VERSION ""

NS_ :

BS_:

BU_: CGM_HS TCM_HS RDCM_HS EPS_HS ECM_HS EBCM_HS BSM_HS BCM_HS

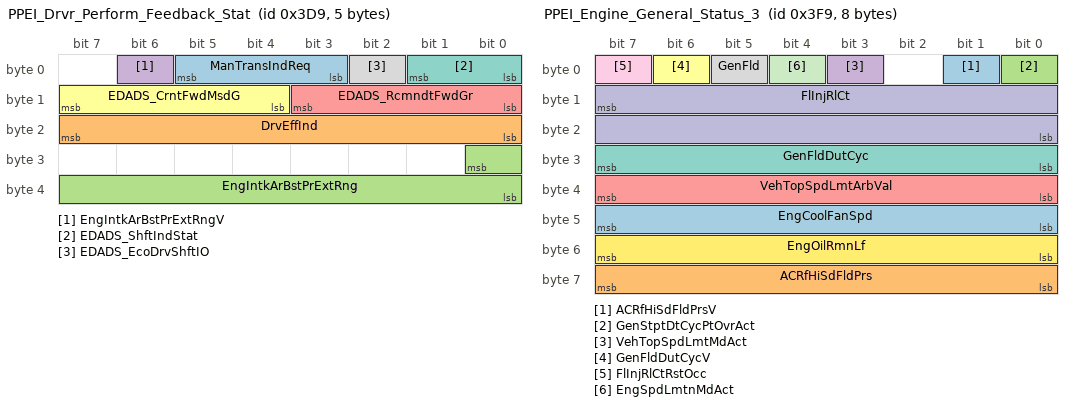
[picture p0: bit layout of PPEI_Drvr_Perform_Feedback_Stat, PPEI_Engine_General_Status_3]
BO_ 985 PPEI_Drvr_Perform_Feedback_Stat: 5 ECM_HS
 SG_ ManTransIndReq : 5|3@0+ (1,0) [0|7] ""  CGM_HS,BCM_HS
 SG_ DrvEffInd : 23|8@0- (0.78125,0) [-100|99.21875] "%"  CGM_HS,BCM_HS
 SG_ EngIntkArBstPrExtRng : 24|9@0+ (1,-110) [-110|401] "kPa"  CGM_HS,BCM_HS
 SG_ EngIntkArBstPrExtRngV : 6|1@0+ (1,0) [0|1] ""  CGM_HS,BCM_HS
 SG_ EDADS_RcmndtFwdGr : 11|4@0+ (1,0) [0|15] ""  CGM_HS,BCM_HS
 SG_ EDADS_CrntFwdMsdG : 15|4@0+ (1,0) [0|15] ""  CGM_HS,BCM_HS
 SG_ EDADS_ShftIndStat : 1|2@0+ (1,0) [0|3] ""  CGM_HS,BCM_HS
 SG_ EDADS_EcoDrvShftIO : 2|1@0+ (1,0) [0|1] ""  CGM_HS,BCM_HS

BO_ 1017 PPEI_Engine_General_Status_3: 8 ECM_HS
 SG_ ACRfHiSdFldPrsV : 1|1@0+ (1,0) [0|1] ""  CGM_HS,BSM_HS,BCM_HS
 SG_ ACRfHiSdFldPrs : 63|8@0+ (14,0) [0|3570] "kPaG"  CGM_HS,BSM_HS,BCM_HS
 SG_ GenStptDtCycPtOvrAct : 0|1@0+ (1,0) [0|1] ""  CGM_HS,BCM_HS
 SG_ VehTopSpdLmtMdAct : 3|1@0+ (1,0) [0|1] ""  CGM_HS,BCM_HS
 SG_ VehTopSpdLmtArbVal : 39|8@0+ (2,0) [0|510] "km / h"  CGM_HS,BCM_HS
 SG_ GenFldDutCycV : 6|1@0+ (1,0) [0|1] ""  CGM_HS,BCM_HS
 SG_ GenFldDutCyc : 31|8@0+ (0.392157,0) [0|100.000035] "%"  CGM_HS,BCM_HS
 SG_ GenFld : 5|1@0+ (1,0) [0|1] ""  CGM_HS,BCM_HS
 SG_ FlInjRlCtRstOcc : 7|1@0+ (1,0) [0|1] ""  CGM_HS,BSM_HS,BCM_HS
 SG_ FlInjRlCt : 15|16@0+ (3.05176E-005,0) [0|1.999970916] "liters"  CGM_HS,BSM_HS,BCM_HS
 SG_ EngSpdLmtnMdAct : 4|1@0+ (1,0) [0|1] ""  CGM_HS,BCM_HS
 SG_ EngOilRmnLf : 55|8@0+ (0.392157,0) [0|100.000035] "%"  CGM_HS,BCM_HS
 SG_ EngCoolFanSpd : 47|8@0+ (0.392157,0) [0|100.000035] "%"  CGM_HS,BSM_HS,BCM_HS

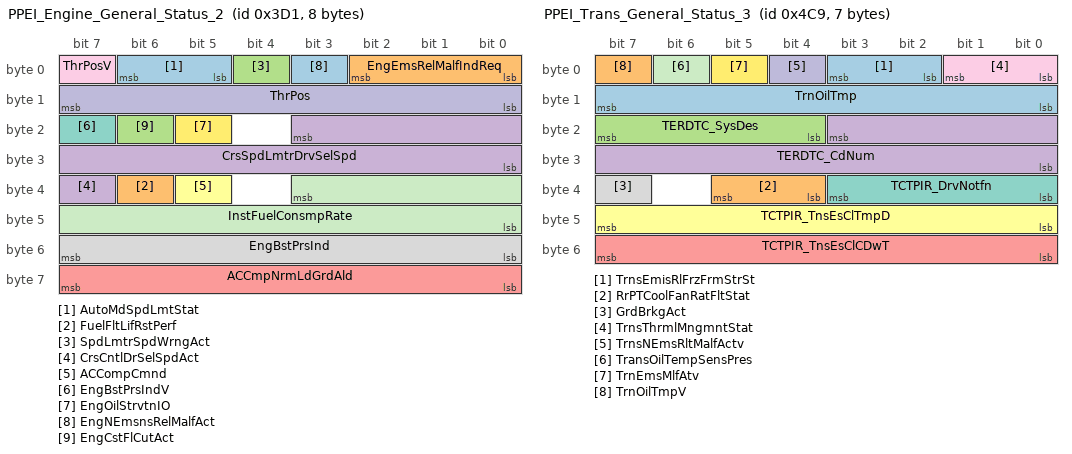
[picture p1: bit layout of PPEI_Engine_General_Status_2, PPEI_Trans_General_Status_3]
BO_ 977 PPEI_Engine_General_Status_2: 8 ECM_HS
 SG_ AutoMdSpdLmtStat : 6|2@0+ (1,0) [0|3] ""  CGM_HS,BCM_HS
 SG_ FuelFltLifRstPerf : 38|1@0+ (1,0) [0|1] ""  CGM_HS,BCM_HS
 SG_ SpdLmtrSpdWrngAct : 4|1@0+ (1,0) [0|1] ""  CGM_HS,BCM_HS
 SG_ CrsCntlDrSelSpdAct : 39|1@0+ (1,0) [0|1] ""  CGM_HS,BCM_HS
 SG_ ACCmpNrmLdGrdAld : 63|8@0+ (0.1,0) [0|25.5] "dm3/m/s"  CGM_HS,BCM_HS
 SG_ ACCompCmnd : 37|1@0+ (1,0) [0|1] ""  CGM_HS,TCM_HS,BCM_HS
 SG_ EngBstPrsIndV : 23|1@0+ (1,0) [0|1] ""  CGM_HS,BCM_HS
 SG_ EngBstPrsInd : 55|8@0+ (0.392157,0) [0|100.000035] "%"  CGM_HS,BCM_HS
 SG_ ThrPosV : 7|1@0+ (1,0) [0|1] ""  CGM_HS,BCM_HS
 SG_ ThrPos : 15|8@0+ (0.392157,0) [0|100.000035] "%"  CGM_HS,BCM_HS
 SG_ InstFuelConsmpRate : 35|12@0+ (0.025,0) [0|102.375] "ltrs/hr"  CGM_HS,BCM_HS
 SG_ EngOilStrvtnIO : 21|1@0+ (1,0) [0|1] ""  CGM_HS,BCM_HS
 SG_ EngNEmsnsRelMalfAct : 3|1@0+ (1,0) [0|1] ""  CGM_HS,BCM_HS
 SG_ EngEmsRelMalfIndReq : 2|3@0+ (1,0) [0|7] ""  CGM_HS,BCM_HS
 SG_ EngCstFlCutAct : 22|1@0+ (1,0) [0|1] ""  CGM_HS,TCM_HS,BSM_HS,BCM_HS
 SG_ CrsSpdLmtrDrvSelSpd : 19|12@0+ (0.0625,0) [0|255.9375] "km / h"  CGM_HS,TCM_HS,BCM_HS

BO_ 201 PPEI_Engine_General_Status_1: 8 ECM_HS
 SG_ EngCylDactEvntPndg : 54|1@0+ (1,0) [0|1] ""  CGM_HS
 SG_ DrThrtlOvrrdDetProtVal : 25|2@0+ (1,0) [0|3] ""  CGM_HS,EBCM_HS
 SG_ DrThrtlOvrdDetAlvRlCnt : 27|2@0+ (1,0) [0|3] ""  CGM_HS,EBCM_HS
 SG_ PT_BrkPedDscrtInpStatV : 41|1@0+ (1,0) [0|1] ""  CGM_HS,TCM_HS,EBCM_HS
 SG_ PT_BrkPedDscrtInpStat : 40|1@0+ (1,0) [0|1] ""  CGM_HS,TCM_HS,EBCM_HS
 SG_ PT_CrnkAct : 6|1@0+ (1,0) [0|1] ""  CGM_HS,EPS_HS,EBCM_HS,BSM_HS
 SG_ Eng12vStrtrMtrCmmdOn : 53|1@0+ (1,0) [0|1] ""  CGM_HS,TCM_HS,RDCM_HS,EPS_HS,EBCM_HS,BCM_HS
 SG_ EngCntrlRunCrnkTrmSt : 52|1@0+ (1,0) [0|1] ""  CGM_HS,TCM_HS,EBCM_HS,BSM_HS,BCM_HS
 SG_ EngAirIntBstPrV : 51|1@0+ (1,0) [0|1] ""  CGM_HS,EBCM_HS,BCM_HS
 SG_ EngAirIntBstPr : 63|8@0- (1,0) [-128|127] "kPaG"  CGM_HS,EBCM_HS,BCM_HS
 SG_ SpdLmtrSpdWrngEnbld : 47|1@0+ (1,0) [0|1] ""  CGM_HS,BCM_HS
 SG_ EngCylDeactMd : 43|2@0+ (1,0) [0|3] ""  CGM_HS,RDCM_HS,BCM_HS
 SG_ RmVhStrtEngRng : 55|1@0+ (1,0) [0|1] ""  CGM_HS,EBCM_HS,BCM_HS
 SG_ PFEngSpdCmndSpcd : 45|1@0+ (1,0) [0|1] ""  CGM_HS,BCM_HS
 SG_ PltfrmEngSpdCmdInhtRq : 44|1@0+ (1,0) [0|1] ""  CGM_HS,BCM_HS
 SG_ AccActPos : 39|8@0+ (0.392157,0) [0|100.000035] "%"  CGM_HS,TCM_HS,RDCM_HS,EBCM_HS,BSM_HS,BCM_HS
 SG_ CrsCntEnbld : 29|1@0+ (1,0) [0|1] ""  CGM_HS,EBCM_HS,BCM_HS
 SG_ CrsCntAtv : 30|1@0+ (1,0) [0|1] ""  CGM_HS,TCM_HS,RDCM_HS,EBCM_HS,BCM_HS
 SG_ DrvThrottlOvrrdDet : 28|1@0+ (1,0) [0|1] ""  CGM_HS,EBCM_HS,BCM_HS
 SG_ PTRunAbrt : 4|1@0+ (1,0) [0|1] ""  CGM_HS,BCM_HS
 SG_ PTO_PT_RunAbrtd : 3|1@0+ (1,0) [0|1] ""  CGM_HS,BCM_HS
 SG_ PTCrnkAbrted : 5|1@0+ (1,0) [0|1] ""  CGM_HS,BCM_HS
 SG_ EngSpdStat : 1|2@0+ (1,0) [0|3] ""  CGM_HS,TCM_HS,RDCM_HS,EPS_HS,EBCM_HS,BSM_HS,BCM_HS
 SG_ EngSpd : 15|16@0+ (0.25,0) [0|16383.75] "rpm"  CGM_HS,TCM_HS,RDCM_HS,EPS_HS,EBCM_HS,BSM_HS,BCM_HS
 SG_ EngRunAtv : 7|1@0+ (1,0) [0|1] ""  CGM_HS,RDCM_HS,EPS_HS,EBCM_HS,BSM_HS,BCM_HS
 SG_ EngIdlAtv : 2|1@0+ (1,0) [0|1] ""  CGM_HS,BCM_HS
 SG_ AccActPosV : 31|1@0+ (1,0) [0|1] ""  CGM_HS,TCM_HS,RDCM_HS,EBCM_HS,BSM_HS,BCM_HS

BO_ 501 PPEI_Trans_General_Status_2: 8 TCM_HS
 SG_ TrnsPattSelEcnMdOCm : 52|1@0+ (1,0) [0|1] ""  CGM_HS,ECM_HS
 SG_ TrnsFldPrsPrsnt : 51|1@0+ (1,0) [0|1] ""  CGM_HS,ECM_HS
 SG_ TrnsTrqCnvCltCmndMd : 7|3@0+ (1,0) [0|7] ""  CGM_HS,ECM_HS
 SG_ CltchPdlActPosV : 55|1@0+ (1,0) [0|1] ""  CGM_HS,RDCM_HS,ECM_HS,EBCM_HS
 SG_ CltchPdlActPos : 63|8@0+ (0.392157,0) [0|100.000035] "%"  CGM_HS,RDCM_HS,ECM_HS,EBCM_HS
 SG_ AutoTransGrSftDirect : 13|2@0+ (1,0) [0|3] ""  CGM_HS,RDCM_HS,ECM_HS,EBCM_HS
 SG_ ElcRngSelDrvAct : 39|1@0+ (1,0) [0|1] ""  CGM_HS,BCM_HS
 SG_ TmpDrvrShftCtlAct : 45|1@0+ (1,0) [0|1] ""  CGM_HS,BCM_HS
 SG_ EngRecDwnshftIO : 54|1@0+ (1,0) [0|1] ""  CGM_HS,BCM_HS
 SG_ CltStartSwAtvV : 38|1@0+ (1,0) [0|1] ""  CGM_HS,RDCM_HS,BCM_HS
 SG_ CltStartSwAtv : 37|1@0+ (1,0) [0|1] ""  CGM_HS,RDCM_HS,BCM_HS
 SG_ PropSysBrkLitsReqd : 53|1@0+ (1,0) [0|1] ""  CGM_HS,BCM_HS
 SG_ TrnsEngdStateV : 50|1@0+ (1,0) [0|1] ""  CGM_HS,RDCM_HS,EBCM_HS,BCM_HS
 SG_ TrnsEngdState : 49|2@0+ (1,0) [0|3] ""  CGM_HS,RDCM_HS,EBCM_HS,BCM_HS
 SG_ TrnsShftLvrLckRqd : 47|1@0+ (1,0) [0|1] ""  CGM_HS,BCM_HS
 SG_ TransTUDMdStat : 41|2@0+ (1,0) [0|3] ""  CGM_HS,ECM_HS,EBCM_HS,BCM_HS
 SG_ TrnCrpMdAtv : 46|1@0+ (1,0) [0|1] ""  CGM_HS,ECM_HS,BCM_HS
 SG_ TrnsSkpShftIO : 23|1@0+ (1,0) [0|1] ""  CGM_HS,BCM_HS
 SG_ TrnsSftMdStat : 34|3@0+ (1,0) [0|7] ""  CGM_HS,EBCM_HS,BCM_HS
 SG_ TrnsRngInhbtStat : 31|3@0+ (1,0) [0|7] ""  CGM_HS,BCM_HS
 SG_ TopTrvlCltchSwActV : 15|1@0+ (1,0) [0|1] ""  CGM_HS,RDCM_HS,EBCM_HS,BCM_HS
 SG_ TopTrvlCltchSwAct : 14|1@0+ (1,0) [0|1] ""  CGM_HS,RDCM_HS,EBCM_HS,BCM_HS
 SG_ EngRecmndUpshftIO : 22|1@0+ (1,0) [0|1] ""  CGM_HS,BCM_HS
 SG_ DrvtShftCntrlTrgtGear : 19|4@0+ (1,0) [0|15] ""  CGM_HS,BCM_HS
 SG_ DrShftCntrlReqDndIO : 21|1@0+ (1,0) [0|1] ""  CGM_HS,BCM_HS
 SG_ TrnShftPtrnActStat : 44|3@0+ (1,0) [0|7] ""  CGM_HS,EPS_HS,EBCM_HS,BCM_HS
 SG_ TrnsShftLvrPos : 27|4@0+ (1,0) [0|15] ""  CGM_HS,RDCM_HS,EPS_HS,ECM_HS,EBCM_HS,BSM_HS,BCM_HS
 SG_ TrnsShftLvrPosV : 28|1@0+ (1,0) [0|1] ""  CGM_HS,RDCM_HS,EPS_HS,ECM_HS,EBCM_HS,BSM_HS,BCM_HS
 SG_ AutoTransComndGear : 11|4@0+ (1,0) [0|15] ""  CGM_HS,RDCM_HS,ECM_HS,EBCM_HS,BCM_HS
 SG_ TransEstGear : 3|4@0+ (1,0) [0|15] ""  CGM_HS,RDCM_HS,EPS_HS,ECM_HS,EBCM_HS,BCM_HS
 SG_ TransEstGearV : 4|1@0+ (1,0) [0|1] ""  CGM_HS,RDCM_HS,EPS_HS,ECM_HS,EBCM_HS,BCM_HS

BO_ 1225 PPEI_Trans_General_Status_3: 7 TCM_HS
 SG_ TrnsEmisRlFrzFrmStrSt : 3|2@0+ (1,0) [0|3] ""  CGM_HS,ECM_HS
 SG_ RrPTCoolFanRatFltStat : 37|2@0+ (1,0) [0|3] ""  CGM_HS
 SG_ TERDTC_SysDes : 23|4@0+ (1,0) [0|15] ""  CGM_HS,ECM_HS
 SG_ TERDTC_CdNum : 19|12@0+ (1,0) [0|4095] ""  CGM_HS,ECM_HS
 SG_ TCTPIR_TnsEsClCDwT : 55|8@0+ (0.392157,0) [0|100.000035] "%"  CGM_HS,BCM_HS
 SG_ TCTPIR_TnsEsClTmpD : 47|8@0+ (0.392157,0) [0|100.000035] "%"  CGM_HS,BCM_HS
 SG_ TCTPIR_DrvNotfn : 35|4@0+ (1,0) [0|15] ""  CGM_HS,BCM_HS
 SG_ GrdBrkgAct : 39|1@0+ (1,0) [0|1] ""  CGM_HS,BCM_HS
 SG_ TrnsThrmlMngmntStat : 1|2@0+ (1,0) [0|3] ""  CGM_HS,BCM_HS
 SG_ TrnsNEmsRltMalfActv : 4|1@0+ (1,0) [0|1] ""  CGM_HS,BCM_HS
 SG_ TransOilTempSensPres : 6|1@0+ (1,0) [0|1] ""  CGM_HS,BSM_HS,BCM_HS
 SG_ TrnEmsMlfAtv : 5|1@0+ (1,0) [0|1] ""  CGM_HS,ECM_HS,BCM_HS
 SG_ TrnOilTmp : 15|8@0+ (1,-40) [-40|215] "deg C"  CGM_HS,ECM_HS,BSM_HS,BCM_HS
 SG_ TrnOilTmpV : 7|1@0+ (1,0) [0|1] ""  CGM_HS,ECM_HS,BSM_HS,BCM_HS

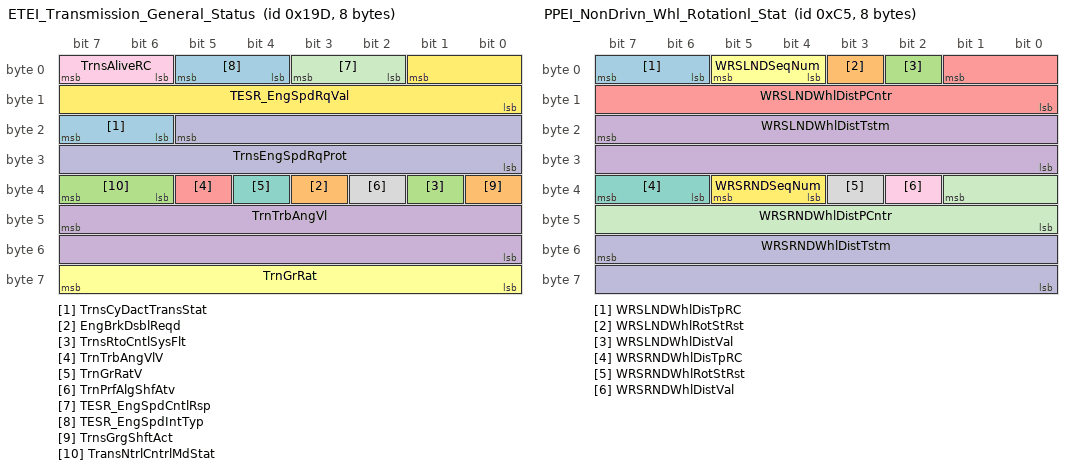
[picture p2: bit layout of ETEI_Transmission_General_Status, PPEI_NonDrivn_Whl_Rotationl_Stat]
BO_ 413 ETEI_Transmission_General_Status: 8 TCM_HS
 SG_ TrnsCyDactTransStat : 23|2@0+ (1,0) [0|3] ""  CGM_HS,ECM_HS
 SG_ EngBrkDsblReqd : 35|1@0+ (1,0) [0|1] ""  CGM_HS,ECM_HS
 SG_ TrnsRtoCntlSysFlt : 33|1@0+ (1,0) [0|1] ""  CGM_HS,ECM_HS
 SG_ TrnTrbAngVl : 47|16@0+ (0.25,0) [0|16383.75] "rpm"  CGM_HS,ECM_HS
 SG_ TrnTrbAngVlV : 37|1@0+ (1,0) [0|1] ""  CGM_HS,ECM_HS
 SG_ TrnGrRat : 63|8@0+ (0.03125,0) [0|7.96875] ""  CGM_HS,ECM_HS
 SG_ TrnGrRatV : 36|1@0+ (1,0) [0|1] ""  CGM_HS,ECM_HS
 SG_ TrnPrfAlgShfAtv : 34|1@0+ (1,0) [0|1] ""  CGM_HS,ECM_HS
 SG_ TrnsAliveRC : 7|2@0+ (1,0) [0|3] ""  CGM_HS,ECM_HS
 SG_ TrnsEngSpdRqProt : 21|14@0+ (1,0) [0|16383] ""  CGM_HS,ECM_HS
 SG_ TESR_EngSpdCntlRsp : 3|2@0+ (1,0) [0|3] ""  CGM_HS,ECM_HS
 SG_ TESR_EngSpdRqVal : 1|10@0+ (8,0) [0|8184] "rpm"  CGM_HS,ECM_HS
 SG_ TESR_EngSpdIntTyp : 5|2@0+ (1,0) [0|3] ""  CGM_HS,ECM_HS
 SG_ TrnsGrgShftAct : 32|1@0+ (1,0) [0|1] ""  CGM_HS,ECM_HS
 SG_ TransNtrlCntrlMdStat : 39|2@0+ (1,0) [0|3] ""  CGM_HS,ECM_HS,EBCM_HS,BCM_HS

BO_ 257 USDT_Req_to_All_HS_ECUs: 8 CGM_HS
 SG_ DgnInf : 7|64@0+ (1,0) [0|1.84467440737096E+019] ""  TCM_HS,RDCM_HS,ECM_HS,EPS_HS,EBCM_HS,BSM_HS,BCM_HS

BO_ 197 PPEI_NonDrivn_Whl_Rotationl_Stat: 8 EBCM_HS
 SG_ WRSLNDWhlDisTpRC : 7|2@0+ (1,0) [0|3] "counts"  CGM_HS,TCM_HS,RDCM_HS,ECM_HS,EPS_HS,BCM_HS
 SG_ WRSLNDWhlRotStRst : 3|1@0+ (1,0) [0|1] ""  CGM_HS,TCM_HS,RDCM_HS,ECM_HS,EPS_HS,BCM_HS
 SG_ WRSLNDWhlDistVal : 2|1@0+ (1,0) [0|1] ""  CGM_HS,TCM_HS,RDCM_HS,ECM_HS,EPS_HS,BCM_HS
 SG_ WRSLNDWhlDistTstm : 23|16@0+ (1,0) [0|65535] "counts"  CGM_HS,TCM_HS,RDCM_HS,ECM_HS,EPS_HS,BCM_HS
 SG_ WRSLNDWhlDistPCntr : 1|10@0+ (1,0) [0|1023] "counts"  CGM_HS,TCM_HS,RDCM_HS,ECM_HS,EPS_HS,BCM_HS
 SG_ WRSLNDSeqNum : 5|2@0+ (1,0) [0|3] "counts"  CGM_HS,TCM_HS,RDCM_HS,ECM_HS,EPS_HS,BCM_HS
 SG_ WRSRNDWhlDisTpRC : 39|2@0+ (1,0) [0|3] "counts"  CGM_HS,TCM_HS,RDCM_HS,ECM_HS,EPS_HS,BCM_HS
 SG_ WRSRNDWhlRotStRst : 35|1@0+ (1,0) [0|1] ""  CGM_HS,TCM_HS,RDCM_HS,ECM_HS,EPS_HS,BCM_HS
 SG_ WRSRNDWhlDistVal : 34|1@0+ (1,0) [0|1] ""  CGM_HS,TCM_HS,RDCM_HS,ECM_HS,EPS_HS,BCM_HS
 SG_ WRSRNDWhlDistTstm : 55|16@0+ (1,0) [0|65535] "counts"  CGM_HS,TCM_HS,RDCM_HS,ECM_HS,EPS_HS,BCM_HS
 SG_ WRSRNDWhlDistPCntr : 33|10@0+ (1,0) [0|1023] "counts"  CGM_HS,TCM_HS,RDCM_HS,ECM_HS,EPS_HS,BCM_HS
 SG_ WRSRNDSeqNum : 37|2@0+ (1,0) [0|3] "counts"  CGM_HS,TCM_HS,RDCM_HS,ECM_HS,EPS_HS,BCM_HS

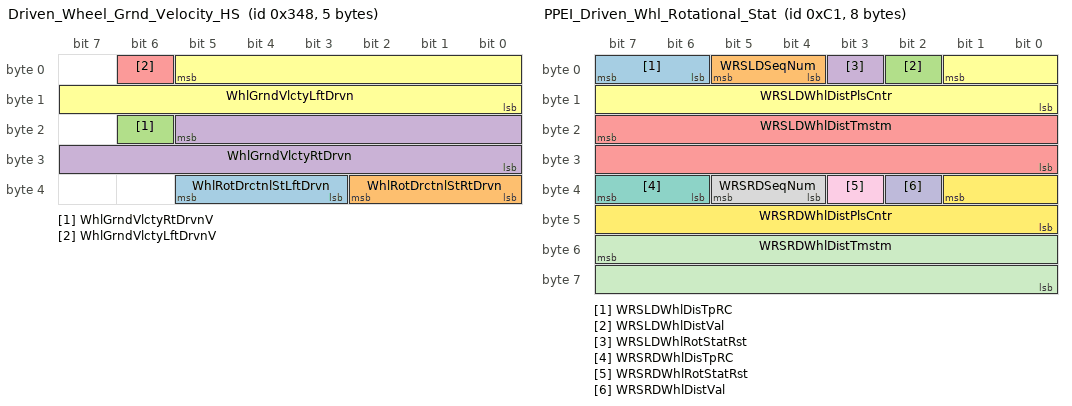
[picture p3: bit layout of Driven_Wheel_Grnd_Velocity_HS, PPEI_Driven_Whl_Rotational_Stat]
BO_ 840 Driven_Wheel_Grnd_Velocity_HS: 5 EBCM_HS
 SG_ WhlRotDrctnlStLftDrvn : 37|3@0+ (1,0) [0|7] ""  CGM_HS,EPS_HS
 SG_ WhlRotDrctnlStRtDrvn : 34|3@0+ (1,0) [0|7] ""  CGM_HS,EPS_HS
 SG_ WhlGrndVlctyRtDrvnV : 22|1@0+ (1,0) [0|1] ""  CGM_HS,RDCM_HS,EPS_HS,BCM_HS
 SG_ WhlGrndVlctyRtDrvn : 21|14@0+ (0.03125,0) [0|511.96875] "km / h"  CGM_HS,RDCM_HS,EPS_HS,BCM_HS
 SG_ WhlGrndVlctyLftDrvnV : 6|1@0+ (1,0) [0|1] ""  CGM_HS,RDCM_HS,EPS_HS,BCM_HS
 SG_ WhlGrndVlctyLftDrvn : 5|14@0+ (0.03125,0) [0|511.96875] "km / h"  CGM_HS,RDCM_HS,EPS_HS,BCM_HS

BO_ 193 PPEI_Driven_Whl_Rotational_Stat: 8 EBCM_HS
 SG_ WRSLDWhlDisTpRC : 7|2@0+ (1,0) [0|3] "counts"  CGM_HS,TCM_HS,RDCM_HS,ECM_HS,EPS_HS,BCM_HS
 SG_ WRSLDSeqNum : 5|2@0+ (1,0) [0|3] "counts"  CGM_HS,TCM_HS,RDCM_HS,ECM_HS,EPS_HS,BCM_HS
 SG_ WRSLDWhlDistVal : 2|1@0+ (1,0) [0|1] ""  CGM_HS,TCM_HS,RDCM_HS,ECM_HS,EPS_HS,BCM_HS
 SG_ WRSLDWhlRotStatRst : 3|1@0+ (1,0) [0|1] ""  CGM_HS,TCM_HS,RDCM_HS,ECM_HS,EPS_HS,BCM_HS
 SG_ WRSLDWhlDistTmstm : 23|16@0+ (1,0) [0|65535] "counts"  CGM_HS,TCM_HS,RDCM_HS,ECM_HS,EPS_HS,BCM_HS
 SG_ WRSLDWhlDistPlsCntr : 1|10@0+ (1,0) [0|1023] "counts"  CGM_HS,TCM_HS,RDCM_HS,ECM_HS,EPS_HS,BCM_HS
 SG_ WRSRDWhlDisTpRC : 39|2@0+ (1,0) [0|3] "counts"  CGM_HS,TCM_HS,RDCM_HS,ECM_HS,EPS_HS,BCM_HS
 SG_ WRSRDSeqNum : 37|2@0+ (1,0) [0|3] "counts"  CGM_HS,TCM_HS,RDCM_HS,ECM_HS,EPS_HS,BCM_HS
 SG_ WRSRDWhlRotStatRst : 35|1@0+ (1,0) [0|1] ""  CGM_HS,TCM_HS,RDCM_HS,ECM_HS,EPS_HS,BCM_HS
 SG_ WRSRDWhlDistVal : 34|1@0+ (1,0) [0|1] ""  CGM_HS,TCM_HS,RDCM_HS,ECM_HS,EPS_HS,BCM_HS
 SG_ WRSRDWhlDistTmstm : 55|16@0+ (1,0) [0|65535] "counts"  CGM_HS,TCM_HS,RDCM_HS,ECM_HS,EPS_HS,BCM_HS
 SG_ WRSRDWhlDistPlsCntr : 33|10@0+ (1,0) [0|1023] "counts"  CGM_HS,TCM_HS,RDCM_HS,ECM_HS,EPS_HS,BCM_HS

BO_ 761 PPEI_Chassis_General_Status_2: 7 EBCM_HS
 SG_ BrkSysHRBkCtrlAvail : 24|1@0+ (1,0) [0|1] ""  CGM_HS,TCM_HS
 SG_ BrkSysHRBkCtrlStat : 26|2@0+ (1,0) [0|3] ""  CGM_HS,TCM_HS
 SG_ BrkSysHSAAval : 27|1@0+ (1,0) [0|1] ""  CGM_HS,TCM_HS
 SG_ BrkSysHSAStat : 30|3@0+ (1,0) [0|7] ""  CGM_HS,TCM_HS
 SG_ HillDscntCtrlStatPVal : 17|2@0+ (1,0) [0|3] ""  CGM_HS,ECM_HS
 SG_ HillDscntCtrlStatARC : 19|2@0+ (1,0) [0|3] ""  CGM_HS,ECM_HS
 SG_ HillDscntCtrlStat : 21|2@0+ (1,0) [0|3] ""  CGM_HS,ECM_HS
 SG_ AutoBrkFeatInhbtPVal : 49|2@0+ (1,0) [0|3] ""  CGM_HS,TCM_HS,ECM_HS
 SG_ AutoBrkFeatInhbtARC : 51|2@0+ (1,0) [0|3] ""  CGM_HS,TCM_HS,ECM_HS
 SG_ ABFI_CollPrepSysInhbt : 52|1@0+ (1,0) [0|1] ""  CGM_HS,TCM_HS,ECM_HS
 SG_ ABFI_RrVirtlBmprInh : 53|1@0+ (1,0) [0|1] ""  CGM_HS,TCM_HS,ECM_HS
 SG_ ChsAVHStatPVal : 34|3@0+ (1,0) [0|7] ""  CGM_HS,ECM_HS
 SG_ ChsAVHStatARC : 36|2@0+ (1,0) [0|3] ""  CGM_HS,ECM_HS
 SG_ CAVHS_ACHActv : 37|1@0+ (1,0) [0|1] ""  CGM_HS,ECM_HS
 SG_ CAVHS_DSHEnbld : 38|1@0+ (1,0) [0|1] ""  CGM_HS,ECM_HS
 SG_ CAVHS_DSHActv : 39|1@0+ (1,0) [0|1] ""  CGM_HS,ECM_HS
 SG_ BrkPdlDrvApplPresV : 12|1@0+ (1,0) [0|1] ""  CGM_HS,TCM_HS,ECM_HS,EPS_HS
 SG_ BrkPdlDrvApplPres : 47|8@0+ (75,0) [0|19125] "kPa"  CGM_HS,TCM_HS,ECM_HS,EPS_HS
 SG_ AutoBrkPTReqStat : 15|3@0+ (1,0) [0|7] ""  CGM_HS,ECM_HS
 SG_ WhlSpdSnsgDTCIndex : 7|5@0+ (1,0) [0|31] ""  CGM_HS,ECM_HS
 SG_ WhlSpdSnsgDTCStat : 2|3@0+ (1,0) [0|7] ""  CGM_HS,ECM_HS
 SG_ SprTireSt : 10|3@0+ (1,0) [0|7] ""  CGM_HS,RDCM_HS,EPS_HS,BCM_HS

BO_ 489 PPEI_Chassis_General_Status_1: 8 EBCM_HS
 SG_ EnhDrvMdSwChUseRq : 53|1@0+ (1,0) [0|1] ""  CGM_HS,ECM_HS
 SG_ IMUDataMsk : 25|1@0+ (1,0) [0|1] ""  CGM_HS
 SG_ DrvIndpntBrkAppAct : 55|1@0+ (1,0) [0|1] ""  CGM_HS,TCM_HS,RDCM_HS,ECM_HS
 SG_ WhlSlpSt : 52|2@0+ (1,0) [0|3] ""  CGM_HS,TCM_HS,ECM_HS
 SG_ BSTGRReqdGear : 19|4@0+ (1,0) [0|15] ""  CGM_HS,TCM_HS
 SG_ BSTGRReqType : 21|2@0+ (1,0) [0|3] ""  CGM_HS,TCM_HS
 SG_ VehDynOvrUndrStr : 49|10@0- (0.5,0) [-256|255.5] "%"  CGM_HS,RDCM_HS,EPS_HS
 SG_ VhDynCntlSysSt : 39|3@0+ (1,0) [0|7] ""  CGM_HS,RDCM_HS,ECM_HS,EPS_HS
 SG_ TrnsBrkSysCltchRelRqd : 5|1@0+ (1,0) [0|1] ""  CGM_HS,TCM_HS
 SG_ TracCntrlSysDrIntnt : 26|1@0+ (1,0) [0|1] ""  CGM_HS,RDCM_HS,ECM_HS,EPS_HS
 SG_ VehDynOvrUndrStrV : 50|1@0+ (1,0) [0|1] ""  CGM_HS,RDCM_HS,EPS_HS
 SG_ TCSysEnbld : 27|1@0+ (1,0) [0|1] ""  CGM_HS,RDCM_HS,ECM_HS,TCM_HS,EPS_HS
 SG_ BrkPdlDrvAppPrsDetcdV : 7|1@0+ (1,0) [0|1] ""  CGM_HS,RDCM_HS,ECM_HS,TCM_HS,EPS_HS
 SG_ BrkPdlDrvAppPrsDetcd : 6|1@0+ (1,0) [0|1] ""  CGM_HS,RDCM_HS,ECM_HS,TCM_HS,EPS_HS
 SG_ ACCBrkngAct : 31|1@0+ (1,0) [0|1] ""  CGM_HS,ECM_HS,TCM_HS
 SG_ ABSFld : 29|1@0+ (1,0) [0|1] ""  CGM_HS,ECM_HS,TCM_HS,EPS_HS
 SG_ VSELatAccV : 4|1@0+ (1,0) [0|1] ""  CGM_HS,TCM_HS,RDCM_HS,ECM_HS,EPS_HS,BCM_HS
 SG_ VSELatAcc : 3|12@0- (0.015625,0) [-32|31.984375] "m/s^2"  CGM_HS,TCM_HS,RDCM_HS,ECM_HS,EPS_HS,BCM_HS
 SG_ VSEAct : 24|1@0+ (1,0) [0|1] ""  CGM_HS,TCM_HS,RDCM_HS,ECM_HS,EPS_HS,BCM_HS
 SG_ VehDynYawRateV : 36|1@0+ (1,0) [0|1] ""  CGM_HS,RDCM_HS,EPS_HS,BCM_HS
 SG_ VehDynYawRate : 35|12@0- (0.0625,0) [-128|127.9375] "deg/sec"  CGM_HS,RDCM_HS,EPS_HS,BCM_HS
 SG_ TCSysAtv : 28|1@0+ (1,0) [0|1] ""  CGM_HS,RDCM_HS,ECM_HS,TCM_HS,EPS_HS,BCM_HS
 SG_ ABSAtv : 30|1@0+ (1,0) [0|1] ""  CGM_HS,RDCM_HS,ECM_HS,TCM_HS,EPS_HS,BCM_HS

BO_ 381 Antilock_Brake_and_TC_Status_HS: 8 EBCM_HS
 SG_ BrkSysStCrwlModeOvrrd : 59|2@0+ (1,0) [0|3] ""  CGM_HS,ECM_HS
 SG_ BrkSysVTopSpdLimIO : 56|1@0+ (1,0) [0|1] ""  CGM_HS,BCM_HS
 SG_ ABSActIO : 57|1@0+ (1,0) [0|1] ""  CGM_HS,BCM_HS
 SG_ BrkPdLfStatIndRq : 62|3@0+ (1,0) [0|7] ""  CGM_HS,BCM_HS
 SG_ VehStbCmptvMdCstAvl : 48|1@0+ (1,0) [0|1] ""  CGM_HS,BCM_HS
 SG_ VehStbEnmntCstAvl : 49|1@0+ (1,0) [0|1] ""  CGM_HS,BCM_HS
 SG_ VehStbCmptvMdCurSt : 51|1@0+ (1,0) [0|1] ""  CGM_HS,BCM_HS
 SG_ VehStbEnhmntCurSt : 52|1@0+ (1,0) [0|1] ""  CGM_HS,BCM_HS
 SG_ TCSTempDsblReqIO : 63|1@0+ (1,0) [0|1] ""  CGM_HS,BCM_HS
 SG_ TCSysCstAvl : 50|1@0+ (1,0) [0|1] ""  CGM_HS,BCM_HS
 SG_ TCSysCurSt : 53|1@0+ (1,0) [0|1] ""  CGM_HS,BCM_HS
 SG_ TracAndStbScrnCnfg : 55|2@0+ (1,0) [0|3] ""  CGM_HS,BCM_HS
 SG_ HillDesCtrlRedVehSpIO : 39|1@0+ (1,0) [0|1] ""  CGM_HS,BCM_HS
 SG_ EBDFailed : 23|1@0+ (1,0) [0|1] ""  CGM_HS,BCM_HS
 SG_ StWhAnVDA : 17|1@0+ (1,0) [0|1] ""  CGM_HS,RDCM_HS,BCM_HS
 SG_ TirePrsLowIO : 9|1@0+ (1,0) [0|1] ""  CGM_HS,BCM_HS
 SG_ VaccBoostFailure : 16|1@0+ (1,0) [0|1] ""  CGM_HS,BCM_HS
 SG_ VSESysPrs : 1|1@0+ (1,0) [0|1] ""  CGM_HS,BCM_HS
 SG_ HalfSysFail : 18|1@0+ (1,0) [0|1] ""  CGM_HS,BCM_HS
 SG_ ActVehAccel : 35|12@0- (0.01,0) [-20.48|20.47] "m/s^2"  CGM_HS,BSM_HS,BCM_HS
 SG_ ActVehAccelV : 20|1@0+ (1,0) [0|1] ""  CGM_HS,BSM_HS,BCM_HS
 SG_ BksOvht : 8|1@0+ (1,0) [0|1] ""  CGM_HS,BCM_HS
 SG_ TCSysPr : 10|1@0+ (1,0) [0|1] ""  CGM_HS,BCM_HS
 SG_ ABSPr : 22|1@0+ (1,0) [0|1] ""  CGM_HS,BCM_HS
 SG_ TreInfMonSysRstPrfmd : 11|1@0+ (1,0) [0|1] ""  CGM_HS,BCM_HS
 SG_ ABSIO : 12|1@0+ (1,0) [0|1] ""  CGM_HS,BCM_HS
 SG_ BrkPadWrnIO : 0|1@0+ (1,0) [0|1] ""  CGM_HS,BCM_HS
 SG_ VehStabEnhmntMd : 15|3@0+ (1,0) [0|7] ""  CGM_HS,RDCM_HS,ECM_HS,BCM_HS
 SG_ VehStabEnhmntStat : 4|3@0+ (1,0) [0|7] ""  CGM_HS,ECM_HS,EPS_HS,BCM_HS
 SG_ TCSysOpMd : 7|3@0+ (1,0) [0|7] ""  RDCM_HS,ECM_HS,EPS_HS,CGM_HS,BCM_HS
 SG_ TCSysOpStat : 38|3@0+ (1,0) [0|7] ""  ECM_HS,CGM_HS,BCM_HS
 SG_ BrkSysVTopSpdLimVal : 31|8@0+ (2,0) [0|510] "km / h"  ECM_HS,CGM_HS,BCM_HS
 SG_ BrkSysRedBrkTlltlReq : 19|1@0+ (1,0) [0|1] ""  CGM_HS,BCM_HS
 SG_ BrkSysBrkLtsReqd : 21|1@0+ (1,0) [0|1] ""  CGM_HS,BCM_HS

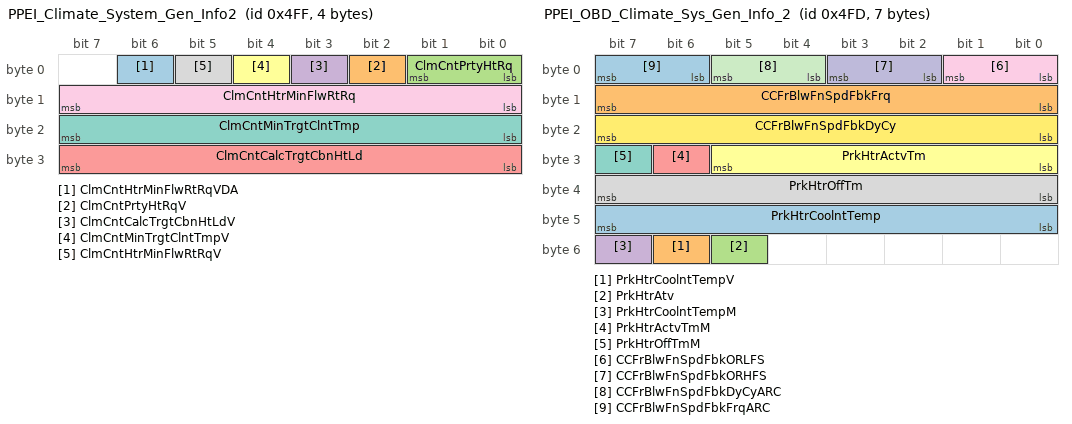
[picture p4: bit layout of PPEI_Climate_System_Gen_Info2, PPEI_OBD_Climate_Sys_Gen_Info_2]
BO_ 1279 PPEI_Climate_System_Gen_Info2: 4 BCM_HS
 SG_ ClmCntHtrMinFlwRtRqVDA : 6|1@0+ (1,0) [0|1] ""  CGM_HS,ECM_HS
 SG_ ClmCntPrtyHtRqV : 2|1@0+ (1,0) [0|1] ""  CGM_HS,ECM_HS
 SG_ ClmCntPrtyHtRq : 1|2@0+ (1,0) [0|3] ""  CGM_HS,ECM_HS
 SG_ ClmCntCalcTrgtCbnHtLdV : 3|1@0+ (1,0) [0|1] ""  CGM_HS,ECM_HS
 SG_ ClmCntCalcTrgtCbnHtLd : 31|8@0+ (0.12549,0) [0|32] "kW"  CGM_HS,ECM_HS
 SG_ ClmCntMinTrgtClntTmpV : 4|1@0+ (1,0) [0|1] ""  CGM_HS,ECM_HS
 SG_ ClmCntMinTrgtClntTmp : 23|8@0+ (0.39216,0) [0|100.0008] "degC"  CGM_HS,ECM_HS
 SG_ ClmCntHtrMinFlwRtRqV : 5|1@0+ (1,0) [0|1] ""  CGM_HS,ECM_HS
 SG_ ClmCntHtrMinFlwRtRq : 15|8@0+ (0.25098,0) [0|63.9999] "l/min"  CGM_HS,ECM_HS

BO_ 573 OTA_Electric_Pwr_Readiness_HS: 1 BCM_HS
 SG_ RmtRflshElecPwrRdness : 7|8@0+ (0.025,0) [0|6.375] "AmpHour"  CGM_HS

BO_ 1277 PPEI_OBD_Climate_Sys_Gen_Info_2: 7 BCM_HS
 SG_ PrkHtrCoolntTemp : 47|8@0+ (1,-40) [-40|215] "deg C"  CGM_HS,ECM_HS
 SG_ PrkHtrCoolntTempV : 54|1@0+ (1,0) [0|1] ""  CGM_HS,ECM_HS
 SG_ PrkHtrAtv : 53|1@0+ (1,0) [0|1] ""  CGM_HS,ECM_HS
 SG_ PrkHtrCoolntTempM : 55|1@0+ (1,0) [0|1] ""  CGM_HS,ECM_HS
 SG_ PrkHtrActvTmM : 30|1@0+ (1,0) [0|1] ""  CGM_HS,ECM_HS
 SG_ PrkHtrActvTm : 29|6@0+ (1,0) [0|63] "min"  CGM_HS,ECM_HS
 SG_ PrkHtrOffTmM : 31|1@0+ (1,0) [0|1] ""  CGM_HS,ECM_HS
 SG_ PrkHtrOffTm : 39|8@0+ (2,0) [0|510] "min"  CGM_HS,ECM_HS
 SG_ CCFrBlwFnSpdFbkORLFS : 1|2@0+ (1,0) [0|3] ""  CGM_HS,ECM_HS
 SG_ CCFrBlwFnSpdFbkORHFS : 3|2@0+ (1,0) [0|3] ""  CGM_HS,ECM_HS
 SG_ CCFrBlwFnSpdFbkDyCyARC : 5|2@0+ (1,0) [0|3] ""  CGM_HS,ECM_HS
 SG_ CCFrBlwFnSpdFbkDyCy : 23|8@0+ (0.392157,0) [0|100.000035] "%"  CGM_HS,ECM_HS
 SG_ CCFrBlwFnSpdFbkFrqARC : 7|2@0+ (1,0) [0|3] ""  CGM_HS,ECM_HS
 SG_ CCFrBlwFnSpdFbkFrq : 15|8@0+ (1.568627,0) [0|399.999885] "Hz"  CGM_HS,ECM_HS

BO_ 2034 CCP_Data_Transmission_Object_HS: 8 BCM_HS
 SG_ DgnInf : 7|64@0+ (1,0) [0|1.84467440737096E+019] ""  CGM_HS

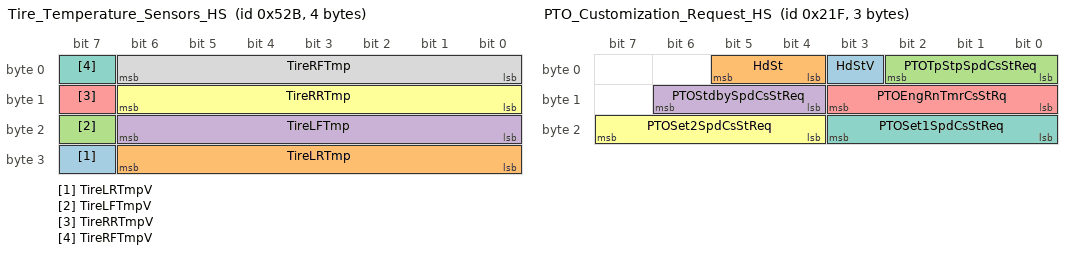
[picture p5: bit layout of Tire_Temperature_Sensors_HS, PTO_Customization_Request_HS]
BO_ 1323 Tire_Temperature_Sensors_HS: 4 BCM_HS
 SG_ TireLRTmpV : 31|1@0+ (1,0) [0|1] ""  CGM_HS,EBCM_HS,RDCM_HS
 SG_ TireLRTmp : 30|7@0+ (1,-20) [-20|107] "deg C"  CGM_HS,EBCM_HS,RDCM_HS
 SG_ TireLFTmpV : 23|1@0+ (1,0) [0|1] ""  CGM_HS,EBCM_HS,RDCM_HS
 SG_ TireLFTmp : 22|7@0+ (1,-20) [-20|107] "deg C"  CGM_HS,EBCM_HS,RDCM_HS
 SG_ TireRRTmpV : 15|1@0+ (1,0) [0|1] ""  CGM_HS,EBCM_HS,RDCM_HS
 SG_ TireRRTmp : 14|7@0+ (1,-20) [-20|107] "deg C"  CGM_HS,EBCM_HS,RDCM_HS
 SG_ TireRFTmpV : 7|1@0+ (1,0) [0|1] ""  CGM_HS,EBCM_HS,RDCM_HS
 SG_ TireRFTmp : 6|7@0+ (1,-20) [-20|107] "deg C"  CGM_HS,EBCM_HS,RDCM_HS

BO_ 543 PTO_Customization_Request_HS: 3 BCM_HS
 SG_ HdStV : 3|1@0+ (1,0) [0|1] ""  CGM_HS
 SG_ HdSt : 5|2@0+ (1,0) [0|3] ""  CGM_HS
 SG_ PTOTpStpSpdCsStReq : 2|3@0+ (1,0) [0|7] ""  CGM_HS
 SG_ PTOStdbySpdCsStReq : 14|3@0+ (1,0) [0|7] ""  CGM_HS
 SG_ PTOEngRnTmrCsStRq : 11|4@0+ (1,0) [0|15] ""  CGM_HS
 SG_ PTOSet2SpdCsStReq : 23|4@0+ (1,0) [0|15] ""  CGM_HS
 SG_ PTOSet1SpdCsStReq : 19|4@0+ (1,0) [0|15] ""  CGM_HS

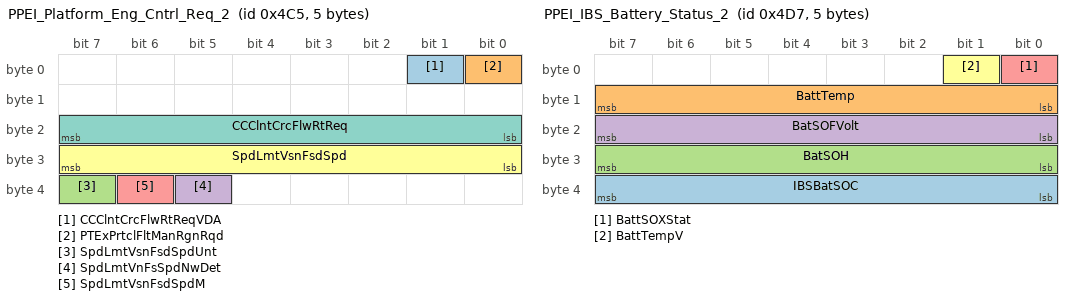
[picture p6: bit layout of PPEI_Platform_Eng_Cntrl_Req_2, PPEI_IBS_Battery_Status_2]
BO_ 1221 PPEI_Platform_Eng_Cntrl_Req_2: 5 BCM_HS
 SG_ CCClntCrcFlwRtReqVDA : 1|1@0+ (1,0) [0|1] ""  CGM_HS,ECM_HS
 SG_ PTExPrtclFltManRgnRqd : 0|1@0+ (1,0) [0|1] ""  CGM_HS,ECM_HS
 SG_ SpdLmtVsnFsdSpdUnt : 39|1@0+ (1,0) [0|1] ""  CGM_HS,ECM_HS
 SG_ SpdLmtVnFsSpdNwDet : 37|1@0+ (1,0) [0|1] ""  CGM_HS,ECM_HS
 SG_ SpdLmtVsnFsdSpdM : 38|1@0+ (1,0) [0|1] ""  CGM_HS,ECM_HS
 SG_ SpdLmtVsnFsdSpd : 31|8@0+ (1,0) [0|255] ""  CGM_HS,ECM_HS
 SG_ CCClntCrcFlwRtReq : 23|8@0+ (0.392157,0) [0|100.000035] "%"  CGM_HS,ECM_HS

BO_ 1239 PPEI_IBS_Battery_Status_2: 5 BCM_HS
 SG_ IBSBatSOC : 39|8@0+ (0.392157,0) [0|100.000035] "%"  CGM_HS,ECM_HS
 SG_ BattTemp : 15|8@0+ (1,-40) [-40|215] "deg C"  CGM_HS,ECM_HS
 SG_ BatSOH : 31|8@0+ (0.392157,0) [0|100.000035] "%"  CGM_HS,ECM_HS
 SG_ BatSOFVolt : 23|8@0+ (0.05,0) [0|12.75] "volts"  CGM_HS,ECM_HS
 SG_ BattSOXStat : 0|1@0+ (1,0) [0|1] ""  CGM_HS,ECM_HS
 SG_ BattTempV : 1|1@0+ (1,0) [0|1] ""  CGM_HS,ECM_HS

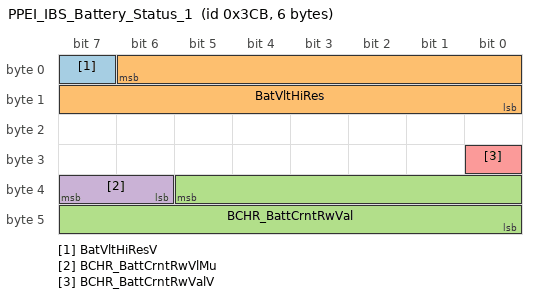
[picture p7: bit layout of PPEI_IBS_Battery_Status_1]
BO_ 971 PPEI_IBS_Battery_Status_1: 6 BCM_HS
 SG_ BatVltHiResV : 7|1@0+ (1,0) [0|1] ""  ECM_HS,CGM_HS
 SG_ BatVltHiRes : 6|15@0+ (0.001,0) [0|32.767] "volts"  ECM_HS,CGM_HS
 SG_ BCHR_BattCrntRwVal : 37|14@0+ (0.001,-8.192) [-8.192|8.191] ""  ECM_HS,CGM_HS
 SG_ BCHR_BattCrntRwVlMu : 39|2@0+ (1,0) [0|3] ""  ECM_HS,CGM_HS
 SG_ BCHR_BattCrntRwValV : 24|1@0+ (1,0) [0|1] ""  ECM_HS,CGM_HS

BO_TX_BU_ 2034 : CGM_HS,BCM_HS;
CM_ SG_ 977 ACCmpNrmLdGrdAld "dm3/m/s = dm3/minute/second";
CM_ SG_ 201 EngRunAtv "Indication from powertrain that the engine is running (Has RPM > 0)";
CM_ SG_ 501 TrnShftPtrnActStat "(PT = Powertrain)";
CM_ SG_ 1277 PrkHtrCoolntTempM "Shortname of the signal in CSD is PrkHtrCoolntTempMsk. This is a known discrepancy.";
CM_ SG_ 1239 BatSOH "State of Health = the aging state of the Battery";
BA_DEF_ SG_  "GenSigSendOnInit" ENUM  "Not Initialized","Application","Handler","DLCLS","DLCHS","DLCCE","DLCFO";
BA_DEF_ SG_  "GenSigSendType" ENUM  "not used","not used","not used","not used","not used","not used","not used","NoSigSendType","not used","not used","OnAnyChange","OnChangeIfActive","OnDelta","DLCLS","DLCHS","DLCCE","DLCFO";
BA_DEF_ SG_  "GenSigDeltaValue" INT 0 0;
BA_DEF_ SG_  "VNSigAllNodes" ENUM  "No","Yes","DLCLS","DLCHS","DLCCE","DLCFO";
BA_DEF_ SG_  "VNSigSLHSSharedDiagnostic" ENUM  "No","Yes","DLCLS","DLCHS","DLCCE","DLCFO";
BA_DEF_ SG_  "VNSigSLHS_VNReq" ENUM  "No","Yes","DLCLS","DLCHS","DLCCE","DLCFO";
BA_DEF_ SG_  "SignalType" STRING ;
BA_DEF_ SG_  "PacketOrder" INT 0 65535;
BA_DEF_ SG_  "SignalLongName" STRING ;
BA_DEF_ SG_  "GenSigStartValue" INT 0 65535;
BA_DEF_ SG_  "TxSignalSendOnInit" ENUM  "Not Initialized","Application","Handler";
BA_DEF_ BO_  "GenMsgILSupport" ENUM  "No","Yes","DLCLS","DLCHS","DLCCE","DLCFO";
BA_DEF_ BO_  "AppGenMsgCycleTime" INT 0 0;
BA_DEF_ BO_  "TpApplType" STRING ;
BA_DEF_ BO_  "Prio" INT 0 7;
BA_DEF_ BO_  "MessageSubnet" ENUM  "LS","MS","HS","CE","PE","HV","FO","S1","HE","LE","HE2","DLCLS","DLCHS","DLCCE","DLCFO","vector_leerstring";
BA_DEF_ BO_  "DiagState" ENUM  "No","Yes";
BA_DEF_ BO_  "GenMsgIlSupport" ENUM  "No","Yes";
BA_DEF_ BO_  "GenMsgStartDelayTime" INT 0 100000;
BA_DEF_ BO_  "GenMsgDelayTime" INT 0 100000;
BA_DEF_ BO_  "GenMsgCycleTime" INT 0 100000;
BA_DEF_ BO_  "GenMsgSendType" ENUM  "cyclicX","spontanX","cyclicIfActiveX","spontanWithDelay","cyclicAndSpontanX","cyclicAndSpontanWithDelay","spontanWithRepitition","cyclicIfActiveAndSpontanWD";
BA_DEF_ BO_  "DiagResponse" ENUM  "No","Yes";
BA_DEF_ BO_  "DiagRequest" ENUM  "No","Yes";
BA_DEF_ BO_  "NmMessage" ENUM  "No","Yes";
BA_DEF_REL_ BU_SG_REL_  "GenSigSuprvResp" ENUM  "None","Notify App","Substitute Default","DLCLS","DLCHS","DLCCE","DLCFO";
BA_DEF_REL_ BU_SG_REL_  "GenSigSuprvRespSubValue" INT 0 65535;
BA_DEF_REL_ BU_SG_REL_  "GenSigRxStartValue" STRING ;
BA_DEF_REL_ BU_SG_REL_  "GenSigVDAFailResp" ENUM  "No","Yes","DLCLS","DLCHS","DLCCE","DLCFO";
BA_DEF_REL_ BU_SG_REL_  "GenSigVDAFailComment" STRING ;
BA_DEF_REL_ BU_SG_REL_  "GenSigVBitRespComment" STRING ;
BA_DEF_REL_ BU_SG_REL_  "GenSigVBitResp" ENUM  "No","Yes","DLCLS","DLCHS","DLCCE","DLCFO";
BA_DEF_REL_ BU_SG_REL_  "GenSigSuprvRespComment" STRING ;
BA_DEF_REL_ BU_SG_REL_  "GenSigTimeoutMsg" HEX 0 268435455;
BA_DEF_REL_ BU_SG_REL_  "GenSigTimeoutTime" INT 0 5000;
BA_DEF_DEF_  "GenSigSendOnInit" "Not Initialized";
BA_DEF_DEF_  "GenSigSendType" "NoSigSendType";
BA_DEF_DEF_  "GenSigDeltaValue" 0;
BA_DEF_DEF_  "VNSigAllNodes" "No";
BA_DEF_DEF_  "VNSigSLHSSharedDiagnostic" "No";
BA_DEF_DEF_  "VNSigSLHS_VNReq" "No";
BA_DEF_DEF_  "SignalType" "";
BA_DEF_DEF_  "PacketOrder" 0;
BA_DEF_DEF_  "SignalLongName" "";
BA_DEF_DEF_  "GenSigStartValue" 0;
BA_DEF_DEF_  "TxSignalSendOnInit" "Not Initialized";
BA_DEF_DEF_  "GenMsgILSupport" "Yes";
BA_DEF_DEF_  "AppGenMsgCycleTime" 0;
BA_DEF_DEF_  "TpApplType" "";
BA_DEF_DEF_  "Prio" 0;
BA_DEF_DEF_  "MessageSubnet" "LS";
BA_DEF_DEF_  "DiagState" "No";
BA_DEF_DEF_  "GenMsgIlSupport" "Yes";
BA_DEF_DEF_  "GenMsgStartDelayTime" 0;
BA_DEF_DEF_  "GenMsgDelayTime" 0;
BA_DEF_DEF_  "GenMsgCycleTime" 0;
BA_DEF_DEF_  "GenMsgSendType" "spontanX";
BA_DEF_DEF_  "DiagResponse" "No";
BA_DEF_DEF_  "DiagRequest" "No";
BA_DEF_DEF_  "NmMessage" "No";
BA_DEF_DEF_REL_ "GenSigSuprvResp" "None";
BA_DEF_DEF_REL_ "GenSigSuprvRespSubValue" 0;
BA_DEF_DEF_REL_ "GenSigRxStartValue" "";
BA_DEF_DEF_REL_ "GenSigVDAFailResp" "No";
BA_DEF_DEF_REL_ "GenSigVDAFailComment" "";
BA_DEF_DEF_REL_ "GenSigVBitRespComment" "";
BA_DEF_DEF_REL_ "GenSigVBitResp" "No";
BA_DEF_DEF_REL_ "GenSigSuprvRespComment" "";
BA_DEF_DEF_REL_ "GenSigTimeoutMsg" 0;
BA_DEF_DEF_REL_ "GenSigTimeoutTime" 0;
BA_ "GenMsgSendType" BO_ 985 0;
BA_ "GenMsgCycleTime" BO_ 985 100;
BA_ "MessageSubnet" BO_ 985 2;
BA_ "GenMsgSendType" BO_ 1017 0;
BA_ "GenMsgCycleTime" BO_ 1017 250;
BA_ "MessageSubnet" BO_ 1017 2;
BA_ "GenMsgSendType" BO_ 977 0;
BA_ "GenMsgCycleTime" BO_ 977 100;
BA_ "MessageSubnet" BO_ 977 2;
BA_ "GenMsgSendType" BO_ 201 0;
BA_ "GenMsgCycleTime" BO_ 201 12;
BA_ "MessageSubnet" BO_ 201 2;
BA_ "GenMsgSendType" BO_ 501 0;
BA_ "GenMsgCycleTime" BO_ 501 25;
BA_ "MessageSubnet" BO_ 501 2;
BA_ "GenMsgSendType" BO_ 1225 0;
BA_ "GenMsgCycleTime" BO_ 1225 500;
BA_ "MessageSubnet" BO_ 1225 2;
BA_ "GenMsgSendType" BO_ 413 0;
BA_ "GenMsgCycleTime" BO_ 413 25;
BA_ "MessageSubnet" BO_ 413 2;
BA_ "DiagRequest" BO_ 257 1;
BA_ "DiagState" BO_ 257 1;
BA_ "MessageSubnet" BO_ 257 2;
BA_ "GenMsgILSupport" BO_ 257 0;
BA_ "GenMsgSendType" BO_ 197 0;
BA_ "GenMsgCycleTime" BO_ 197 10;
BA_ "MessageSubnet" BO_ 197 2;
BA_ "GenMsgSendType" BO_ 840 0;
BA_ "GenMsgCycleTime" BO_ 840 50;
BA_ "MessageSubnet" BO_ 840 2;
BA_ "GenMsgSendType" BO_ 193 0;
BA_ "GenMsgCycleTime" BO_ 193 10;
BA_ "MessageSubnet" BO_ 193 2;
BA_ "GenMsgSendType" BO_ 761 0;
BA_ "GenMsgCycleTime" BO_ 761 50;
BA_ "MessageSubnet" BO_ 761 2;
BA_ "GenMsgSendType" BO_ 489 0;
BA_ "GenMsgCycleTime" BO_ 489 20;
BA_ "MessageSubnet" BO_ 489 2;
BA_ "GenMsgSendType" BO_ 381 0;
BA_ "GenMsgCycleTime" BO_ 381 100;
BA_ "MessageSubnet" BO_ 381 2;
BA_ "GenMsgSendType" BO_ 1279 0;
BA_ "GenMsgCycleTime" BO_ 1279 1000;
BA_ "MessageSubnet" BO_ 1279 2;
BA_ "GenMsgSendType" BO_ 573 0;
BA_ "GenMsgCycleTime" BO_ 573 2000;
BA_ "MessageSubnet" BO_ 573 2;
BA_ "GenMsgSendType" BO_ 1277 0;
BA_ "GenMsgCycleTime" BO_ 1277 1000;
BA_ "MessageSubnet" BO_ 1277 2;
BA_ "DiagResponse" BO_ 2034 1;
BA_ "MessageSubnet" BO_ 2034 2;
BA_ "GenMsgSendType" BO_ 1323 0;
BA_ "GenMsgCycleTime" BO_ 1323 1000;
BA_ "GenMsgStartDelayTime" BO_ 1323 50;
BA_ "MessageSubnet" BO_ 1323 2;
BA_ "GenMsgSendType" BO_ 543 0;
BA_ "GenMsgCycleTime" BO_ 543 100;
BA_ "GenMsgStartDelayTime" BO_ 543 110;
BA_ "MessageSubnet" BO_ 543 2;
BA_ "GenMsgSendType" BO_ 1221 0;
BA_ "GenMsgCycleTime" BO_ 1221 500;
BA_ "GenMsgStartDelayTime" BO_ 1221 10;
BA_ "MessageSubnet" BO_ 1221 2;
BA_ "GenMsgSendType" BO_ 1239 0;
BA_ "GenMsgCycleTime" BO_ 1239 500;
BA_ "GenMsgStartDelayTime" BO_ 1239 20;
BA_ "MessageSubnet" BO_ 1239 2;
BA_ "GenMsgSendType" BO_ 971 0;
BA_ "GenMsgCycleTime" BO_ 971 100;
BA_ "GenMsgStartDelayTime" BO_ 971 90;
BA_ "MessageSubnet" BO_ 971 2;
BA_ "SignalLongName" SG_ 985 ManTransIndReq "Manual Transmission Indication Request";
BA_ "SignalType" SG_ 985 ManTransIndReq "ENM";
BA_ "VNSigAllNodes" SG_ 985 ManTransIndReq 1;
BA_ "GenSigSendType" SG_ 985 ManTransIndReq 10;
BA_ "SignalLongName" SG_ 985 DrvEffInd "Drive Efficiency Indication";
BA_ "SignalType" SG_ 985 DrvEffInd "SNM";
BA_ "VNSigAllNodes" SG_ 985 DrvEffInd 1;
BA_ "SignalLongName" SG_ 985 EngIntkArBstPrExtRng "Engine Intake Air Boost Pressure Extended Range";
BA_ "SignalType" SG_ 985 EngIntkArBstPrExtRng "UNM";
BA_ "VNSigAllNodes" SG_ 985 EngIntkArBstPrExtRng 1;
BA_ "SignalLongName" SG_ 985 EngIntkArBstPrExtRngV "Engine Intake Air Boost Pressure Extended Range Validity";
BA_ "SignalType" SG_ 985 EngIntkArBstPrExtRngV "ENM";
BA_ "VNSigAllNodes" SG_ 985 EngIntkArBstPrExtRngV 1;
BA_ "SignalLongName" SG_ 985 EDADS_RcmndtFwdGr "ECO Drive Assist Display Status : Recommended Forward Gear";
BA_ "PacketOrder" SG_ 985 EDADS_RcmndtFwdGr 4;
BA_ "SignalType" SG_ 985 EDADS_RcmndtFwdGr "ENM";
BA_ "VNSigAllNodes" SG_ 985 EDADS_RcmndtFwdGr 1;
BA_ "GenSigSendType" SG_ 985 EDADS_RcmndtFwdGr 10;
BA_ "SignalLongName" SG_ 985 EDADS_CrntFwdMsdG "ECO Drive Assist Display Status : Current Forward Measured Gear";
BA_ "PacketOrder" SG_ 985 EDADS_CrntFwdMsdG 3;
BA_ "SignalType" SG_ 985 EDADS_CrntFwdMsdG "ENM";
BA_ "VNSigAllNodes" SG_ 985 EDADS_CrntFwdMsdG 1;
BA_ "GenSigSendType" SG_ 985 EDADS_CrntFwdMsdG 10;
BA_ "SignalLongName" SG_ 985 EDADS_ShftIndStat "ECO Drive Assist Display Status : Shift Indication Status";
BA_ "PacketOrder" SG_ 985 EDADS_ShftIndStat 2;
BA_ "SignalType" SG_ 985 EDADS_ShftIndStat "ENM";
BA_ "VNSigAllNodes" SG_ 985 EDADS_ShftIndStat 1;
BA_ "GenSigSendType" SG_ 985 EDADS_ShftIndStat 10;
BA_ "SignalLongName" SG_ 985 EDADS_EcoDrvShftIO "ECO Drive Assist Display Status : ECO Drive Assist Shift Indication On";
BA_ "PacketOrder" SG_ 985 EDADS_EcoDrvShftIO 1;
BA_ "SignalType" SG_ 985 EDADS_EcoDrvShftIO "BLN";
BA_ "VNSigAllNodes" SG_ 985 EDADS_EcoDrvShftIO 1;
BA_ "GenSigSendType" SG_ 985 EDADS_EcoDrvShftIO 10;
BA_ "SignalLongName" SG_ 1017 ACRfHiSdFldPrsV "Air Conditioning Refrigerant High Side Fluid Pressure Validity";
BA_ "SignalType" SG_ 1017 ACRfHiSdFldPrsV "ENM";
BA_ "VNSigAllNodes" SG_ 1017 ACRfHiSdFldPrsV 1;
BA_ "SignalLongName" SG_ 1017 ACRfHiSdFldPrs "Air Conditioning Refrigerant High Side Fluid Pressure";
BA_ "SignalType" SG_ 1017 ACRfHiSdFldPrs "UNM";
BA_ "VNSigAllNodes" SG_ 1017 ACRfHiSdFldPrs 1;
BA_ "SignalLongName" SG_ 1017 GenStptDtCycPtOvrAct "Generator Setpoint Duty Cycle Powertrain Override Active";
BA_ "SignalType" SG_ 1017 GenStptDtCycPtOvrAct "BLN";
BA_ "VNSigAllNodes" SG_ 1017 GenStptDtCycPtOvrAct 1;
BA_ "SignalLongName" SG_ 1017 VehTopSpdLmtMdAct "Vehicle Top Speed Limit Mode Active";
BA_ "SignalType" SG_ 1017 VehTopSpdLmtMdAct "BLN";
BA_ "VNSigAllNodes" SG_ 1017 VehTopSpdLmtMdAct 1;
BA_ "SignalLongName" SG_ 1017 VehTopSpdLmtArbVal "Vehicle Top Speed Limit Arbitrated Value";
BA_ "SignalType" SG_ 1017 VehTopSpdLmtArbVal "UNM";
BA_ "VNSigAllNodes" SG_ 1017 VehTopSpdLmtArbVal 1;
BA_ "SignalLongName" SG_ 1017 GenFldDutCycV "Generator Field Duty Cycle Validity";
BA_ "SignalType" SG_ 1017 GenFldDutCycV "ENM";
BA_ "VNSigAllNodes" SG_ 1017 GenFldDutCycV 1;
BA_ "SignalLongName" SG_ 1017 GenFldDutCyc "Generator Field Duty Cycle";
BA_ "SignalType" SG_ 1017 GenFldDutCyc "UNM";
BA_ "VNSigAllNodes" SG_ 1017 GenFldDutCyc 1;
BA_ "SignalLongName" SG_ 1017 GenFld "Generator Failed";
BA_ "SignalType" SG_ 1017 GenFld "BLN";
BA_ "VNSigAllNodes" SG_ 1017 GenFld 1;
BA_ "SignalLongName" SG_ 1017 FlInjRlCtRstOcc "Fuel Injected Rolling Count Reset Occurred";
BA_ "SignalType" SG_ 1017 FlInjRlCtRstOcc "BLN";
BA_ "VNSigAllNodes" SG_ 1017 FlInjRlCtRstOcc 1;
BA_ "SignalLongName" SG_ 1017 FlInjRlCt "Fuel Injected Rolling Count";
BA_ "SignalType" SG_ 1017 FlInjRlCt "UNM";
BA_ "VNSigAllNodes" SG_ 1017 FlInjRlCt 1;
BA_ "SignalLongName" SG_ 1017 EngSpdLmtnMdAct "Engine Speed Limitation Mode Active";
BA_ "SignalType" SG_ 1017 EngSpdLmtnMdAct "BLN";
BA_ "VNSigAllNodes" SG_ 1017 EngSpdLmtnMdAct 1;
BA_ "SignalLongName" SG_ 1017 EngOilRmnLf "Engine Oil Remaining Life";
BA_ "SignalType" SG_ 1017 EngOilRmnLf "UNM";
BA_ "VNSigAllNodes" SG_ 1017 EngOilRmnLf 1;
BA_ "SignalLongName" SG_ 1017 EngCoolFanSpd "Engine Cooling Fan Speed";
BA_ "SignalType" SG_ 1017 EngCoolFanSpd "UNM";
BA_ "VNSigAllNodes" SG_ 1017 EngCoolFanSpd 1;
BA_ "SignalLongName" SG_ 977 AutoMdSpdLmtStat "Auto Mode Speed Limit Status";
BA_ "SignalType" SG_ 977 AutoMdSpdLmtStat "ENM";
BA_ "VNSigAllNodes" SG_ 977 AutoMdSpdLmtStat 1;
BA_ "SignalLongName" SG_ 977 FuelFltLifRstPerf "Fuel Filter Life Reset Performed";
BA_ "SignalType" SG_ 977 FuelFltLifRstPerf "BLN";
BA_ "VNSigAllNodes" SG_ 977 FuelFltLifRstPerf 1;
BA_ "SignalLongName" SG_ 977 SpdLmtrSpdWrngAct "Speed Limiter/Speed Warning Active";
BA_ "SignalType" SG_ 977 SpdLmtrSpdWrngAct "BLN";
BA_ "VNSigAllNodes" SG_ 977 SpdLmtrSpdWrngAct 1;
BA_ "SignalLongName" SG_ 977 CrsCntlDrSelSpdAct "Cruise Control Driver Selected Speed Active";
BA_ "SignalType" SG_ 977 CrsCntlDrSelSpdAct "BLN";
BA_ "VNSigAllNodes" SG_ 977 CrsCntlDrSelSpdAct 1;
BA_ "SignalLongName" SG_ 977 ACCmpNrmLdGrdAld "Air Conditioning Compressor Normalized Load Gradient Allowed";
BA_ "SignalType" SG_ 977 ACCmpNrmLdGrdAld "UNM";
BA_ "VNSigAllNodes" SG_ 977 ACCmpNrmLdGrdAld 1;
BA_ "SignalLongName" SG_ 977 ACCompCmnd "Air Conditioning Compressor Command";
BA_ "SignalType" SG_ 977 ACCompCmnd "ENM";
BA_ "VNSigAllNodes" SG_ 977 ACCompCmnd 1;
BA_ "SignalLongName" SG_ 977 EngBstPrsIndV "Engine Boost Pressure Indication Validity";
BA_ "SignalType" SG_ 977 EngBstPrsIndV "ENM";
BA_ "VNSigAllNodes" SG_ 977 EngBstPrsIndV 1;
BA_ "SignalLongName" SG_ 977 EngBstPrsInd "Engine Boost Pressure Indication";
BA_ "SignalType" SG_ 977 EngBstPrsInd "UNM";
BA_ "VNSigAllNodes" SG_ 977 EngBstPrsInd 1;
BA_ "SignalLongName" SG_ 977 ThrPosV "Throttle Position Validity";
BA_ "SignalType" SG_ 977 ThrPosV "ENM";
BA_ "VNSigAllNodes" SG_ 977 ThrPosV 1;
BA_ "SignalLongName" SG_ 977 ThrPos "Throttle Position";
BA_ "SignalType" SG_ 977 ThrPos "UNM";
BA_ "VNSigAllNodes" SG_ 977 ThrPos 1;
BA_ "SignalLongName" SG_ 977 InstFuelConsmpRate "Instantaneous Fuel Consumption Rate";
BA_ "SignalType" SG_ 977 InstFuelConsmpRate "UNM";
BA_ "VNSigAllNodes" SG_ 977 InstFuelConsmpRate 1;
BA_ "SignalLongName" SG_ 977 EngOilStrvtnIO "Engine Oil Starvation Indication On";
BA_ "SignalType" SG_ 977 EngOilStrvtnIO "BLN";
BA_ "VNSigAllNodes" SG_ 977 EngOilStrvtnIO 1;
BA_ "SignalLongName" SG_ 977 EngNEmsnsRelMalfAct "Engine Non Emissions Related Malfunction Active";
BA_ "SignalType" SG_ 977 EngNEmsnsRelMalfAct "BLN";
BA_ "VNSigAllNodes" SG_ 977 EngNEmsnsRelMalfAct 1;
BA_ "SignalLongName" SG_ 977 EngEmsRelMalfIndReq "Engine Emissions Related Malfunction Indication Request";
BA_ "SignalType" SG_ 977 EngEmsRelMalfIndReq "ENM";
BA_ "VNSigAllNodes" SG_ 977 EngEmsRelMalfIndReq 1;
BA_ "SignalLongName" SG_ 977 EngCstFlCutAct "Engine Coast Fuel Cut Off Active";
BA_ "SignalType" SG_ 977 EngCstFlCutAct "BLN";
BA_ "VNSigAllNodes" SG_ 977 EngCstFlCutAct 1;
BA_ "SignalLongName" SG_ 977 CrsSpdLmtrDrvSelSpd "Cruise and Speed Limiter Driver Selected Speed";
BA_ "SignalType" SG_ 977 CrsSpdLmtrDrvSelSpd "UNM";
BA_ "VNSigAllNodes" SG_ 977 CrsSpdLmtrDrvSelSpd 1;
BA_ "SignalLongName" SG_ 201 EngCylDactEvntPndg "Engine Cylinder Deactivation Event Pending";
BA_ "SignalType" SG_ 201 EngCylDactEvntPndg "BLN";
BA_ "VNSigAllNodes" SG_ 201 EngCylDactEvntPndg 1;
BA_ "SignalLongName" SG_ 201 DrThrtlOvrrdDetProtVal "Driver Throttle Override Detected Protection Value";
BA_ "SignalType" SG_ 201 DrThrtlOvrrdDetProtVal "UNM";
BA_ "VNSigAllNodes" SG_ 201 DrThrtlOvrrdDetProtVal 1;
BA_ "SignalLongName" SG_ 201 DrThrtlOvrdDetAlvRlCnt "Driver Throttle Override Detection Alive Rolling Count";
BA_ "SignalType" SG_ 201 DrThrtlOvrdDetAlvRlCnt "UNM";
BA_ "VNSigAllNodes" SG_ 201 DrThrtlOvrdDetAlvRlCnt 1;
BA_ "SignalLongName" SG_ 201 PT_BrkPedDscrtInpStatV "Powertrain Brake Pedal Discrete Input Status Validity";
BA_ "SignalType" SG_ 201 PT_BrkPedDscrtInpStatV "ENM";
BA_ "VNSigAllNodes" SG_ 201 PT_BrkPedDscrtInpStatV 1;
BA_ "SignalLongName" SG_ 201 PT_BrkPedDscrtInpStat "Powertrain Brake Pedal Discrete Input Status";
BA_ "SignalType" SG_ 201 PT_BrkPedDscrtInpStat "ENM";
BA_ "VNSigAllNodes" SG_ 201 PT_BrkPedDscrtInpStat 1;
BA_ "SignalLongName" SG_ 201 PT_CrnkAct "Powertrain Crank Active";
BA_ "SignalType" SG_ 201 PT_CrnkAct "BLN";
BA_ "VNSigAllNodes" SG_ 201 PT_CrnkAct 1;
BA_ "SignalLongName" SG_ 201 Eng12vStrtrMtrCmmdOn "Engine 12 Volt Starter Motor Commanded On";
BA_ "SignalType" SG_ 201 Eng12vStrtrMtrCmmdOn "BLN";
BA_ "VNSigAllNodes" SG_ 201 Eng12vStrtrMtrCmmdOn 1;
BA_ "SignalLongName" SG_ 201 EngCntrlRunCrnkTrmSt "Engine Controller Run Crank Terminal Status";
BA_ "SignalType" SG_ 201 EngCntrlRunCrnkTrmSt "ENM";
BA_ "VNSigAllNodes" SG_ 201 EngCntrlRunCrnkTrmSt 1;
BA_ "SignalLongName" SG_ 201 EngAirIntBstPrV "Engine Intake Air Boost Pressure Validity";
BA_ "SignalType" SG_ 201 EngAirIntBstPrV "ENM";
BA_ "VNSigAllNodes" SG_ 201 EngAirIntBstPrV 1;
BA_ "SignalLongName" SG_ 201 EngAirIntBstPr "Engine Intake Air Boost Pressure";
BA_ "SignalType" SG_ 201 EngAirIntBstPr "SNM";
BA_ "VNSigAllNodes" SG_ 201 EngAirIntBstPr 1;
BA_ "SignalLongName" SG_ 201 SpdLmtrSpdWrngEnbld "Speed Limiter/Speed Warning Enabled";
BA_ "SignalType" SG_ 201 SpdLmtrSpdWrngEnbld "BLN";
BA_ "VNSigAllNodes" SG_ 201 SpdLmtrSpdWrngEnbld 1;
BA_ "SignalLongName" SG_ 201 EngCylDeactMd "Engine Cylinder Deactivation Mode";
BA_ "SignalType" SG_ 201 EngCylDeactMd "ENM";
BA_ "VNSigAllNodes" SG_ 201 EngCylDeactMd 1;
BA_ "SignalLongName" SG_ 201 RmVhStrtEngRng "Remote Vehicle Start Engine Running";
BA_ "SignalType" SG_ 201 RmVhStrtEngRng "BLN";
BA_ "VNSigAllNodes" SG_ 201 RmVhStrtEngRng 1;
BA_ "SignalLongName" SG_ 201 PFEngSpdCmndSpcd "Platform Engine Speed Command Superceded";
BA_ "SignalType" SG_ 201 PFEngSpdCmndSpcd "BLN";
BA_ "VNSigAllNodes" SG_ 201 PFEngSpdCmndSpcd 1;
BA_ "SignalLongName" SG_ 201 PltfrmEngSpdCmdInhtRq "Platform Engine Speed Command Inhibit Request";
BA_ "SignalType" SG_ 201 PltfrmEngSpdCmdInhtRq "ENM";
BA_ "VNSigAllNodes" SG_ 201 PltfrmEngSpdCmdInhtRq 1;
BA_ "SignalLongName" SG_ 201 AccActPos "Accelerator Actual Position";
BA_ "SignalType" SG_ 201 AccActPos "UNM";
BA_ "VNSigAllNodes" SG_ 201 AccActPos 1;
BA_ "SignalLongName" SG_ 201 CrsCntEnbld "Cruise Control Enabled";
BA_ "SignalType" SG_ 201 CrsCntEnbld "BLN";
BA_ "VNSigAllNodes" SG_ 201 CrsCntEnbld 1;
BA_ "GenSigSendOnInit" SG_ 201 CrsCntEnbld 1;
BA_ "SignalLongName" SG_ 201 CrsCntAtv "Cruise Control Active";
BA_ "SignalType" SG_ 201 CrsCntAtv "BLN";
BA_ "VNSigAllNodes" SG_ 201 CrsCntAtv 1;
BA_ "GenSigSendType" SG_ 201 CrsCntAtv 10;
BA_ "GenSigSendOnInit" SG_ 201 CrsCntAtv 2;
BA_ "SignalLongName" SG_ 201 DrvThrottlOvrrdDet "Driver Throttle Override Detected";
BA_ "SignalType" SG_ 201 DrvThrottlOvrrdDet "BLN";
BA_ "VNSigAllNodes" SG_ 201 DrvThrottlOvrrdDet 1;
BA_ "SignalLongName" SG_ 201 PTRunAbrt "Powertrain Run Aborted";
BA_ "SignalType" SG_ 201 PTRunAbrt "BLN";
BA_ "VNSigAllNodes" SG_ 201 PTRunAbrt 1;
BA_ "SignalLongName" SG_ 201 PTO_PT_RunAbrtd "Power Take Off Powertrain Run Aborted";
BA_ "SignalType" SG_ 201 PTO_PT_RunAbrtd "BLN";
BA_ "VNSigAllNodes" SG_ 201 PTO_PT_RunAbrtd 1;
BA_ "SignalLongName" SG_ 201 PTCrnkAbrted "Powertrain Crank Aborted";
BA_ "SignalType" SG_ 201 PTCrnkAbrted "BLN";
BA_ "VNSigAllNodes" SG_ 201 PTCrnkAbrted 1;
BA_ "SignalLongName" SG_ 201 EngSpdStat "Engine Speed Status";
BA_ "SignalType" SG_ 201 EngSpdStat "ENM";
BA_ "VNSigAllNodes" SG_ 201 EngSpdStat 1;
BA_ "SignalLongName" SG_ 201 EngSpd "Engine Speed";
BA_ "SignalType" SG_ 201 EngSpd "UNM";
BA_ "VNSigAllNodes" SG_ 201 EngSpd 1;
BA_ "SignalLongName" SG_ 201 EngRunAtv "Engine Run Active";
BA_ "SignalType" SG_ 201 EngRunAtv "BLN";
BA_ "VNSigAllNodes" SG_ 201 EngRunAtv 1;
BA_ "GenSigSendType" SG_ 201 EngRunAtv 10;
BA_ "SignalLongName" SG_ 201 EngIdlAtv "Engine Idle Active";
BA_ "SignalType" SG_ 201 EngIdlAtv "BLN";
BA_ "VNSigAllNodes" SG_ 201 EngIdlAtv 1;
BA_ "SignalLongName" SG_ 201 AccActPosV "Accelerator Actual Position Validity";
BA_ "SignalType" SG_ 201 AccActPosV "ENM";
BA_ "VNSigAllNodes" SG_ 201 AccActPosV 1;
BA_ "SignalLongName" SG_ 501 TrnsPattSelEcnMdOCm "Transmission Pattern Selection Economy Mode Override Commanded";
BA_ "SignalType" SG_ 501 TrnsPattSelEcnMdOCm "BLN";
BA_ "VNSigAllNodes" SG_ 501 TrnsPattSelEcnMdOCm 1;
BA_ "SignalLongName" SG_ 501 TrnsFldPrsPrsnt "Transmission Fluid Pressure Present";
BA_ "SignalType" SG_ 501 TrnsFldPrsPrsnt "BLN";
BA_ "VNSigAllNodes" SG_ 501 TrnsFldPrsPrsnt 1;
BA_ "GenSigStartValue" SG_ 501 TrnsTrqCnvCltCmndMd 7;
BA_ "SignalLongName" SG_ 501 TrnsTrqCnvCltCmndMd "Transmission Torque Converter Clutch Commanded Mode";
BA_ "SignalType" SG_ 501 TrnsTrqCnvCltCmndMd "ENM";
BA_ "VNSigAllNodes" SG_ 501 TrnsTrqCnvCltCmndMd 1;
BA_ "SignalLongName" SG_ 501 CltchPdlActPosV "Clutch Pedal Actual Position Validity";
BA_ "SignalType" SG_ 501 CltchPdlActPosV "ENM";
BA_ "VNSigAllNodes" SG_ 501 CltchPdlActPosV 1;
BA_ "SignalLongName" SG_ 501 CltchPdlActPos "Clutch Pedal Actual Position";
BA_ "SignalType" SG_ 501 CltchPdlActPos "UNM";
BA_ "VNSigAllNodes" SG_ 501 CltchPdlActPos 1;
BA_ "SignalLongName" SG_ 501 AutoTransGrSftDirect "Automatic Transmission Gear Shift Direction";
BA_ "SignalType" SG_ 501 AutoTransGrSftDirect "ENM";
BA_ "VNSigAllNodes" SG_ 501 AutoTransGrSftDirect 1;
BA_ "SignalLongName" SG_ 501 ElcRngSelDrvAct "Electronic Range Selection In Drive Active";
BA_ "SignalType" SG_ 501 ElcRngSelDrvAct "BLN";
BA_ "VNSigAllNodes" SG_ 501 ElcRngSelDrvAct 1;
BA_ "SignalLongName" SG_ 501 TmpDrvrShftCtlAct "Temporary Driver Shift Control Active";
BA_ "SignalType" SG_ 501 TmpDrvrShftCtlAct "BLN";
BA_ "VNSigAllNodes" SG_ 501 TmpDrvrShftCtlAct 1;
BA_ "SignalLongName" SG_ 501 EngRecDwnshftIO "Engine Recommended Downshift Indication On";
BA_ "SignalType" SG_ 501 EngRecDwnshftIO "BLN";
BA_ "VNSigAllNodes" SG_ 501 EngRecDwnshftIO 1;
BA_ "SignalLongName" SG_ 501 CltStartSwAtvV "Clutch Start Switch Active Validity";
BA_ "SignalType" SG_ 501 CltStartSwAtvV "ENM";
BA_ "VNSigAllNodes" SG_ 501 CltStartSwAtvV 1;
BA_ "GenSigStartValue" SG_ 501 CltStartSwAtv 1;
BA_ "SignalLongName" SG_ 501 CltStartSwAtv "Clutch Start Switch Active";
BA_ "SignalType" SG_ 501 CltStartSwAtv "BLN";
BA_ "VNSigAllNodes" SG_ 501 CltStartSwAtv 1;
BA_ "SignalLongName" SG_ 501 PropSysBrkLitsReqd "Propulsion System Brake Lights Requested";
BA_ "SignalType" SG_ 501 PropSysBrkLitsReqd "BLN";
BA_ "VNSigAllNodes" SG_ 501 PropSysBrkLitsReqd 1;
BA_ "SignalLongName" SG_ 501 TrnsEngdStateV "Transmission Engaged State Validity";
BA_ "SignalType" SG_ 501 TrnsEngdStateV "ENM";
BA_ "VNSigAllNodes" SG_ 501 TrnsEngdStateV 1;
BA_ "SignalLongName" SG_ 501 TrnsEngdState "Transmission Engaged State";
BA_ "SignalType" SG_ 501 TrnsEngdState "ENM";
BA_ "VNSigAllNodes" SG_ 501 TrnsEngdState 1;
BA_ "SignalLongName" SG_ 501 TrnsShftLvrLckRqd "Transmission Shift Lever Lock Requested";
BA_ "SignalType" SG_ 501 TrnsShftLvrLckRqd "BLN";
BA_ "VNSigAllNodes" SG_ 501 TrnsShftLvrLckRqd 1;
BA_ "SignalLongName" SG_ 501 TransTUDMdStat "Transmission Tap Up/Tap Down Mode Status";
BA_ "SignalType" SG_ 501 TransTUDMdStat "ENM";
BA_ "VNSigAllNodes" SG_ 501 TransTUDMdStat 1;
BA_ "SignalLongName" SG_ 501 TrnCrpMdAtv "Transmission Creep Mode Active";
BA_ "SignalType" SG_ 501 TrnCrpMdAtv "BLN";
BA_ "VNSigAllNodes" SG_ 501 TrnCrpMdAtv 1;
BA_ "SignalLongName" SG_ 501 TrnsSkpShftIO "Transmission Skip Shift Indication On";
BA_ "SignalType" SG_ 501 TrnsSkpShftIO "BLN";
BA_ "VNSigAllNodes" SG_ 501 TrnsSkpShftIO 1;
BA_ "SignalLongName" SG_ 501 TrnsSftMdStat "Transmission Shift Mode Status";
BA_ "SignalType" SG_ 501 TrnsSftMdStat "ENM";
BA_ "VNSigAllNodes" SG_ 501 TrnsSftMdStat 1;
BA_ "SignalLongName" SG_ 501 TrnsRngInhbtStat "Transmission Range Inhibit Status";
BA_ "SignalType" SG_ 501 TrnsRngInhbtStat "ENM";
BA_ "VNSigAllNodes" SG_ 501 TrnsRngInhbtStat 1;
BA_ "SignalLongName" SG_ 501 TopTrvlCltchSwActV "Top of Travel Clutch Switch Active Validity";
BA_ "SignalType" SG_ 501 TopTrvlCltchSwActV "ENM";
BA_ "VNSigAllNodes" SG_ 501 TopTrvlCltchSwActV 1;
BA_ "SignalLongName" SG_ 501 TopTrvlCltchSwAct "Top of Travel Clutch Switch Active";
BA_ "SignalType" SG_ 501 TopTrvlCltchSwAct "BLN";
BA_ "VNSigAllNodes" SG_ 501 TopTrvlCltchSwAct 1;
BA_ "SignalLongName" SG_ 501 EngRecmndUpshftIO "Engine Recommended Upshift Indication On";
BA_ "SignalType" SG_ 501 EngRecmndUpshftIO "BLN";
BA_ "VNSigAllNodes" SG_ 501 EngRecmndUpshftIO 1;
BA_ "SignalLongName" SG_ 501 DrvtShftCntrlTrgtGear "Driver Shift Control Target Gear";
BA_ "SignalType" SG_ 501 DrvtShftCntrlTrgtGear "ENM";
BA_ "VNSigAllNodes" SG_ 501 DrvtShftCntrlTrgtGear 1;
BA_ "SignalLongName" SG_ 501 DrShftCntrlReqDndIO "Driver Shift Control Request Denied Indication On";
BA_ "SignalType" SG_ 501 DrShftCntrlReqDndIO "BLN";
BA_ "VNSigAllNodes" SG_ 501 DrShftCntrlReqDndIO 1;
BA_ "SignalLongName" SG_ 501 TrnShftPtrnActStat "Transmission Shift Pattern Active Status";
BA_ "SignalType" SG_ 501 TrnShftPtrnActStat "ENM";
BA_ "VNSigAllNodes" SG_ 501 TrnShftPtrnActStat 1;
BA_ "SignalLongName" SG_ 501 TrnsShftLvrPos "Transmission Shift Lever Position";
BA_ "SignalType" SG_ 501 TrnsShftLvrPos "ENM";
BA_ "VNSigAllNodes" SG_ 501 TrnsShftLvrPos 1;
BA_ "SignalLongName" SG_ 501 TrnsShftLvrPosV "Transmission Shift Lever Position Validity";
BA_ "SignalType" SG_ 501 TrnsShftLvrPosV "ENM";
BA_ "VNSigAllNodes" SG_ 501 TrnsShftLvrPosV 1;
BA_ "GenSigStartValue" SG_ 501 AutoTransComndGear 15;
BA_ "SignalLongName" SG_ 501 AutoTransComndGear "Automatic Transmission Commanded Gear";
BA_ "SignalType" SG_ 501 AutoTransComndGear "ENM";
BA_ "VNSigAllNodes" SG_ 501 AutoTransComndGear 1;
BA_ "GenSigStartValue" SG_ 501 TransEstGear 15;
BA_ "SignalLongName" SG_ 501 TransEstGear "Transmission Estimated Gear";
BA_ "SignalType" SG_ 501 TransEstGear "ENM";
BA_ "VNSigAllNodes" SG_ 501 TransEstGear 1;
BA_ "SignalLongName" SG_ 501 TransEstGearV "Transmission Estimated Gear Validity";
BA_ "SignalType" SG_ 501 TransEstGearV "ENM";
BA_ "VNSigAllNodes" SG_ 501 TransEstGearV 1;
BA_ "SignalLongName" SG_ 1225 TrnsEmisRlFrzFrmStrSt "Transmission Emission Related Freeze Frame Storage Status";
BA_ "SignalType" SG_ 1225 TrnsEmisRlFrzFrmStrSt "ENM";
BA_ "VNSigAllNodes" SG_ 1225 TrnsEmisRlFrzFrmStrSt 1;
BA_ "SignalLongName" SG_ 1225 RrPTCoolFanRatFltStat "Rear Powertrain Cooling Fan Rationality Fault Status";
BA_ "SignalType" SG_ 1225 RrPTCoolFanRatFltStat "ENM";
BA_ "VNSigAllNodes" SG_ 1225 RrPTCoolFanRatFltStat 1;
BA_ "SignalLongName" SG_ 1225 TERDTC_SysDes "Transmission Emissions Related DTC : System Designator";
BA_ "PacketOrder" SG_ 1225 TERDTC_SysDes 1;
BA_ "SignalType" SG_ 1225 TERDTC_SysDes "ENM";
BA_ "VNSigAllNodes" SG_ 1225 TERDTC_SysDes 1;
BA_ "SignalLongName" SG_ 1225 TERDTC_CdNum "Transmission Emissions Related DTC : Code Number";
BA_ "PacketOrder" SG_ 1225 TERDTC_CdNum 2;
BA_ "SignalType" SG_ 1225 TERDTC_CdNum "UNM";
BA_ "VNSigAllNodes" SG_ 1225 TERDTC_CdNum 1;
BA_ "SignalLongName" SG_ 1225 TCTPIR_TnsEsClCDwT "Transmission Clutch Thermal Protection Indication Request : Transmission Estimated Clutch Cool-down Temperature Target Display";
BA_ "PacketOrder" SG_ 1225 TCTPIR_TnsEsClCDwT 3;
BA_ "SignalType" SG_ 1225 TCTPIR_TnsEsClCDwT "UNM";
BA_ "VNSigAllNodes" SG_ 1225 TCTPIR_TnsEsClCDwT 1;
BA_ "SignalLongName" SG_ 1225 TCTPIR_TnsEsClTmpD "Transmission Clutch Thermal Protection Indication Request : Transmission Estimated Clutch Temperature Display";
BA_ "PacketOrder" SG_ 1225 TCTPIR_TnsEsClTmpD 2;
BA_ "SignalType" SG_ 1225 TCTPIR_TnsEsClTmpD "UNM";
BA_ "VNSigAllNodes" SG_ 1225 TCTPIR_TnsEsClTmpD 1;
BA_ "SignalLongName" SG_ 1225 TCTPIR_DrvNotfn "Transmission Clutch Thermal Protection Indication Request : Driver Notification";
BA_ "PacketOrder" SG_ 1225 TCTPIR_DrvNotfn 1;
BA_ "SignalType" SG_ 1225 TCTPIR_DrvNotfn "ENM";
BA_ "VNSigAllNodes" SG_ 1225 TCTPIR_DrvNotfn 1;
BA_ "SignalLongName" SG_ 1225 GrdBrkgAct "Grade Braking Active";
BA_ "SignalType" SG_ 1225 GrdBrkgAct "BLN";
BA_ "VNSigAllNodes" SG_ 1225 GrdBrkgAct 1;
BA_ "SignalLongName" SG_ 1225 TrnsThrmlMngmntStat "Transmission Thermal Management Status";
BA_ "SignalType" SG_ 1225 TrnsThrmlMngmntStat "ENM";
BA_ "VNSigAllNodes" SG_ 1225 TrnsThrmlMngmntStat 1;
BA_ "SignalLongName" SG_ 1225 TrnsNEmsRltMalfActv "Transmission Non Emissions Related Malfunction Active";
BA_ "SignalType" SG_ 1225 TrnsNEmsRltMalfActv "BLN";
BA_ "VNSigAllNodes" SG_ 1225 TrnsNEmsRltMalfActv 1;
BA_ "SignalLongName" SG_ 1225 TransOilTempSensPres "Transmission Oil Temperature Sensor Present";
BA_ "SignalType" SG_ 1225 TransOilTempSensPres "BLN";
BA_ "VNSigAllNodes" SG_ 1225 TransOilTempSensPres 1;
BA_ "SignalLongName" SG_ 1225 TrnEmsMlfAtv "Transmission Emissions Related Malfunction Active";
BA_ "SignalType" SG_ 1225 TrnEmsMlfAtv "BLN";
BA_ "VNSigAllNodes" SG_ 1225 TrnEmsMlfAtv 1;
BA_ "SignalLongName" SG_ 1225 TrnOilTmp "Transmission Oil Temperature";
BA_ "SignalType" SG_ 1225 TrnOilTmp "UNM";
BA_ "VNSigAllNodes" SG_ 1225 TrnOilTmp 1;
BA_ "SignalLongName" SG_ 1225 TrnOilTmpV "Transmission Oil Temperature Validity";
BA_ "SignalType" SG_ 1225 TrnOilTmpV "ENM";
BA_ "VNSigAllNodes" SG_ 1225 TrnOilTmpV 1;
BA_ "SignalLongName" SG_ 413 TrnsCyDactTransStat "Transmission Cylinder Deactivation Transition Status";
BA_ "SignalType" SG_ 413 TrnsCyDactTransStat "ENM";
BA_ "VNSigAllNodes" SG_ 413 TrnsCyDactTransStat 1;
BA_ "SignalLongName" SG_ 413 EngBrkDsblReqd "Engine Brake Disable Requested";
BA_ "SignalType" SG_ 413 EngBrkDsblReqd "BLN";
BA_ "VNSigAllNodes" SG_ 413 EngBrkDsblReqd 1;
BA_ "SignalLongName" SG_ 413 TrnsRtoCntlSysFlt "Transmission Ratio Control System Fault";
BA_ "SignalType" SG_ 413 TrnsRtoCntlSysFlt "BLN";
BA_ "VNSigAllNodes" SG_ 413 TrnsRtoCntlSysFlt 1;
BA_ "SignalLongName" SG_ 413 TrnTrbAngVl "Transmission Turbine Angular Velocity";
BA_ "SignalType" SG_ 413 TrnTrbAngVl "UNM";
BA_ "VNSigAllNodes" SG_ 413 TrnTrbAngVl 1;
BA_ "SignalLongName" SG_ 413 TrnTrbAngVlV "Transmission Turbine Angular Velocity Validity";
BA_ "SignalType" SG_ 413 TrnTrbAngVlV "ENM";
BA_ "VNSigAllNodes" SG_ 413 TrnTrbAngVlV 1;
BA_ "SignalLongName" SG_ 413 TrnGrRat "Transmission Gear Ratio";
BA_ "SignalType" SG_ 413 TrnGrRat "UNM";
BA_ "VNSigAllNodes" SG_ 413 TrnGrRat 1;
BA_ "SignalLongName" SG_ 413 TrnGrRatV "Transmission Gear Ratio Validity";
BA_ "SignalType" SG_ 413 TrnGrRatV "ENM";
BA_ "VNSigAllNodes" SG_ 413 TrnGrRatV 1;
BA_ "SignalLongName" SG_ 413 TrnPrfAlgShfAtv "Transmission Performance Algorithm Shift Mode Active";
BA_ "SignalType" SG_ 413 TrnPrfAlgShfAtv "BLN";
BA_ "VNSigAllNodes" SG_ 413 TrnPrfAlgShfAtv 1;
BA_ "SignalLongName" SG_ 413 TrnsAliveRC "Transmission Alive Rolling Count";
BA_ "SignalType" SG_ 413 TrnsAliveRC "UNM";
BA_ "VNSigAllNodes" SG_ 413 TrnsAliveRC 1;
BA_ "SignalLongName" SG_ 413 TrnsEngSpdRqProt "Transmission Engine Speed Request Protection";
BA_ "SignalType" SG_ 413 TrnsEngSpdRqProt "UNM";
BA_ "VNSigAllNodes" SG_ 413 TrnsEngSpdRqProt 1;
BA_ "SignalLongName" SG_ 413 TESR_EngSpdCntlRsp "Transmission Engine Speed Request : Engine Speed Control Response";
BA_ "PacketOrder" SG_ 413 TESR_EngSpdCntlRsp 2;
BA_ "SignalType" SG_ 413 TESR_EngSpdCntlRsp "ENM";
BA_ "VNSigAllNodes" SG_ 413 TESR_EngSpdCntlRsp 1;
BA_ "SignalLongName" SG_ 413 TESR_EngSpdRqVal "Transmission Engine Speed Request : Engine Speed Request Value";
BA_ "PacketOrder" SG_ 413 TESR_EngSpdRqVal 3;
BA_ "SignalType" SG_ 413 TESR_EngSpdRqVal "UNM";
BA_ "VNSigAllNodes" SG_ 413 TESR_EngSpdRqVal 1;
BA_ "SignalLongName" SG_ 413 TESR_EngSpdIntTyp "Transmission Engine Speed Request : Engine Speed Intervention Type";
BA_ "PacketOrder" SG_ 413 TESR_EngSpdIntTyp 1;
BA_ "SignalType" SG_ 413 TESR_EngSpdIntTyp "ENM";
BA_ "VNSigAllNodes" SG_ 413 TESR_EngSpdIntTyp 1;
BA_ "SignalLongName" SG_ 413 TrnsGrgShftAct "Transmission Garage Shift Active";
BA_ "SignalType" SG_ 413 TrnsGrgShftAct "BLN";
BA_ "VNSigAllNodes" SG_ 413 TrnsGrgShftAct 1;
BA_ "SignalLongName" SG_ 413 TransNtrlCntrlMdStat "Transmission Neutral Control Mode Status";
BA_ "SignalType" SG_ 413 TransNtrlCntrlMdStat "ENM";
BA_ "VNSigAllNodes" SG_ 413 TransNtrlCntrlMdStat 1;
BA_ "SignalLongName" SG_ 257 DgnInf "Diagnostic Information";
BA_ "SignalType" SG_ 257 DgnInf "UNM";
BA_ "VNSigSLHSSharedDiagnostic" SG_ 257 DgnInf 1;
BA_ "VNSigAllNodes" SG_ 257 DgnInf 1;
BA_ "GenSigDeltaValue" SG_ 257 DgnInf 1;
BA_ "GenSigSendType" SG_ 257 DgnInf 12;
BA_ "SignalLongName" SG_ 197 WRSLNDWhlDisTpRC "Wheel Rotational Status Left Non Driven : Wheel Distance Timestamp Rollover Counter";
BA_ "PacketOrder" SG_ 197 WRSLNDWhlDisTpRC 1;
BA_ "SignalType" SG_ 197 WRSLNDWhlDisTpRC "UNM";
BA_ "VNSigAllNodes" SG_ 197 WRSLNDWhlDisTpRC 1;
BA_ "SignalLongName" SG_ 197 WRSLNDWhlRotStRst "Wheel Rotational Status Left Non Driven : Wheel Rotational Status Reset Occurred";
BA_ "PacketOrder" SG_ 197 WRSLNDWhlRotStRst 3;
BA_ "SignalType" SG_ 197 WRSLNDWhlRotStRst "BLN";
BA_ "VNSigAllNodes" SG_ 197 WRSLNDWhlRotStRst 1;
BA_ "SignalLongName" SG_ 197 WRSLNDWhlDistVal "Wheel Rotational Status Left Non Driven : Wheel Distance Validity";
BA_ "PacketOrder" SG_ 197 WRSLNDWhlDistVal 4;
BA_ "SignalType" SG_ 197 WRSLNDWhlDistVal "ENM";
BA_ "VNSigAllNodes" SG_ 197 WRSLNDWhlDistVal 1;
BA_ "SignalLongName" SG_ 197 WRSLNDWhlDistTstm "Wheel Rotational Status Left Non Driven : Wheel Distance Timestamp";
BA_ "PacketOrder" SG_ 197 WRSLNDWhlDistTstm 6;
BA_ "SignalType" SG_ 197 WRSLNDWhlDistTstm "UNM";
BA_ "VNSigAllNodes" SG_ 197 WRSLNDWhlDistTstm 1;
BA_ "SignalLongName" SG_ 197 WRSLNDWhlDistPCntr "Wheel Rotational Status Left Non Driven : Wheel Distance Pulse Counter";
BA_ "PacketOrder" SG_ 197 WRSLNDWhlDistPCntr 5;
BA_ "SignalType" SG_ 197 WRSLNDWhlDistPCntr "UNM";
BA_ "VNSigAllNodes" SG_ 197 WRSLNDWhlDistPCntr 1;
BA_ "SignalLongName" SG_ 197 WRSLNDSeqNum "Wheel Rotational Status Left Non Driven : Sequence Number";
BA_ "PacketOrder" SG_ 197 WRSLNDSeqNum 2;
BA_ "SignalType" SG_ 197 WRSLNDSeqNum "UNM";
BA_ "VNSigAllNodes" SG_ 197 WRSLNDSeqNum 1;
BA_ "SignalLongName" SG_ 197 WRSRNDWhlDisTpRC "Wheel Rotational Status Right Non Driven : Wheel Distance Timestamp Rollover Counter";
BA_ "PacketOrder" SG_ 197 WRSRNDWhlDisTpRC 1;
BA_ "SignalType" SG_ 197 WRSRNDWhlDisTpRC "UNM";
BA_ "VNSigAllNodes" SG_ 197 WRSRNDWhlDisTpRC 1;
BA_ "SignalLongName" SG_ 197 WRSRNDWhlRotStRst "Wheel Rotational Status Right Non Driven : Wheel Rotational Status Reset Occurred";
BA_ "PacketOrder" SG_ 197 WRSRNDWhlRotStRst 3;
BA_ "SignalType" SG_ 197 WRSRNDWhlRotStRst "BLN";
BA_ "VNSigAllNodes" SG_ 197 WRSRNDWhlRotStRst 1;
BA_ "SignalLongName" SG_ 197 WRSRNDWhlDistVal "Wheel Rotational Status Right Non Driven : Wheel Distance Validity";
BA_ "PacketOrder" SG_ 197 WRSRNDWhlDistVal 4;
BA_ "SignalType" SG_ 197 WRSRNDWhlDistVal "ENM";
BA_ "VNSigAllNodes" SG_ 197 WRSRNDWhlDistVal 1;
BA_ "SignalLongName" SG_ 197 WRSRNDWhlDistTstm "Wheel Rotational Status Right Non Driven : Wheel Distance Timestamp";
BA_ "PacketOrder" SG_ 197 WRSRNDWhlDistTstm 6;
BA_ "SignalType" SG_ 197 WRSRNDWhlDistTstm "UNM";
BA_ "VNSigAllNodes" SG_ 197 WRSRNDWhlDistTstm 1;
BA_ "SignalLongName" SG_ 197 WRSRNDWhlDistPCntr "Wheel Rotational Status Right Non Driven : Wheel Distance Pulse Counter";
BA_ "PacketOrder" SG_ 197 WRSRNDWhlDistPCntr 5;
BA_ "SignalType" SG_ 197 WRSRNDWhlDistPCntr "UNM";
BA_ "VNSigAllNodes" SG_ 197 WRSRNDWhlDistPCntr 1;
BA_ "SignalLongName" SG_ 197 WRSRNDSeqNum "Wheel Rotational Status Right Non Driven : Sequence Number";
BA_ "PacketOrder" SG_ 197 WRSRNDSeqNum 2;
BA_ "SignalType" SG_ 197 WRSRNDSeqNum "UNM";
BA_ "VNSigAllNodes" SG_ 197 WRSRNDSeqNum 1;
BA_ "SignalLongName" SG_ 840 WhlRotDrctnlStLftDrvn "Wheel Rotational Directional Status Left Driven";
BA_ "SignalType" SG_ 840 WhlRotDrctnlStLftDrvn "ENM";
BA_ "VNSigAllNodes" SG_ 840 WhlRotDrctnlStLftDrvn 1;
BA_ "SignalLongName" SG_ 840 WhlRotDrctnlStRtDrvn "Wheel Rotational Directional Status Right Driven";
BA_ "SignalType" SG_ 840 WhlRotDrctnlStRtDrvn "ENM";
BA_ "VNSigAllNodes" SG_ 840 WhlRotDrctnlStRtDrvn 1;
BA_ "SignalLongName" SG_ 840 WhlGrndVlctyRtDrvnV "Wheel Ground Velocity Right Driven Validity";
BA_ "SignalType" SG_ 840 WhlGrndVlctyRtDrvnV "ENM";
BA_ "VNSigAllNodes" SG_ 840 WhlGrndVlctyRtDrvnV 1;
BA_ "SignalLongName" SG_ 840 WhlGrndVlctyRtDrvn "Wheel Ground Velocity Right Driven";
BA_ "SignalType" SG_ 840 WhlGrndVlctyRtDrvn "UNM";
BA_ "VNSigAllNodes" SG_ 840 WhlGrndVlctyRtDrvn 1;
BA_ "SignalLongName" SG_ 840 WhlGrndVlctyLftDrvnV "Wheel Ground Velocity Left Driven Validity";
BA_ "SignalType" SG_ 840 WhlGrndVlctyLftDrvnV "ENM";
BA_ "VNSigAllNodes" SG_ 840 WhlGrndVlctyLftDrvnV 1;
BA_ "SignalLongName" SG_ 840 WhlGrndVlctyLftDrvn "Wheel Ground Velocity Left Driven";
BA_ "SignalType" SG_ 840 WhlGrndVlctyLftDrvn "UNM";
BA_ "VNSigAllNodes" SG_ 840 WhlGrndVlctyLftDrvn 1;
BA_ "SignalLongName" SG_ 193 WRSLDWhlDisTpRC "Wheel Rotational Status Left Driven : Wheel Distance Timestamp Rollover Counter";
BA_ "PacketOrder" SG_ 193 WRSLDWhlDisTpRC 1;
BA_ "SignalType" SG_ 193 WRSLDWhlDisTpRC "UNM";
BA_ "VNSigAllNodes" SG_ 193 WRSLDWhlDisTpRC 1;
BA_ "GenSigDeltaValue" SG_ 193 WRSLDWhlDisTpRC 1;
BA_ "GenSigSendType" SG_ 193 WRSLDWhlDisTpRC 12;
BA_ "SignalLongName" SG_ 193 WRSLDSeqNum "Wheel Rotational Status Left Driven : Sequence Number";
BA_ "PacketOrder" SG_ 193 WRSLDSeqNum 2;
BA_ "SignalType" SG_ 193 WRSLDSeqNum "UNM";
BA_ "VNSigAllNodes" SG_ 193 WRSLDSeqNum 1;
BA_ "GenSigDeltaValue" SG_ 193 WRSLDSeqNum 1;
BA_ "GenSigSendType" SG_ 193 WRSLDSeqNum 12;
BA_ "SignalLongName" SG_ 193 WRSLDWhlDistVal "Wheel Rotational Status Left Driven : Wheel Distance Validity";
BA_ "PacketOrder" SG_ 193 WRSLDWhlDistVal 4;
BA_ "SignalType" SG_ 193 WRSLDWhlDistVal "ENM";
BA_ "VNSigAllNodes" SG_ 193 WRSLDWhlDistVal 1;
BA_ "GenSigSendType" SG_ 193 WRSLDWhlDistVal 10;
BA_ "SignalLongName" SG_ 193 WRSLDWhlRotStatRst "Wheel Rotational Status Left Driven : Wheel Rotational Status Reset Occurred";
BA_ "PacketOrder" SG_ 193 WRSLDWhlRotStatRst 3;
BA_ "SignalType" SG_ 193 WRSLDWhlRotStatRst "BLN";
BA_ "VNSigAllNodes" SG_ 193 WRSLDWhlRotStatRst 1;
BA_ "GenSigSendType" SG_ 193 WRSLDWhlRotStatRst 10;
BA_ "SignalLongName" SG_ 193 WRSLDWhlDistTmstm "Wheel Rotational Status Left Driven : Wheel Distance Timestamp";
BA_ "PacketOrder" SG_ 193 WRSLDWhlDistTmstm 6;
BA_ "SignalType" SG_ 193 WRSLDWhlDistTmstm "UNM";
BA_ "VNSigAllNodes" SG_ 193 WRSLDWhlDistTmstm 1;
BA_ "GenSigDeltaValue" SG_ 193 WRSLDWhlDistTmstm 1;
BA_ "GenSigSendType" SG_ 193 WRSLDWhlDistTmstm 12;
BA_ "SignalLongName" SG_ 193 WRSLDWhlDistPlsCntr "Wheel Rotational Status Left Driven : Wheel Distance Pulse Counter";
BA_ "PacketOrder" SG_ 193 WRSLDWhlDistPlsCntr 5;
BA_ "SignalType" SG_ 193 WRSLDWhlDistPlsCntr "UNM";
BA_ "VNSigAllNodes" SG_ 193 WRSLDWhlDistPlsCntr 1;
BA_ "GenSigDeltaValue" SG_ 193 WRSLDWhlDistPlsCntr 1;
BA_ "GenSigSendType" SG_ 193 WRSLDWhlDistPlsCntr 12;
BA_ "SignalLongName" SG_ 193 WRSRDWhlDisTpRC "Wheel Rotational Status Right Driven : Wheel Distance Timestamp Rollover Counter";
BA_ "PacketOrder" SG_ 193 WRSRDWhlDisTpRC 1;
BA_ "SignalType" SG_ 193 WRSRDWhlDisTpRC "UNM";
BA_ "VNSigAllNodes" SG_ 193 WRSRDWhlDisTpRC 1;
BA_ "GenSigDeltaValue" SG_ 193 WRSRDWhlDisTpRC 1;
BA_ "GenSigSendType" SG_ 193 WRSRDWhlDisTpRC 12;
BA_ "SignalLongName" SG_ 193 WRSRDSeqNum "Wheel Rotational Status Right Driven : Sequence Number";
BA_ "PacketOrder" SG_ 193 WRSRDSeqNum 2;
BA_ "SignalType" SG_ 193 WRSRDSeqNum "UNM";
BA_ "VNSigAllNodes" SG_ 193 WRSRDSeqNum 1;
BA_ "GenSigDeltaValue" SG_ 193 WRSRDSeqNum 1;
BA_ "GenSigSendType" SG_ 193 WRSRDSeqNum 12;
BA_ "SignalLongName" SG_ 193 WRSRDWhlRotStatRst "Wheel Rotational Status Right Driven : Wheel Rotational Status Reset Occurred";
BA_ "PacketOrder" SG_ 193 WRSRDWhlRotStatRst 3;
BA_ "SignalType" SG_ 193 WRSRDWhlRotStatRst "BLN";
BA_ "VNSigAllNodes" SG_ 193 WRSRDWhlRotStatRst 1;
BA_ "GenSigSendType" SG_ 193 WRSRDWhlRotStatRst 10;
BA_ "SignalLongName" SG_ 193 WRSRDWhlDistVal "Wheel Rotational Status Right Driven : Wheel Distance Validity";
BA_ "PacketOrder" SG_ 193 WRSRDWhlDistVal 4;
BA_ "SignalType" SG_ 193 WRSRDWhlDistVal "ENM";
BA_ "VNSigAllNodes" SG_ 193 WRSRDWhlDistVal 1;
BA_ "GenSigSendType" SG_ 193 WRSRDWhlDistVal 10;
BA_ "SignalLongName" SG_ 193 WRSRDWhlDistTmstm "Wheel Rotational Status Right Driven : Wheel Distance Timestamp";
BA_ "PacketOrder" SG_ 193 WRSRDWhlDistTmstm 6;
BA_ "SignalType" SG_ 193 WRSRDWhlDistTmstm "UNM";
BA_ "VNSigAllNodes" SG_ 193 WRSRDWhlDistTmstm 1;
BA_ "GenSigDeltaValue" SG_ 193 WRSRDWhlDistTmstm 1;
BA_ "GenSigSendType" SG_ 193 WRSRDWhlDistTmstm 12;
BA_ "SignalLongName" SG_ 193 WRSRDWhlDistPlsCntr "Wheel Rotational Status Right Driven : Wheel Distance Pulse Counter";
BA_ "PacketOrder" SG_ 193 WRSRDWhlDistPlsCntr 5;
BA_ "SignalType" SG_ 193 WRSRDWhlDistPlsCntr "UNM";
BA_ "VNSigAllNodes" SG_ 193 WRSRDWhlDistPlsCntr 1;
BA_ "GenSigDeltaValue" SG_ 193 WRSRDWhlDistPlsCntr 1;
BA_ "GenSigSendType" SG_ 193 WRSRDWhlDistPlsCntr 12;
BA_ "SignalLongName" SG_ 761 BrkSysHRBkCtrlAvail "Brake System Hill Rollback Control Available";
BA_ "SignalType" SG_ 761 BrkSysHRBkCtrlAvail "BLN";
BA_ "VNSigAllNodes" SG_ 761 BrkSysHRBkCtrlAvail 1;
BA_ "SignalLongName" SG_ 761 BrkSysHRBkCtrlStat "Brake System Hill Rollback Control Status";
BA_ "SignalType" SG_ 761 BrkSysHRBkCtrlStat "ENM";
BA_ "VNSigAllNodes" SG_ 761 BrkSysHRBkCtrlStat 1;
BA_ "SignalLongName" SG_ 761 BrkSysHSAAval "Brake System Hill Start Assist Available";
BA_ "SignalType" SG_ 761 BrkSysHSAAval "BLN";
BA_ "VNSigAllNodes" SG_ 761 BrkSysHSAAval 1;
BA_ "SignalLongName" SG_ 761 BrkSysHSAStat "Brake System Hill Start Assist Status";
BA_ "SignalType" SG_ 761 BrkSysHSAStat "ENM";
BA_ "VNSigAllNodes" SG_ 761 BrkSysHSAStat 1;
BA_ "SignalLongName" SG_ 761 HillDscntCtrlStatPVal "Hill Descent Control Status Protection Value";
BA_ "SignalType" SG_ 761 HillDscntCtrlStatPVal "UNM";
BA_ "VNSigAllNodes" SG_ 761 HillDscntCtrlStatPVal 1;
BA_ "SignalLongName" SG_ 761 HillDscntCtrlStatARC "Hill Descent Control Status Alive Rolling Count";
BA_ "SignalType" SG_ 761 HillDscntCtrlStatARC "UNM";
BA_ "VNSigAllNodes" SG_ 761 HillDscntCtrlStatARC 1;
BA_ "SignalLongName" SG_ 761 HillDscntCtrlStat "Hill Descent Control Status";
BA_ "SignalType" SG_ 761 HillDscntCtrlStat "ENM";
BA_ "VNSigAllNodes" SG_ 761 HillDscntCtrlStat 1;
BA_ "SignalLongName" SG_ 761 AutoBrkFeatInhbtPVal "Automatic Braking Feature Inhibit Protection Value";
BA_ "SignalType" SG_ 761 AutoBrkFeatInhbtPVal "UNM";
BA_ "VNSigAllNodes" SG_ 761 AutoBrkFeatInhbtPVal 1;
BA_ "SignalLongName" SG_ 761 AutoBrkFeatInhbtARC "Automatic Braking Feature Inhibit Alive Rolling Count";
BA_ "SignalType" SG_ 761 AutoBrkFeatInhbtARC "UNM";
BA_ "VNSigAllNodes" SG_ 761 AutoBrkFeatInhbtARC 1;
BA_ "SignalLongName" SG_ 761 ABFI_CollPrepSysInhbt "Automatic Braking Feature Inhibit : Collision Preparation System Inhibit";
BA_ "PacketOrder" SG_ 761 ABFI_CollPrepSysInhbt 2;
BA_ "SignalType" SG_ 761 ABFI_CollPrepSysInhbt "BLN";
BA_ "VNSigAllNodes" SG_ 761 ABFI_CollPrepSysInhbt 1;
BA_ "SignalLongName" SG_ 761 ABFI_RrVirtlBmprInh "Automatic Braking Feature Inhibit : Rear Virtual Bumper Inhibit";
BA_ "PacketOrder" SG_ 761 ABFI_RrVirtlBmprInh 1;
BA_ "SignalType" SG_ 761 ABFI_RrVirtlBmprInh "BLN";
BA_ "VNSigAllNodes" SG_ 761 ABFI_RrVirtlBmprInh 1;
BA_ "SignalLongName" SG_ 761 ChsAVHStatPVal "Chassis Auto Vehicle Hold Status Protection Value";
BA_ "SignalType" SG_ 761 ChsAVHStatPVal "UNM";
BA_ "VNSigAllNodes" SG_ 761 ChsAVHStatPVal 1;
BA_ "SignalLongName" SG_ 761 ChsAVHStatARC "Chassis Auto Vehicle Hold Status Alive Rolling Count";
BA_ "SignalType" SG_ 761 ChsAVHStatARC "UNM";
BA_ "VNSigAllNodes" SG_ 761 ChsAVHStatARC 1;
BA_ "SignalLongName" SG_ 761 CAVHS_ACHActv "Chassis Auto Vehicle Hold Status : Adaptive Cruise Hold Active";
BA_ "PacketOrder" SG_ 761 CAVHS_ACHActv 3;
BA_ "SignalType" SG_ 761 CAVHS_ACHActv "BLN";
BA_ "VNSigAllNodes" SG_ 761 CAVHS_ACHActv 1;
BA_ "SignalLongName" SG_ 761 CAVHS_DSHEnbld "Chassis Auto Vehicle Hold Status : Driver Selected Hold Enabled";
BA_ "PacketOrder" SG_ 761 CAVHS_DSHEnbld 2;
BA_ "SignalType" SG_ 761 CAVHS_DSHEnbld "BLN";
BA_ "VNSigAllNodes" SG_ 761 CAVHS_DSHEnbld 1;
BA_ "SignalLongName" SG_ 761 CAVHS_DSHActv "Chassis Auto Vehicle Hold Status : Driver Selected Hold Active";
BA_ "PacketOrder" SG_ 761 CAVHS_DSHActv 1;
BA_ "SignalType" SG_ 761 CAVHS_DSHActv "BLN";
BA_ "VNSigAllNodes" SG_ 761 CAVHS_DSHActv 1;
BA_ "SignalLongName" SG_ 761 BrkPdlDrvApplPresV "Brake Pedal Driver Applied Pressure Validity";
BA_ "SignalType" SG_ 761 BrkPdlDrvApplPresV "ENM";
BA_ "VNSigAllNodes" SG_ 761 BrkPdlDrvApplPresV 1;
BA_ "SignalLongName" SG_ 761 BrkPdlDrvApplPres "Brake Pedal Driver Applied Pressure";
BA_ "SignalType" SG_ 761 BrkPdlDrvApplPres "UNM";
BA_ "VNSigAllNodes" SG_ 761 BrkPdlDrvApplPres 1;
BA_ "SignalLongName" SG_ 761 AutoBrkPTReqStat "Automatic Braking Powertrain Request Status";
BA_ "SignalType" SG_ 761 AutoBrkPTReqStat "ENM";
BA_ "VNSigAllNodes" SG_ 761 AutoBrkPTReqStat 1;
BA_ "SignalLongName" SG_ 761 WhlSpdSnsgDTCIndex "Wheel Speed Sensing Legislated Diagnostic Status : Diagnostic Trouble Code Index";
BA_ "PacketOrder" SG_ 761 WhlSpdSnsgDTCIndex 1;
BA_ "SignalType" SG_ 761 WhlSpdSnsgDTCIndex "UNM";
BA_ "VNSigAllNodes" SG_ 761 WhlSpdSnsgDTCIndex 1;
BA_ "SignalLongName" SG_ 761 WhlSpdSnsgDTCStat "Wheel Speed Sensing Legislated Diagnostic Status : Diagnostic Trouble Code Status";
BA_ "PacketOrder" SG_ 761 WhlSpdSnsgDTCStat 2;
BA_ "SignalType" SG_ 761 WhlSpdSnsgDTCStat "ENM";
BA_ "VNSigAllNodes" SG_ 761 WhlSpdSnsgDTCStat 1;
BA_ "SignalLongName" SG_ 761 SprTireSt "Spare Tire Status";
BA_ "SignalType" SG_ 761 SprTireSt "ENM";
BA_ "VNSigAllNodes" SG_ 761 SprTireSt 1;
BA_ "SignalLongName" SG_ 489 EnhDrvMdSwChUseRq "Enhanced Driver Selected Mode Switch Chassis Use Requested";
BA_ "SignalType" SG_ 489 EnhDrvMdSwChUseRq "BLN";
BA_ "VNSigAllNodes" SG_ 489 EnhDrvMdSwChUseRq 1;
BA_ "SignalLongName" SG_ 489 IMUDataMsk "Inertial Measurement Unit Data Mask";
BA_ "SignalType" SG_ 489 IMUDataMsk "BLN";
BA_ "VNSigAllNodes" SG_ 489 IMUDataMsk 1;
BA_ "SignalLongName" SG_ 489 DrvIndpntBrkAppAct "Driver Independent Brake Apply Active";
BA_ "SignalType" SG_ 489 DrvIndpntBrkAppAct "BLN";
BA_ "VNSigAllNodes" SG_ 489 DrvIndpntBrkAppAct 1;
BA_ "SignalLongName" SG_ 489 WhlSlpSt "Wheel Slip Status";
BA_ "SignalType" SG_ 489 WhlSlpSt "ENM";
BA_ "VNSigAllNodes" SG_ 489 WhlSlpSt 1;
BA_ "SignalLongName" SG_ 489 BSTGRReqdGear "Brake System Transmission Gear Request : Requested Gear";
BA_ "PacketOrder" SG_ 489 BSTGRReqdGear 2;
BA_ "SignalType" SG_ 489 BSTGRReqdGear "ENM";
BA_ "VNSigAllNodes" SG_ 489 BSTGRReqdGear 1;
BA_ "SignalLongName" SG_ 489 BSTGRReqType "Brake System Transmission Gear Request : Request Type";
BA_ "PacketOrder" SG_ 489 BSTGRReqType 1;
BA_ "SignalType" SG_ 489 BSTGRReqType "ENM";
BA_ "VNSigAllNodes" SG_ 489 BSTGRReqType 1;
BA_ "SignalLongName" SG_ 489 VehDynOvrUndrStr "Vehicle Dynamics Over Under Steer";
BA_ "SignalType" SG_ 489 VehDynOvrUndrStr "SNM";
BA_ "VNSigAllNodes" SG_ 489 VehDynOvrUndrStr 1;
BA_ "SignalLongName" SG_ 489 VhDynCntlSysSt "Vehicle Dynamics Control System Status";
BA_ "SignalType" SG_ 489 VhDynCntlSysSt "ENM";
BA_ "VNSigAllNodes" SG_ 489 VhDynCntlSysSt 1;
BA_ "SignalLongName" SG_ 489 TrnsBrkSysCltchRelRqd "Transmission Brake System Clutch Release Requested";
BA_ "SignalType" SG_ 489 TrnsBrkSysCltchRelRqd "BLN";
BA_ "VNSigAllNodes" SG_ 489 TrnsBrkSysCltchRelRqd 1;
BA_ "SignalLongName" SG_ 489 TracCntrlSysDrIntnt "Traction Control System Driver Intent";
BA_ "SignalType" SG_ 489 TracCntrlSysDrIntnt "ENM";
BA_ "VNSigAllNodes" SG_ 489 TracCntrlSysDrIntnt 1;
BA_ "SignalLongName" SG_ 489 VehDynOvrUndrStrV "Vehicle Dynamics Over Under Steer Validity";
BA_ "SignalType" SG_ 489 VehDynOvrUndrStrV "ENM";
BA_ "VNSigAllNodes" SG_ 489 VehDynOvrUndrStrV 1;
BA_ "SignalLongName" SG_ 489 TCSysEnbld "Traction Control System Enabled";
BA_ "SignalType" SG_ 489 TCSysEnbld "BLN";
BA_ "VNSigAllNodes" SG_ 489 TCSysEnbld 1;
BA_ "SignalLongName" SG_ 489 BrkPdlDrvAppPrsDetcdV "Brake Pedal Driver Applied Pressure Detected Validity";
BA_ "SignalType" SG_ 489 BrkPdlDrvAppPrsDetcdV "ENM";
BA_ "VNSigAllNodes" SG_ 489 BrkPdlDrvAppPrsDetcdV 1;
BA_ "GenSigStartValue" SG_ 489 BrkPdlDrvAppPrsDetcd 1;
BA_ "SignalLongName" SG_ 489 BrkPdlDrvAppPrsDetcd "Brake Pedal Driver Applied Pressure Detected";
BA_ "SignalType" SG_ 489 BrkPdlDrvAppPrsDetcd "BLN";
BA_ "VNSigAllNodes" SG_ 489 BrkPdlDrvAppPrsDetcd 1;
BA_ "SignalLongName" SG_ 489 ACCBrkngAct "Adaptive Cruise Control Braking Active";
BA_ "SignalType" SG_ 489 ACCBrkngAct "BLN";
BA_ "VNSigAllNodes" SG_ 489 ACCBrkngAct 1;
BA_ "SignalLongName" SG_ 489 ABSFld "Antilock Brake System Failed";
BA_ "SignalType" SG_ 489 ABSFld "BLN";
BA_ "VNSigAllNodes" SG_ 489 ABSFld 1;
BA_ "SignalLongName" SG_ 489 VSELatAccV "Vehicle Stability Enhancement Lateral Acceleration Validity";
BA_ "SignalType" SG_ 489 VSELatAccV "ENM";
BA_ "VNSigAllNodes" SG_ 489 VSELatAccV 1;
BA_ "SignalLongName" SG_ 489 VSELatAcc "Vehicle Stability Enhancement Lateral Acceleration";
BA_ "SignalType" SG_ 489 VSELatAcc "SNM";
BA_ "VNSigAllNodes" SG_ 489 VSELatAcc 1;
BA_ "SignalLongName" SG_ 489 VSEAct "Vehicle Stability Enhancement System Active";
BA_ "SignalType" SG_ 489 VSEAct "BLN";
BA_ "VNSigAllNodes" SG_ 489 VSEAct 1;
BA_ "SignalLongName" SG_ 489 VehDynYawRateV "Vehicle Dynamics Yaw Rate Validity";
BA_ "SignalType" SG_ 489 VehDynYawRateV "ENM";
BA_ "VNSigAllNodes" SG_ 489 VehDynYawRateV 1;
BA_ "SignalLongName" SG_ 489 VehDynYawRate "Vehicle Dynamics Yaw Rate";
BA_ "SignalType" SG_ 489 VehDynYawRate "SNM";
BA_ "VNSigAllNodes" SG_ 489 VehDynYawRate 1;
BA_ "SignalLongName" SG_ 489 TCSysAtv "Traction Control System Active";
BA_ "SignalType" SG_ 489 TCSysAtv "BLN";
BA_ "VNSigAllNodes" SG_ 489 TCSysAtv 1;
BA_ "SignalLongName" SG_ 489 ABSAtv "Antilock Brake System Active";
BA_ "SignalType" SG_ 489 ABSAtv "BLN";
BA_ "VNSigAllNodes" SG_ 489 ABSAtv 1;
BA_ "SignalLongName" SG_ 381 BrkSysStCrwlModeOvrrd "Brake System State Crawl Mode Override";
BA_ "SignalType" SG_ 381 BrkSysStCrwlModeOvrrd "ENM";
BA_ "VNSigAllNodes" SG_ 381 BrkSysStCrwlModeOvrrd 1;
BA_ "SignalLongName" SG_ 381 BrkSysVTopSpdLimIO "Braking System Vehicle Top Speed Limit Indication On";
BA_ "SignalType" SG_ 381 BrkSysVTopSpdLimIO "BLN";
BA_ "VNSigAllNodes" SG_ 381 BrkSysVTopSpdLimIO 1;
BA_ "GenSigSendType" SG_ 381 BrkSysVTopSpdLimIO 10;
BA_ "SignalLongName" SG_ 381 ABSActIO "Antilock Brake System Active Indication On";
BA_ "SignalType" SG_ 381 ABSActIO "BLN";
BA_ "VNSigAllNodes" SG_ 381 ABSActIO 1;
BA_ "GenSigSendType" SG_ 381 ABSActIO 10;
BA_ "SignalLongName" SG_ 381 BrkPdLfStatIndRq "Brake Pad Life Status Indication Request";
BA_ "SignalType" SG_ 381 BrkPdLfStatIndRq "ENM";
BA_ "VNSigAllNodes" SG_ 381 BrkPdLfStatIndRq 1;
BA_ "GenSigSendType" SG_ 381 BrkPdLfStatIndRq 10;
BA_ "GenSigSendOnInit" SG_ 381 BrkPdLfStatIndRq 2;
BA_ "SignalLongName" SG_ 381 VehStbCmptvMdCstAvl "Vehicle Stability Competitive Mode Customization Available";
BA_ "SignalType" SG_ 381 VehStbCmptvMdCstAvl "BLN";
BA_ "VNSigAllNodes" SG_ 381 VehStbCmptvMdCstAvl 1;
BA_ "GenSigSendType" SG_ 381 VehStbCmptvMdCstAvl 10;
BA_ "GenSigSendOnInit" SG_ 381 VehStbCmptvMdCstAvl 2;
BA_ "SignalLongName" SG_ 381 VehStbEnmntCstAvl "Vehicle Stability Enhancement Customization Available";
BA_ "SignalType" SG_ 381 VehStbEnmntCstAvl "BLN";
BA_ "VNSigAllNodes" SG_ 381 VehStbEnmntCstAvl 1;
BA_ "GenSigSendType" SG_ 381 VehStbEnmntCstAvl 10;
BA_ "GenSigSendOnInit" SG_ 381 VehStbEnmntCstAvl 2;
BA_ "SignalLongName" SG_ 381 VehStbCmptvMdCurSt "Vehicle Stability Competitive Mode Current State";
BA_ "SignalType" SG_ 381 VehStbCmptvMdCurSt "ENM";
BA_ "VNSigAllNodes" SG_ 381 VehStbCmptvMdCurSt 1;
BA_ "GenSigSendType" SG_ 381 VehStbCmptvMdCurSt 10;
BA_ "GenSigSendOnInit" SG_ 381 VehStbCmptvMdCurSt 2;
BA_ "SignalLongName" SG_ 381 VehStbEnhmntCurSt "Vehicle Stability Enhancement Current State";
BA_ "SignalType" SG_ 381 VehStbEnhmntCurSt "ENM";
BA_ "VNSigAllNodes" SG_ 381 VehStbEnhmntCurSt 1;
BA_ "GenSigSendType" SG_ 381 VehStbEnhmntCurSt 10;
BA_ "GenSigSendOnInit" SG_ 381 VehStbEnhmntCurSt 2;
BA_ "SignalLongName" SG_ 381 TCSTempDsblReqIO "Traction Control System Temporary Disable Request Indication On";
BA_ "SignalType" SG_ 381 TCSTempDsblReqIO "BLN";
BA_ "VNSigAllNodes" SG_ 381 TCSTempDsblReqIO 1;
BA_ "GenSigSendType" SG_ 381 TCSTempDsblReqIO 10;
BA_ "GenSigSendOnInit" SG_ 381 TCSTempDsblReqIO 2;
BA_ "SignalLongName" SG_ 381 TCSysCstAvl "Traction Control System Customization Available";
BA_ "SignalType" SG_ 381 TCSysCstAvl "BLN";
BA_ "VNSigAllNodes" SG_ 381 TCSysCstAvl 1;
BA_ "GenSigSendType" SG_ 381 TCSysCstAvl 10;
BA_ "GenSigSendOnInit" SG_ 381 TCSysCstAvl 2;
BA_ "SignalLongName" SG_ 381 TCSysCurSt "Traction Control System Current State";
BA_ "SignalType" SG_ 381 TCSysCurSt "ENM";
BA_ "VNSigAllNodes" SG_ 381 TCSysCurSt 1;
BA_ "GenSigSendType" SG_ 381 TCSysCurSt 10;
BA_ "GenSigSendOnInit" SG_ 381 TCSysCurSt 2;
BA_ "SignalLongName" SG_ 381 TracAndStbScrnCnfg "Traction And Stability Screen Configuration";
BA_ "SignalType" SG_ 381 TracAndStbScrnCnfg "ENM";
BA_ "VNSigAllNodes" SG_ 381 TracAndStbScrnCnfg 1;
BA_ "GenSigSendType" SG_ 381 TracAndStbScrnCnfg 10;
BA_ "GenSigSendOnInit" SG_ 381 TracAndStbScrnCnfg 2;
BA_ "SignalLongName" SG_ 381 HillDesCtrlRedVehSpIO "Hill Descent Control Reduce Vehicle Speed Indication On";
BA_ "SignalType" SG_ 381 HillDesCtrlRedVehSpIO "BLN";
BA_ "VNSigAllNodes" SG_ 381 HillDesCtrlRedVehSpIO 1;
BA_ "SignalLongName" SG_ 381 EBDFailed "Electronic Brake Distribution Failed";
BA_ "SignalType" SG_ 381 EBDFailed "BLN";
BA_ "VNSigAllNodes" SG_ 381 EBDFailed 1;
BA_ "GenSigStartValue" SG_ 381 StWhAnVDA 1;
BA_ "SignalLongName" SG_ 381 StWhAnVDA "Steering Wheel Angle Virtual Device Availability";
BA_ "SignalType" SG_ 381 StWhAnVDA "ENM";
BA_ "VNSigAllNodes" SG_ 381 StWhAnVDA 1;
BA_ "SignalLongName" SG_ 381 TirePrsLowIO "Tire Pressure Low Indication On";
BA_ "SignalType" SG_ 381 TirePrsLowIO "BLN";
BA_ "VNSigAllNodes" SG_ 381 TirePrsLowIO 1;
BA_ "SignalLongName" SG_ 381 VaccBoostFailure "Vaccum Boost Failure";
BA_ "SignalType" SG_ 381 VaccBoostFailure "BLN";
BA_ "VNSigAllNodes" SG_ 381 VaccBoostFailure 1;
BA_ "SignalLongName" SG_ 381 VSESysPrs "Vehicle Stability Enhancement System Present";
BA_ "SignalType" SG_ 381 VSESysPrs "BLN";
BA_ "VNSigAllNodes" SG_ 381 VSESysPrs 1;
BA_ "SignalLongName" SG_ 381 HalfSysFail "Half System Failure";
BA_ "SignalType" SG_ 381 HalfSysFail "BLN";
BA_ "VNSigAllNodes" SG_ 381 HalfSysFail 1;
BA_ "SignalLongName" SG_ 381 ActVehAccel "Actual Vehicle Acceleration";
BA_ "SignalType" SG_ 381 ActVehAccel "SNM";
BA_ "VNSigAllNodes" SG_ 381 ActVehAccel 1;
BA_ "SignalLongName" SG_ 381 ActVehAccelV "Actual Vehicle Acceleration Validity";
BA_ "SignalType" SG_ 381 ActVehAccelV "ENM";
BA_ "VNSigAllNodes" SG_ 381 ActVehAccelV 1;
BA_ "SignalLongName" SG_ 381 BksOvht "Brakes Overheated";
BA_ "SignalType" SG_ 381 BksOvht "BLN";
BA_ "VNSigAllNodes" SG_ 381 BksOvht 1;
BA_ "SignalLongName" SG_ 381 TCSysPr "Traction Control System Present";
BA_ "SignalType" SG_ 381 TCSysPr "BLN";
BA_ "VNSigAllNodes" SG_ 381 TCSysPr 1;
BA_ "SignalLongName" SG_ 381 ABSPr "Antilock Brake System Present";
BA_ "SignalType" SG_ 381 ABSPr "BLN";
BA_ "VNSigAllNodes" SG_ 381 ABSPr 1;
BA_ "SignalLongName" SG_ 381 TreInfMonSysRstPrfmd "Tire Inflation Monitoring System Reset Performed";
BA_ "SignalType" SG_ 381 TreInfMonSysRstPrfmd "BLN";
BA_ "VNSigAllNodes" SG_ 381 TreInfMonSysRstPrfmd 1;
BA_ "SignalLongName" SG_ 381 ABSIO "Antilock Brake System Indication On";
BA_ "SignalType" SG_ 381 ABSIO "BLN";
BA_ "VNSigAllNodes" SG_ 381 ABSIO 1;
BA_ "SignalLongName" SG_ 381 BrkPadWrnIO "Brake Pad Worn Indication On";
BA_ "SignalType" SG_ 381 BrkPadWrnIO "BLN";
BA_ "VNSigAllNodes" SG_ 381 BrkPadWrnIO 1;
BA_ "SignalLongName" SG_ 381 VehStabEnhmntMd "Vehicle Stability Enhancement Mode";
BA_ "SignalType" SG_ 381 VehStabEnhmntMd "ENM";
BA_ "VNSigAllNodes" SG_ 381 VehStabEnhmntMd 1;
BA_ "SignalLongName" SG_ 381 VehStabEnhmntStat "Vehicle Stability Enhancement Status";
BA_ "SignalType" SG_ 381 VehStabEnhmntStat "ENM";
BA_ "VNSigAllNodes" SG_ 381 VehStabEnhmntStat 1;
BA_ "SignalLongName" SG_ 381 TCSysOpMd "Traction Control System Operating Mode";
BA_ "SignalType" SG_ 381 TCSysOpMd "ENM";
BA_ "VNSigAllNodes" SG_ 381 TCSysOpMd 1;
BA_ "SignalLongName" SG_ 381 TCSysOpStat "Traction Control System Operating Status";
BA_ "SignalType" SG_ 381 TCSysOpStat "ENM";
BA_ "VNSigAllNodes" SG_ 381 TCSysOpStat 1;
BA_ "GenSigStartValue" SG_ 381 BrkSysVTopSpdLimVal 255;
BA_ "SignalLongName" SG_ 381 BrkSysVTopSpdLimVal "Braking System Vehicle Top Speed Limit Value";
BA_ "SignalType" SG_ 381 BrkSysVTopSpdLimVal "UNM";
BA_ "VNSigAllNodes" SG_ 381 BrkSysVTopSpdLimVal 1;
BA_ "GenSigDeltaValue" SG_ 381 BrkSysVTopSpdLimVal 1;
BA_ "GenSigSendType" SG_ 381 BrkSysVTopSpdLimVal 12;
BA_ "SignalLongName" SG_ 381 BrkSysRedBrkTlltlReq "Brake System Red Brake Telltale Request";
BA_ "SignalType" SG_ 381 BrkSysRedBrkTlltlReq "BLN";
BA_ "VNSigAllNodes" SG_ 381 BrkSysRedBrkTlltlReq 1;
BA_ "SignalLongName" SG_ 381 BrkSysBrkLtsReqd "Brake System Brake Lights Requested";
BA_ "SignalType" SG_ 381 BrkSysBrkLtsReqd "BLN";
BA_ "VNSigAllNodes" SG_ 381 BrkSysBrkLtsReqd 1;
BA_ "GenSigStartValue" SG_ 1279 ClmCntHtrMinFlwRtRqVDA 1;
BA_ "SignalLongName" SG_ 1279 ClmCntHtrMinFlwRtRqVDA "Climate Control Heater Minimum Flow Rate Request Virtual Device Availability";
BA_ "SignalType" SG_ 1279 ClmCntHtrMinFlwRtRqVDA "ENM";
BA_ "VNSigAllNodes" SG_ 1279 ClmCntHtrMinFlwRtRqVDA 1;
BA_ "SignalLongName" SG_ 1279 ClmCntPrtyHtRqV "Climate Control Priority Heating Request Validity";
BA_ "SignalType" SG_ 1279 ClmCntPrtyHtRqV "ENM";
BA_ "VNSigAllNodes" SG_ 1279 ClmCntPrtyHtRqV 1;
BA_ "GenSigStartValue" SG_ 1279 ClmCntPrtyHtRq 2;
BA_ "SignalLongName" SG_ 1279 ClmCntPrtyHtRq "Climate Control Priority Heating Request";
BA_ "SignalType" SG_ 1279 ClmCntPrtyHtRq "ENM";
BA_ "VNSigAllNodes" SG_ 1279 ClmCntPrtyHtRq 1;
BA_ "SignalLongName" SG_ 1279 ClmCntCalcTrgtCbnHtLdV "Climate Control Calculated Target Cabin Heat Load Validity";
BA_ "SignalType" SG_ 1279 ClmCntCalcTrgtCbnHtLdV "ENM";
BA_ "VNSigAllNodes" SG_ 1279 ClmCntCalcTrgtCbnHtLdV 1;
BA_ "GenSigStartValue" SG_ 1279 ClmCntCalcTrgtCbnHtLd 95.625149414296;
BA_ "SignalLongName" SG_ 1279 ClmCntCalcTrgtCbnHtLd "Climate Control Calculated Target Cabin Heat Load";
BA_ "SignalType" SG_ 1279 ClmCntCalcTrgtCbnHtLd "UNM";
BA_ "VNSigAllNodes" SG_ 1279 ClmCntCalcTrgtCbnHtLd 1;
BA_ "SignalLongName" SG_ 1279 ClmCntMinTrgtClntTmpV "Climate Control Minimum Target Coolant Temperature Validity";
BA_ "SignalType" SG_ 1279 ClmCntMinTrgtClntTmpV "ENM";
BA_ "VNSigAllNodes" SG_ 1279 ClmCntMinTrgtClntTmpV 1;
BA_ "GenSigStartValue" SG_ 1279 ClmCntMinTrgtClntTmp 165.748674010608;
BA_ "SignalLongName" SG_ 1279 ClmCntMinTrgtClntTmp "Climate Control Minimum Target Coolant Temperature";
BA_ "SignalType" SG_ 1279 ClmCntMinTrgtClntTmp "UNM";
BA_ "VNSigAllNodes" SG_ 1279 ClmCntMinTrgtClntTmp 1;
BA_ "SignalLongName" SG_ 1279 ClmCntHtrMinFlwRtRqV "Climate Control Heater Minimum Flow Rate Request Validity";
BA_ "SignalType" SG_ 1279 ClmCntHtrMinFlwRtRqV "ENM";
BA_ "VNSigAllNodes" SG_ 1279 ClmCntHtrMinFlwRtRqV 1;
BA_ "GenSigStartValue" SG_ 1279 ClmCntHtrMinFlwRtRq 47.812574707148;
BA_ "SignalLongName" SG_ 1279 ClmCntHtrMinFlwRtRq "Climate Control Heater Minimum Flow Rate Request";
BA_ "SignalType" SG_ 1279 ClmCntHtrMinFlwRtRq "UNM";
BA_ "VNSigAllNodes" SG_ 1279 ClmCntHtrMinFlwRtRq 1;
BA_ "SignalLongName" SG_ 573 RmtRflshElecPwrRdness "Remote Reflash Electric Power Readiness";
BA_ "SignalType" SG_ 573 RmtRflshElecPwrRdness "UNM";
BA_ "VNSigAllNodes" SG_ 573 RmtRflshElecPwrRdness 1;
BA_ "SignalLongName" SG_ 1277 PrkHtrCoolntTemp "Park Heater Coolant Temperature";
BA_ "SignalType" SG_ 1277 PrkHtrCoolntTemp "UNM";
BA_ "VNSigAllNodes" SG_ 1277 PrkHtrCoolntTemp 1;
BA_ "GenSigDeltaValue" SG_ 1277 PrkHtrCoolntTemp 1;
BA_ "GenSigSendType" SG_ 1277 PrkHtrCoolntTemp 12;
BA_ "GenSigSendOnInit" SG_ 1277 PrkHtrCoolntTemp 1;
BA_ "SignalLongName" SG_ 1277 PrkHtrCoolntTempV "Park Heater Coolant Temperature Validity";
BA_ "SignalType" SG_ 1277 PrkHtrCoolntTempV "ENM";
BA_ "VNSigAllNodes" SG_ 1277 PrkHtrCoolntTempV 1;
BA_ "GenSigSendType" SG_ 1277 PrkHtrCoolntTempV 10;
BA_ "GenSigSendOnInit" SG_ 1277 PrkHtrCoolntTempV 1;
BA_ "SignalLongName" SG_ 1277 PrkHtrAtv "Park Heater Active";
BA_ "SignalType" SG_ 1277 PrkHtrAtv "BLN";
BA_ "VNSigAllNodes" SG_ 1277 PrkHtrAtv 1;
BA_ "GenSigSendType" SG_ 1277 PrkHtrAtv 10;
BA_ "GenSigSendOnInit" SG_ 1277 PrkHtrAtv 1;
BA_ "SignalLongName" SG_ 1277 PrkHtrCoolntTempM "Park Heater Coolant Temperature Mask";
BA_ "SignalType" SG_ 1277 PrkHtrCoolntTempM "ENM";
BA_ "VNSigAllNodes" SG_ 1277 PrkHtrCoolntTempM 1;
BA_ "GenSigSendType" SG_ 1277 PrkHtrCoolntTempM 10;
BA_ "SignalLongName" SG_ 1277 PrkHtrActvTmM "Park Heater Activation Time Mask";
BA_ "SignalType" SG_ 1277 PrkHtrActvTmM "ENM";
BA_ "VNSigAllNodes" SG_ 1277 PrkHtrActvTmM 1;
BA_ "GenSigSendType" SG_ 1277 PrkHtrActvTmM 10;
BA_ "SignalLongName" SG_ 1277 PrkHtrActvTm "Park Heater Activation Time";
BA_ "SignalType" SG_ 1277 PrkHtrActvTm "UNM";
BA_ "VNSigAllNodes" SG_ 1277 PrkHtrActvTm 1;
BA_ "GenSigDeltaValue" SG_ 1277 PrkHtrActvTm 1;
BA_ "GenSigSendType" SG_ 1277 PrkHtrActvTm 12;
BA_ "GenSigSendOnInit" SG_ 1277 PrkHtrActvTm 1;
BA_ "SignalLongName" SG_ 1277 PrkHtrOffTmM "Park Heater Off Time Mask";
BA_ "SignalType" SG_ 1277 PrkHtrOffTmM "ENM";
BA_ "VNSigAllNodes" SG_ 1277 PrkHtrOffTmM 1;
BA_ "GenSigSendType" SG_ 1277 PrkHtrOffTmM 10;
BA_ "SignalLongName" SG_ 1277 PrkHtrOffTm "Park Heater Off Time";
BA_ "SignalType" SG_ 1277 PrkHtrOffTm "UNM";
BA_ "VNSigAllNodes" SG_ 1277 PrkHtrOffTm 1;
BA_ "GenSigDeltaValue" SG_ 1277 PrkHtrOffTm 1;
BA_ "GenSigSendType" SG_ 1277 PrkHtrOffTm 12;
BA_ "GenSigSendOnInit" SG_ 1277 PrkHtrOffTm 1;
BA_ "SignalLongName" SG_ 1277 CCFrBlwFnSpdFbkORLFS "Climate Control Front Blower Fan Speed Feedback Out of Range Low Fault Status";
BA_ "SignalType" SG_ 1277 CCFrBlwFnSpdFbkORLFS "ENM";
BA_ "VNSigAllNodes" SG_ 1277 CCFrBlwFnSpdFbkORLFS 1;
BA_ "SignalLongName" SG_ 1277 CCFrBlwFnSpdFbkORHFS "Climate Control Front Blower Fan Speed Feedback Out of Range High Fault Status";
BA_ "SignalType" SG_ 1277 CCFrBlwFnSpdFbkORHFS "ENM";
BA_ "VNSigAllNodes" SG_ 1277 CCFrBlwFnSpdFbkORHFS 1;
BA_ "SignalLongName" SG_ 1277 CCFrBlwFnSpdFbkDyCyARC "Climate Control Front Blower Fan Speed Feedback Duty Cycle Alive Rolling Count";
BA_ "SignalType" SG_ 1277 CCFrBlwFnSpdFbkDyCyARC "UNM";
BA_ "VNSigAllNodes" SG_ 1277 CCFrBlwFnSpdFbkDyCyARC 1;
BA_ "SignalLongName" SG_ 1277 CCFrBlwFnSpdFbkDyCy "Climate Control Front Blower Fan Speed Feedback Duty Cycle";
BA_ "SignalType" SG_ 1277 CCFrBlwFnSpdFbkDyCy "UNM";
BA_ "VNSigAllNodes" SG_ 1277 CCFrBlwFnSpdFbkDyCy 1;
BA_ "SignalLongName" SG_ 1277 CCFrBlwFnSpdFbkFrqARC "Climate Control Front Blower Fan Speed Feedback Frequency Alive Rolling Count";
BA_ "SignalType" SG_ 1277 CCFrBlwFnSpdFbkFrqARC "UNM";
BA_ "VNSigAllNodes" SG_ 1277 CCFrBlwFnSpdFbkFrqARC 1;
BA_ "SignalLongName" SG_ 1277 CCFrBlwFnSpdFbkFrq "Climate Control Front Blower Fan Speed Feedback Frequency";
BA_ "SignalType" SG_ 1277 CCFrBlwFnSpdFbkFrq "UNM";
BA_ "VNSigAllNodes" SG_ 1277 CCFrBlwFnSpdFbkFrq 1;
BA_ "SignalLongName" SG_ 2034 DgnInf "Diagnostic Information";
BA_ "SignalType" SG_ 2034 DgnInf "UNM";
BA_ "VNSigSLHSSharedDiagnostic" SG_ 2034 DgnInf 1;
BA_ "VNSigAllNodes" SG_ 2034 DgnInf 1;
BA_ "GenSigDeltaValue" SG_ 2034 DgnInf 1;
BA_ "GenSigSendType" SG_ 2034 DgnInf 12;
BA_ "SignalLongName" SG_ 1323 TireLRTmpV "Tire Left Rear Temperature Validity";
BA_ "SignalType" SG_ 1323 TireLRTmpV "ENM";
BA_ "VNSigAllNodes" SG_ 1323 TireLRTmpV 1;
BA_ "SignalLongName" SG_ 1323 TireLRTmp "Tire Left Rear Temperature";
BA_ "SignalType" SG_ 1323 TireLRTmp "UNM";
BA_ "VNSigAllNodes" SG_ 1323 TireLRTmp 1;
BA_ "SignalLongName" SG_ 1323 TireLFTmpV "Tire Left Front Temperature Validity";
BA_ "SignalType" SG_ 1323 TireLFTmpV "ENM";
BA_ "VNSigAllNodes" SG_ 1323 TireLFTmpV 1;
BA_ "SignalLongName" SG_ 1323 TireLFTmp "Tire Left Front Temperature";
BA_ "SignalType" SG_ 1323 TireLFTmp "UNM";
BA_ "VNSigAllNodes" SG_ 1323 TireLFTmp 1;
BA_ "SignalLongName" SG_ 1323 TireRRTmpV "Tire Right Rear Temperature Validity";
BA_ "SignalType" SG_ 1323 TireRRTmpV "ENM";
BA_ "VNSigAllNodes" SG_ 1323 TireRRTmpV 1;
BA_ "SignalLongName" SG_ 1323 TireRRTmp "Tire Right Rear Temperature";
BA_ "SignalType" SG_ 1323 TireRRTmp "UNM";
BA_ "VNSigAllNodes" SG_ 1323 TireRRTmp 1;
BA_ "SignalLongName" SG_ 1323 TireRFTmpV "Tire Right Front Temperature Validity";
BA_ "SignalType" SG_ 1323 TireRFTmpV "ENM";
BA_ "VNSigAllNodes" SG_ 1323 TireRFTmpV 1;
BA_ "SignalLongName" SG_ 1323 TireRFTmp "Tire Right Front Temperature";
BA_ "SignalType" SG_ 1323 TireRFTmp "UNM";
BA_ "VNSigAllNodes" SG_ 1323 TireRFTmp 1;
BA_ "SignalLongName" SG_ 543 HdStV "Hood Status Validity";
BA_ "SignalType" SG_ 543 HdStV "ENM";
BA_ "VNSigAllNodes" SG_ 543 HdStV 1;
BA_ "GenSigSendType" SG_ 543 HdStV 10;
BA_ "SignalLongName" SG_ 543 HdSt "Hood Status";
BA_ "SignalType" SG_ 543 HdSt "ENM";
BA_ "VNSigAllNodes" SG_ 543 HdSt 1;
BA_ "GenSigSendType" SG_ 543 HdSt 10;
BA_ "GenSigSendOnInit" SG_ 543 HdSt 2;
BA_ "SignalLongName" SG_ 543 PTOTpStpSpdCsStReq "Power Take Off Tap Step Speed Customization Setting Request";
BA_ "SignalType" SG_ 543 PTOTpStpSpdCsStReq "ENM";
BA_ "VNSigAllNodes" SG_ 543 PTOTpStpSpdCsStReq 1;
BA_ "GenSigSendType" SG_ 543 PTOTpStpSpdCsStReq 10;
BA_ "SignalLongName" SG_ 543 PTOStdbySpdCsStReq "Power Take Off Standby Speed Customization Setting Request";
BA_ "SignalType" SG_ 543 PTOStdbySpdCsStReq "ENM";
BA_ "VNSigAllNodes" SG_ 543 PTOStdbySpdCsStReq 1;
BA_ "GenSigSendType" SG_ 543 PTOStdbySpdCsStReq 10;
BA_ "SignalLongName" SG_ 543 PTOEngRnTmrCsStRq "Power Take Off Engine Run Timer Customization Setting Request";
BA_ "SignalType" SG_ 543 PTOEngRnTmrCsStRq "ENM";
BA_ "VNSigAllNodes" SG_ 543 PTOEngRnTmrCsStRq 1;
BA_ "GenSigSendType" SG_ 543 PTOEngRnTmrCsStRq 10;
BA_ "SignalLongName" SG_ 543 PTOSet2SpdCsStReq "Power Take Off Set 2 Speed Customization Setting Request";
BA_ "SignalType" SG_ 543 PTOSet2SpdCsStReq "ENM";
BA_ "VNSigAllNodes" SG_ 543 PTOSet2SpdCsStReq 1;
BA_ "GenSigSendType" SG_ 543 PTOSet2SpdCsStReq 10;
BA_ "SignalLongName" SG_ 543 PTOSet1SpdCsStReq "Power Take Off Set 1 Speed Customization Setting Request";
BA_ "SignalType" SG_ 543 PTOSet1SpdCsStReq "ENM";
BA_ "VNSigAllNodes" SG_ 543 PTOSet1SpdCsStReq 1;
BA_ "GenSigSendType" SG_ 543 PTOSet1SpdCsStReq 10;
BA_ "GenSigStartValue" SG_ 1221 CCClntCrcFlwRtReqVDA 1;
BA_ "SignalLongName" SG_ 1221 CCClntCrcFlwRtReqVDA "Climate Control Coolant Circulation Flow Rate Request Virtual Device Availability";
BA_ "SignalType" SG_ 1221 CCClntCrcFlwRtReqVDA "ENM";
BA_ "VNSigAllNodes" SG_ 1221 CCClntCrcFlwRtReqVDA 1;
BA_ "SignalLongName" SG_ 1221 PTExPrtclFltManRgnRqd "Powertrain Exhaust Particle Filter Manual Regeneration Requested";
BA_ "SignalType" SG_ 1221 PTExPrtclFltManRgnRqd "BLN";
BA_ "VNSigAllNodes" SG_ 1221 PTExPrtclFltManRgnRqd 1;
BA_ "GenSigSendType" SG_ 1221 PTExPrtclFltManRgnRqd 10;
BA_ "SignalLongName" SG_ 1221 SpdLmtVsnFsdSpdUnt "Speed Limit Vision Fused Speed Unit";
BA_ "SignalType" SG_ 1221 SpdLmtVsnFsdSpdUnt "ENM";
BA_ "VNSigAllNodes" SG_ 1221 SpdLmtVsnFsdSpdUnt 1;
BA_ "GenSigSendType" SG_ 1221 SpdLmtVsnFsdSpdUnt 10;
BA_ "SignalLongName" SG_ 1221 SpdLmtVnFsSpdNwDet "Speed Limit Vision Fused Speed New Detected";
BA_ "SignalType" SG_ 1221 SpdLmtVnFsSpdNwDet "BLN";
BA_ "VNSigAllNodes" SG_ 1221 SpdLmtVnFsSpdNwDet 1;
BA_ "GenSigSendType" SG_ 1221 SpdLmtVnFsSpdNwDet 10;
BA_ "SignalLongName" SG_ 1221 SpdLmtVsnFsdSpdM "Speed Limit Vision Fused Speed Mask";
BA_ "SignalType" SG_ 1221 SpdLmtVsnFsdSpdM "ENM";
BA_ "VNSigAllNodes" SG_ 1221 SpdLmtVsnFsdSpdM 1;
BA_ "GenSigSendType" SG_ 1221 SpdLmtVsnFsdSpdM 10;
BA_ "SignalLongName" SG_ 1221 SpdLmtVsnFsdSpd "Speed Limit Vision Fused Speed";
BA_ "SignalType" SG_ 1221 SpdLmtVsnFsdSpd "UNM";
BA_ "VNSigAllNodes" SG_ 1221 SpdLmtVsnFsdSpd 1;
BA_ "GenSigDeltaValue" SG_ 1221 SpdLmtVsnFsdSpd 1;
BA_ "GenSigSendType" SG_ 1221 SpdLmtVsnFsdSpd 12;
BA_ "SignalLongName" SG_ 1221 CCClntCrcFlwRtReq "Climate Control Coolant Circulation Flow Rate Request";
BA_ "SignalType" SG_ 1221 CCClntCrcFlwRtReq "UNM";
BA_ "VNSigAllNodes" SG_ 1221 CCClntCrcFlwRtReq 1;
BA_ "GenSigDeltaValue" SG_ 1221 CCClntCrcFlwRtReq 1;
BA_ "GenSigSendType" SG_ 1221 CCClntCrcFlwRtReq 12;
BA_ "GenSigSendOnInit" SG_ 1221 CCClntCrcFlwRtReq 2;
BA_ "GenSigStartValue" SG_ 1239 IBSBatSOC 196;
BA_ "SignalLongName" SG_ 1239 IBSBatSOC "Intelligent Battery Sensor Battery State of Charge";
BA_ "SignalType" SG_ 1239 IBSBatSOC "UNM";
BA_ "VNSigAllNodes" SG_ 1239 IBSBatSOC 1;
BA_ "GenSigStartValue" SG_ 1239 BattTemp 65;
BA_ "SignalLongName" SG_ 1239 BattTemp "Battery Temperature";
BA_ "SignalType" SG_ 1239 BattTemp "UNM";
BA_ "VNSigAllNodes" SG_ 1239 BattTemp 1;
BA_ "GenSigStartValue" SG_ 1239 BatSOH 203.999928600025;
BA_ "SignalLongName" SG_ 1239 BatSOH "Battery State Of Health";
BA_ "SignalType" SG_ 1239 BatSOH "UNM";
BA_ "VNSigAllNodes" SG_ 1239 BatSOH 1;
BA_ "GenSigStartValue" SG_ 1239 BatSOFVolt 200;
BA_ "SignalLongName" SG_ 1239 BatSOFVolt "Battery State Of Function Voltage";
BA_ "SignalType" SG_ 1239 BatSOFVolt "UNM";
BA_ "VNSigAllNodes" SG_ 1239 BatSOFVolt 1;
BA_ "SignalLongName" SG_ 1239 BattSOXStat "Battery SOX Status";
BA_ "SignalType" SG_ 1239 BattSOXStat "ENM";
BA_ "VNSigAllNodes" SG_ 1239 BattSOXStat 1;
BA_ "SignalLongName" SG_ 1239 BattTempV "Battery Temperature Validity";
BA_ "SignalType" SG_ 1239 BattTempV "ENM";
BA_ "VNSigAllNodes" SG_ 1239 BattTempV 1;
BA_ "SignalLongName" SG_ 971 BatVltHiResV "Battery Voltage High Resolution Validity";
BA_ "SignalType" SG_ 971 BatVltHiResV "ENM";
BA_ "VNSigAllNodes" SG_ 971 BatVltHiResV 1;
BA_ "GenSigStartValue" SG_ 971 BatVltHiRes 12800;
BA_ "SignalLongName" SG_ 971 BatVltHiRes "Battery Voltage High Resolution";
BA_ "SignalType" SG_ 971 BatVltHiRes "UNM";
BA_ "VNSigAllNodes" SG_ 971 BatVltHiRes 1;
BA_ "SignalLongName" SG_ 971 BCHR_BattCrntRwVal "Battery Current High Resolution : Battery Current Raw Value";
BA_ "PacketOrder" SG_ 971 BCHR_BattCrntRwVal 3;
BA_ "SignalType" SG_ 971 BCHR_BattCrntRwVal "UNM";
BA_ "VNSigAllNodes" SG_ 971 BCHR_BattCrntRwVal 1;
BA_ "SignalLongName" SG_ 971 BCHR_BattCrntRwVlMu "Battery Current High Resolution : Battery Current Raw Value Multiplier";
BA_ "PacketOrder" SG_ 971 BCHR_BattCrntRwVlMu 2;
BA_ "SignalType" SG_ 971 BCHR_BattCrntRwVlMu "ENM";
BA_ "VNSigAllNodes" SG_ 971 BCHR_BattCrntRwVlMu 1;
BA_ "SignalLongName" SG_ 971 BCHR_BattCrntRwValV "Battery Current High Resolution : Battery Current Raw Value Validity";
BA_ "PacketOrder" SG_ 971 BCHR_BattCrntRwValV 1;
BA_ "SignalType" SG_ 971 BCHR_BattCrntRwValV "ENM";
BA_ "VNSigAllNodes" SG_ 971 BCHR_BattCrntRwValV 1;
BA_REL_ "GenSigTimeoutTime" BU_SG_REL_ BCM_HS SG_ 985 ManTransIndReq 250;
BA_REL_ "GenSigTimeoutMsg" BU_SG_REL_ BCM_HS SG_ 985 ManTransIndReq 985;
BA_REL_ "GenSigSuprvResp" BU_SG_REL_ BCM_HS SG_ 985 ManTransIndReq 1;
BA_REL_ "GenSigTimeoutTime" BU_SG_REL_ BCM_HS SG_ 985 DrvEffInd 250;
BA_REL_ "GenSigTimeoutMsg" BU_SG_REL_ BCM_HS SG_ 985 DrvEffInd 985;
BA_REL_ "GenSigSuprvResp" BU_SG_REL_ BCM_HS SG_ 985 DrvEffInd 1;
BA_REL_ "GenSigTimeoutTime" BU_SG_REL_ BCM_HS SG_ 985 EngIntkArBstPrExtRng 250;
BA_REL_ "GenSigTimeoutMsg" BU_SG_REL_ BCM_HS SG_ 985 EngIntkArBstPrExtRng 985;
BA_REL_ "GenSigSuprvResp" BU_SG_REL_ BCM_HS SG_ 985 EngIntkArBstPrExtRng 1;
BA_REL_ "GenSigTimeoutTime" BU_SG_REL_ BCM_HS SG_ 985 EDADS_RcmndtFwdGr 250;
BA_REL_ "GenSigTimeoutMsg" BU_SG_REL_ BCM_HS SG_ 985 EDADS_RcmndtFwdGr 985;
BA_REL_ "GenSigSuprvResp" BU_SG_REL_ BCM_HS SG_ 985 EDADS_RcmndtFwdGr 1;
BA_REL_ "GenSigTimeoutTime" BU_SG_REL_ BCM_HS SG_ 985 EDADS_CrntFwdMsdG 250;
BA_REL_ "GenSigTimeoutMsg" BU_SG_REL_ BCM_HS SG_ 985 EDADS_CrntFwdMsdG 985;
BA_REL_ "GenSigSuprvResp" BU_SG_REL_ BCM_HS SG_ 985 EDADS_CrntFwdMsdG 1;
BA_REL_ "GenSigTimeoutTime" BU_SG_REL_ BCM_HS SG_ 985 EDADS_ShftIndStat 250;
BA_REL_ "GenSigTimeoutMsg" BU_SG_REL_ BCM_HS SG_ 985 EDADS_ShftIndStat 985;
BA_REL_ "GenSigSuprvResp" BU_SG_REL_ BCM_HS SG_ 985 EDADS_ShftIndStat 1;
BA_REL_ "GenSigTimeoutTime" BU_SG_REL_ BCM_HS SG_ 985 EDADS_EcoDrvShftIO 250;
BA_REL_ "GenSigTimeoutMsg" BU_SG_REL_ BCM_HS SG_ 985 EDADS_EcoDrvShftIO 985;
BA_REL_ "GenSigSuprvResp" BU_SG_REL_ BCM_HS SG_ 985 EDADS_EcoDrvShftIO 1;
BA_REL_ "GenSigTimeoutTime" BU_SG_REL_ BSM_HS SG_ 1017 ACRfHiSdFldPrs 625;
BA_REL_ "GenSigTimeoutMsg" BU_SG_REL_ BSM_HS SG_ 1017 ACRfHiSdFldPrs 1017;
BA_REL_ "GenSigSuprvResp" BU_SG_REL_ BSM_HS SG_ 1017 ACRfHiSdFldPrs 1;
BA_REL_ "GenSigTimeoutTime" BU_SG_REL_ BCM_HS SG_ 1017 ACRfHiSdFldPrs 630;
BA_REL_ "GenSigTimeoutMsg" BU_SG_REL_ BCM_HS SG_ 1017 ACRfHiSdFldPrs 1017;
BA_REL_ "GenSigVBitResp" BU_SG_REL_ BCM_HS SG_ 1017 ACRfHiSdFldPrs 1;
BA_REL_ "GenSigSuprvResp" BU_SG_REL_ BCM_HS SG_ 1017 ACRfHiSdFldPrs 1;
BA_REL_ "GenSigTimeoutTime" BU_SG_REL_ BCM_HS SG_ 1017 GenFldDutCyc 630;
BA_REL_ "GenSigTimeoutMsg" BU_SG_REL_ BCM_HS SG_ 1017 GenFldDutCyc 1017;
BA_REL_ "GenSigVBitResp" BU_SG_REL_ BCM_HS SG_ 1017 GenFldDutCyc 1;
BA_REL_ "GenSigSuprvResp" BU_SG_REL_ BCM_HS SG_ 1017 GenFldDutCyc 1;
BA_REL_ "GenSigTimeoutTime" BU_SG_REL_ BSM_HS SG_ 1017 FlInjRlCt 625;
BA_REL_ "GenSigTimeoutMsg" BU_SG_REL_ BSM_HS SG_ 1017 FlInjRlCt 1017;
BA_REL_ "GenSigSuprvResp" BU_SG_REL_ BSM_HS SG_ 1017 FlInjRlCt 1;
BA_REL_ "GenSigTimeoutTime" BU_SG_REL_ BSM_HS SG_ 1017 EngCoolFanSpd 625;
BA_REL_ "GenSigTimeoutMsg" BU_SG_REL_ BSM_HS SG_ 1017 EngCoolFanSpd 1017;
BA_REL_ "GenSigSuprvResp" BU_SG_REL_ BSM_HS SG_ 1017 EngCoolFanSpd 1;
BA_REL_ "GenSigTimeoutTime" BU_SG_REL_ BCM_HS SG_ 977 AutoMdSpdLmtStat 250;
BA_REL_ "GenSigTimeoutMsg" BU_SG_REL_ BCM_HS SG_ 977 AutoMdSpdLmtStat 977;
BA_REL_ "GenSigSuprvResp" BU_SG_REL_ BCM_HS SG_ 977 AutoMdSpdLmtStat 1;
BA_REL_ "GenSigTimeoutTime" BU_SG_REL_ BCM_HS SG_ 977 SpdLmtrSpdWrngAct 250;
BA_REL_ "GenSigTimeoutMsg" BU_SG_REL_ BCM_HS SG_ 977 SpdLmtrSpdWrngAct 977;
BA_REL_ "GenSigSuprvResp" BU_SG_REL_ BCM_HS SG_ 977 SpdLmtrSpdWrngAct 1;
BA_REL_ "GenSigTimeoutTime" BU_SG_REL_ TCM_HS SG_ 977 ACCompCmnd 250;
BA_REL_ "GenSigTimeoutMsg" BU_SG_REL_ TCM_HS SG_ 977 ACCompCmnd 977;
BA_REL_ "GenSigSuprvResp" BU_SG_REL_ TCM_HS SG_ 977 ACCompCmnd 1;
BA_REL_ "GenSigTimeoutTime" BU_SG_REL_ BCM_HS SG_ 977 EngBstPrsInd 250;
BA_REL_ "GenSigTimeoutMsg" BU_SG_REL_ BCM_HS SG_ 977 EngBstPrsInd 977;
BA_REL_ "GenSigVBitResp" BU_SG_REL_ BCM_HS SG_ 977 EngBstPrsInd 1;
BA_REL_ "GenSigSuprvResp" BU_SG_REL_ BCM_HS SG_ 977 EngBstPrsInd 1;
BA_REL_ "GenSigTimeoutTime" BU_SG_REL_ BCM_HS SG_ 977 ThrPos 250;
BA_REL_ "GenSigTimeoutMsg" BU_SG_REL_ BCM_HS SG_ 977 ThrPos 977;
BA_REL_ "GenSigVBitResp" BU_SG_REL_ BCM_HS SG_ 977 ThrPos 1;
BA_REL_ "GenSigSuprvResp" BU_SG_REL_ BCM_HS SG_ 977 ThrPos 1;
BA_REL_ "GenSigRxStartValue" BU_SG_REL_ BCM_HS SG_ 977 EngEmsRelMalfIndReq "$0 - Continuous Indication";
BA_REL_ "GenSigTimeoutTime" BU_SG_REL_ TCM_HS SG_ 977 EngCstFlCutAct 250;
BA_REL_ "GenSigTimeoutMsg" BU_SG_REL_ TCM_HS SG_ 977 EngCstFlCutAct 977;
BA_REL_ "GenSigSuprvResp" BU_SG_REL_ TCM_HS SG_ 977 EngCstFlCutAct 1;
BA_REL_ "GenSigTimeoutTime" BU_SG_REL_ CGM_HS SG_ 201 EngCylDactEvntPndg 250;
BA_REL_ "GenSigTimeoutMsg" BU_SG_REL_ CGM_HS SG_ 201 EngCylDactEvntPndg 201;
BA_REL_ "GenSigSuprvResp" BU_SG_REL_ CGM_HS SG_ 201 EngCylDactEvntPndg 1;
BA_REL_ "GenSigTimeoutTime" BU_SG_REL_ CGM_HS SG_ 201 PT_BrkPedDscrtInpStat 250;
BA_REL_ "GenSigTimeoutMsg" BU_SG_REL_ CGM_HS SG_ 201 PT_BrkPedDscrtInpStat 201;
BA_REL_ "GenSigSuprvResp" BU_SG_REL_ CGM_HS SG_ 201 PT_BrkPedDscrtInpStat 1;
BA_REL_ "GenSigTimeoutTime" BU_SG_REL_ TCM_HS SG_ 201 PT_BrkPedDscrtInpStat 31;
BA_REL_ "GenSigTimeoutMsg" BU_SG_REL_ TCM_HS SG_ 201 PT_BrkPedDscrtInpStat 201;
BA_REL_ "GenSigSuprvResp" BU_SG_REL_ TCM_HS SG_ 201 PT_BrkPedDscrtInpStat 1;
BA_REL_ "GenSigTimeoutTime" BU_SG_REL_ EBCM_HS SG_ 201 PT_BrkPedDscrtInpStat 250;
BA_REL_ "GenSigTimeoutMsg" BU_SG_REL_ EBCM_HS SG_ 201 PT_BrkPedDscrtInpStat 201;
BA_REL_ "GenSigSuprvResp" BU_SG_REL_ EBCM_HS SG_ 201 PT_BrkPedDscrtInpStat 1;
BA_REL_ "GenSigTimeoutTime" BU_SG_REL_ CGM_HS SG_ 201 PT_CrnkAct 250;
BA_REL_ "GenSigTimeoutMsg" BU_SG_REL_ CGM_HS SG_ 201 PT_CrnkAct 201;
BA_REL_ "GenSigSuprvResp" BU_SG_REL_ CGM_HS SG_ 201 PT_CrnkAct 1;
BA_REL_ "GenSigTimeoutTime" BU_SG_REL_ EPS_HS SG_ 201 PT_CrnkAct 250;
BA_REL_ "GenSigTimeoutMsg" BU_SG_REL_ EPS_HS SG_ 201 PT_CrnkAct 201;
BA_REL_ "GenSigSuprvResp" BU_SG_REL_ EPS_HS SG_ 201 PT_CrnkAct 1;
BA_REL_ "GenSigTimeoutTime" BU_SG_REL_ EBCM_HS SG_ 201 PT_CrnkAct 250;
BA_REL_ "GenSigTimeoutMsg" BU_SG_REL_ EBCM_HS SG_ 201 PT_CrnkAct 201;
BA_REL_ "GenSigSuprvResp" BU_SG_REL_ EBCM_HS SG_ 201 PT_CrnkAct 1;
BA_REL_ "GenSigTimeoutTime" BU_SG_REL_ BSM_HS SG_ 201 PT_CrnkAct 500;
BA_REL_ "GenSigTimeoutMsg" BU_SG_REL_ BSM_HS SG_ 201 PT_CrnkAct 201;
BA_REL_ "GenSigSuprvResp" BU_SG_REL_ BSM_HS SG_ 201 PT_CrnkAct 1;
BA_REL_ "GenSigTimeoutTime" BU_SG_REL_ CGM_HS SG_ 201 Eng12vStrtrMtrCmmdOn 250;
BA_REL_ "GenSigTimeoutMsg" BU_SG_REL_ CGM_HS SG_ 201 Eng12vStrtrMtrCmmdOn 201;
BA_REL_ "GenSigSuprvResp" BU_SG_REL_ CGM_HS SG_ 201 Eng12vStrtrMtrCmmdOn 1;
BA_REL_ "GenSigTimeoutTime" BU_SG_REL_ EPS_HS SG_ 201 Eng12vStrtrMtrCmmdOn 250;
BA_REL_ "GenSigTimeoutMsg" BU_SG_REL_ EPS_HS SG_ 201 Eng12vStrtrMtrCmmdOn 201;
BA_REL_ "GenSigSuprvResp" BU_SG_REL_ EPS_HS SG_ 201 Eng12vStrtrMtrCmmdOn 1;
BA_REL_ "GenSigTimeoutTime" BU_SG_REL_ EBCM_HS SG_ 201 Eng12vStrtrMtrCmmdOn 250;
BA_REL_ "GenSigTimeoutMsg" BU_SG_REL_ EBCM_HS SG_ 201 Eng12vStrtrMtrCmmdOn 201;
BA_REL_ "GenSigSuprvResp" BU_SG_REL_ EBCM_HS SG_ 201 Eng12vStrtrMtrCmmdOn 1;
BA_REL_ "GenSigTimeoutTime" BU_SG_REL_ BCM_HS SG_ 201 Eng12vStrtrMtrCmmdOn 50;
BA_REL_ "GenSigTimeoutMsg" BU_SG_REL_ BCM_HS SG_ 201 Eng12vStrtrMtrCmmdOn 201;
BA_REL_ "GenSigSuprvResp" BU_SG_REL_ BCM_HS SG_ 201 Eng12vStrtrMtrCmmdOn 1;
BA_REL_ "GenSigTimeoutTime" BU_SG_REL_ CGM_HS SG_ 201 EngCntrlRunCrnkTrmSt 250;
BA_REL_ "GenSigTimeoutMsg" BU_SG_REL_ CGM_HS SG_ 201 EngCntrlRunCrnkTrmSt 201;
BA_REL_ "GenSigSuprvResp" BU_SG_REL_ CGM_HS SG_ 201 EngCntrlRunCrnkTrmSt 1;
BA_REL_ "GenSigTimeoutTime" BU_SG_REL_ EBCM_HS SG_ 201 EngCntrlRunCrnkTrmSt 250;
BA_REL_ "GenSigTimeoutMsg" BU_SG_REL_ EBCM_HS SG_ 201 EngCntrlRunCrnkTrmSt 201;
BA_REL_ "GenSigSuprvResp" BU_SG_REL_ EBCM_HS SG_ 201 EngCntrlRunCrnkTrmSt 1;
BA_REL_ "GenSigTimeoutTime" BU_SG_REL_ BSM_HS SG_ 201 EngCntrlRunCrnkTrmSt 500;
BA_REL_ "GenSigTimeoutMsg" BU_SG_REL_ BSM_HS SG_ 201 EngCntrlRunCrnkTrmSt 201;
BA_REL_ "GenSigSuprvResp" BU_SG_REL_ BSM_HS SG_ 201 EngCntrlRunCrnkTrmSt 1;
BA_REL_ "GenSigTimeoutTime" BU_SG_REL_ BCM_HS SG_ 201 EngCntrlRunCrnkTrmSt 50;
BA_REL_ "GenSigTimeoutMsg" BU_SG_REL_ BCM_HS SG_ 201 EngCntrlRunCrnkTrmSt 201;
BA_REL_ "GenSigSuprvResp" BU_SG_REL_ BCM_HS SG_ 201 EngCntrlRunCrnkTrmSt 1;
BA_REL_ "GenSigTimeoutTime" BU_SG_REL_ CGM_HS SG_ 201 EngAirIntBstPr 250;
BA_REL_ "GenSigTimeoutMsg" BU_SG_REL_ CGM_HS SG_ 201 EngAirIntBstPr 201;
BA_REL_ "GenSigSuprvResp" BU_SG_REL_ CGM_HS SG_ 201 EngAirIntBstPr 1;
BA_REL_ "GenSigTimeoutTime" BU_SG_REL_ EBCM_HS SG_ 201 EngAirIntBstPr 250;
BA_REL_ "GenSigTimeoutMsg" BU_SG_REL_ EBCM_HS SG_ 201 EngAirIntBstPr 201;
BA_REL_ "GenSigSuprvResp" BU_SG_REL_ EBCM_HS SG_ 201 EngAirIntBstPr 1;
BA_REL_ "GenSigTimeoutTime" BU_SG_REL_ CGM_HS SG_ 201 SpdLmtrSpdWrngEnbld 250;
BA_REL_ "GenSigTimeoutMsg" BU_SG_REL_ CGM_HS SG_ 201 SpdLmtrSpdWrngEnbld 201;
BA_REL_ "GenSigSuprvResp" BU_SG_REL_ CGM_HS SG_ 201 SpdLmtrSpdWrngEnbld 1;
BA_REL_ "GenSigTimeoutTime" BU_SG_REL_ CGM_HS SG_ 201 EngCylDeactMd 250;
BA_REL_ "GenSigTimeoutMsg" BU_SG_REL_ CGM_HS SG_ 201 EngCylDeactMd 201;
BA_REL_ "GenSigSuprvResp" BU_SG_REL_ CGM_HS SG_ 201 EngCylDeactMd 1;
BA_REL_ "GenSigTimeoutTime" BU_SG_REL_ CGM_HS SG_ 201 RmVhStrtEngRng 250;
BA_REL_ "GenSigTimeoutMsg" BU_SG_REL_ CGM_HS SG_ 201 RmVhStrtEngRng 201;
BA_REL_ "GenSigSuprvResp" BU_SG_REL_ CGM_HS SG_ 201 RmVhStrtEngRng 1;
BA_REL_ "GenSigTimeoutTime" BU_SG_REL_ EBCM_HS SG_ 201 RmVhStrtEngRng 250;
BA_REL_ "GenSigTimeoutMsg" BU_SG_REL_ EBCM_HS SG_ 201 RmVhStrtEngRng 201;
BA_REL_ "GenSigSuprvResp" BU_SG_REL_ EBCM_HS SG_ 201 RmVhStrtEngRng 1;
BA_REL_ "GenSigTimeoutTime" BU_SG_REL_ BCM_HS SG_ 201 RmVhStrtEngRng 50;
BA_REL_ "GenSigTimeoutMsg" BU_SG_REL_ BCM_HS SG_ 201 RmVhStrtEngRng 201;
BA_REL_ "GenSigSuprvResp" BU_SG_REL_ BCM_HS SG_ 201 RmVhStrtEngRng 2;
BA_REL_ "GenSigTimeoutTime" BU_SG_REL_ CGM_HS SG_ 201 PFEngSpdCmndSpcd 250;
BA_REL_ "GenSigTimeoutMsg" BU_SG_REL_ CGM_HS SG_ 201 PFEngSpdCmndSpcd 201;
BA_REL_ "GenSigSuprvResp" BU_SG_REL_ CGM_HS SG_ 201 PFEngSpdCmndSpcd 1;
BA_REL_ "GenSigTimeoutTime" BU_SG_REL_ CGM_HS SG_ 201 PltfrmEngSpdCmdInhtRq 250;
BA_REL_ "GenSigTimeoutMsg" BU_SG_REL_ CGM_HS SG_ 201 PltfrmEngSpdCmdInhtRq 201;
BA_REL_ "GenSigSuprvResp" BU_SG_REL_ CGM_HS SG_ 201 PltfrmEngSpdCmdInhtRq 1;
BA_REL_ "GenSigRxStartValue" BU_SG_REL_ BCM_HS SG_ 201 PltfrmEngSpdCmdInhtRq "$0-Allow Platform Engine Speed Control";
BA_REL_ "GenSigTimeoutTime" BU_SG_REL_ CGM_HS SG_ 201 AccActPos 250;
BA_REL_ "GenSigTimeoutMsg" BU_SG_REL_ CGM_HS SG_ 201 AccActPos 201;
BA_REL_ "GenSigSuprvResp" BU_SG_REL_ CGM_HS SG_ 201 AccActPos 1;
BA_REL_ "GenSigTimeoutTime" BU_SG_REL_ TCM_HS SG_ 201 AccActPos 31;
BA_REL_ "GenSigTimeoutMsg" BU_SG_REL_ TCM_HS SG_ 201 AccActPos 201;
BA_REL_ "GenSigSuprvResp" BU_SG_REL_ TCM_HS SG_ 201 AccActPos 1;
BA_REL_ "GenSigTimeoutTime" BU_SG_REL_ EBCM_HS SG_ 201 AccActPos 250;
BA_REL_ "GenSigTimeoutMsg" BU_SG_REL_ EBCM_HS SG_ 201 AccActPos 201;
BA_REL_ "GenSigSuprvResp" BU_SG_REL_ EBCM_HS SG_ 201 AccActPos 1;
BA_REL_ "GenSigTimeoutTime" BU_SG_REL_ BSM_HS SG_ 201 AccActPos 500;
BA_REL_ "GenSigTimeoutMsg" BU_SG_REL_ BSM_HS SG_ 201 AccActPos 201;
BA_REL_ "GenSigSuprvResp" BU_SG_REL_ BSM_HS SG_ 201 AccActPos 1;
BA_REL_ "GenSigTimeoutTime" BU_SG_REL_ BCM_HS SG_ 201 AccActPos 50;
BA_REL_ "GenSigTimeoutMsg" BU_SG_REL_ BCM_HS SG_ 201 AccActPos 201;
BA_REL_ "GenSigVBitResp" BU_SG_REL_ BCM_HS SG_ 201 AccActPos 1;
BA_REL_ "GenSigSuprvResp" BU_SG_REL_ BCM_HS SG_ 201 AccActPos 1;
BA_REL_ "GenSigTimeoutTime" BU_SG_REL_ CGM_HS SG_ 201 CrsCntEnbld 250;
BA_REL_ "GenSigTimeoutMsg" BU_SG_REL_ CGM_HS SG_ 201 CrsCntEnbld 201;
BA_REL_ "GenSigSuprvResp" BU_SG_REL_ CGM_HS SG_ 201 CrsCntEnbld 1;
BA_REL_ "GenSigTimeoutTime" BU_SG_REL_ EBCM_HS SG_ 201 CrsCntEnbld 250;
BA_REL_ "GenSigTimeoutMsg" BU_SG_REL_ EBCM_HS SG_ 201 CrsCntEnbld 201;
BA_REL_ "GenSigSuprvResp" BU_SG_REL_ EBCM_HS SG_ 201 CrsCntEnbld 1;
BA_REL_ "GenSigTimeoutTime" BU_SG_REL_ CGM_HS SG_ 201 CrsCntAtv 250;
BA_REL_ "GenSigTimeoutMsg" BU_SG_REL_ CGM_HS SG_ 201 CrsCntAtv 201;
BA_REL_ "GenSigSuprvResp" BU_SG_REL_ CGM_HS SG_ 201 CrsCntAtv 1;
BA_REL_ "GenSigTimeoutTime" BU_SG_REL_ TCM_HS SG_ 201 CrsCntAtv 31;
BA_REL_ "GenSigTimeoutMsg" BU_SG_REL_ TCM_HS SG_ 201 CrsCntAtv 201;
BA_REL_ "GenSigSuprvResp" BU_SG_REL_ TCM_HS SG_ 201 CrsCntAtv 1;
BA_REL_ "GenSigTimeoutTime" BU_SG_REL_ EBCM_HS SG_ 201 CrsCntAtv 250;
BA_REL_ "GenSigTimeoutMsg" BU_SG_REL_ EBCM_HS SG_ 201 CrsCntAtv 201;
BA_REL_ "GenSigSuprvResp" BU_SG_REL_ EBCM_HS SG_ 201 CrsCntAtv 1;
BA_REL_ "GenSigTimeoutTime" BU_SG_REL_ CGM_HS SG_ 201 DrvThrottlOvrrdDet 250;
BA_REL_ "GenSigTimeoutMsg" BU_SG_REL_ CGM_HS SG_ 201 DrvThrottlOvrrdDet 201;
BA_REL_ "GenSigSuprvResp" BU_SG_REL_ CGM_HS SG_ 201 DrvThrottlOvrrdDet 1;
BA_REL_ "GenSigTimeoutTime" BU_SG_REL_ EBCM_HS SG_ 201 DrvThrottlOvrrdDet 250;
BA_REL_ "GenSigTimeoutMsg" BU_SG_REL_ EBCM_HS SG_ 201 DrvThrottlOvrrdDet 201;
BA_REL_ "GenSigSuprvResp" BU_SG_REL_ EBCM_HS SG_ 201 DrvThrottlOvrrdDet 1;
BA_REL_ "GenSigTimeoutTime" BU_SG_REL_ CGM_HS SG_ 201 PTRunAbrt 250;
BA_REL_ "GenSigTimeoutMsg" BU_SG_REL_ CGM_HS SG_ 201 PTRunAbrt 201;
BA_REL_ "GenSigSuprvResp" BU_SG_REL_ CGM_HS SG_ 201 PTRunAbrt 1;
BA_REL_ "GenSigTimeoutTime" BU_SG_REL_ BCM_HS SG_ 201 PTRunAbrt 50;
BA_REL_ "GenSigTimeoutMsg" BU_SG_REL_ BCM_HS SG_ 201 PTRunAbrt 201;
BA_REL_ "GenSigSuprvRespSubValue" BU_SG_REL_ BCM_HS SG_ 201 PTRunAbrt 1;
BA_REL_ "GenSigSuprvResp" BU_SG_REL_ BCM_HS SG_ 201 PTRunAbrt 2;
BA_REL_ "GenSigTimeoutTime" BU_SG_REL_ CGM_HS SG_ 201 PTO_PT_RunAbrtd 250;
BA_REL_ "GenSigTimeoutMsg" BU_SG_REL_ CGM_HS SG_ 201 PTO_PT_RunAbrtd 201;
BA_REL_ "GenSigSuprvResp" BU_SG_REL_ CGM_HS SG_ 201 PTO_PT_RunAbrtd 1;
BA_REL_ "GenSigTimeoutTime" BU_SG_REL_ CGM_HS SG_ 201 PTCrnkAbrted 250;
BA_REL_ "GenSigTimeoutMsg" BU_SG_REL_ CGM_HS SG_ 201 PTCrnkAbrted 201;
BA_REL_ "GenSigSuprvResp" BU_SG_REL_ CGM_HS SG_ 201 PTCrnkAbrted 1;
BA_REL_ "GenSigTimeoutTime" BU_SG_REL_ CGM_HS SG_ 201 EngSpdStat 250;
BA_REL_ "GenSigTimeoutMsg" BU_SG_REL_ CGM_HS SG_ 201 EngSpdStat 201;
BA_REL_ "GenSigSuprvResp" BU_SG_REL_ CGM_HS SG_ 201 EngSpdStat 1;
BA_REL_ "GenSigTimeoutTime" BU_SG_REL_ TCM_HS SG_ 201 EngSpdStat 31;
BA_REL_ "GenSigTimeoutMsg" BU_SG_REL_ TCM_HS SG_ 201 EngSpdStat 201;
BA_REL_ "GenSigSuprvResp" BU_SG_REL_ TCM_HS SG_ 201 EngSpdStat 1;
BA_REL_ "GenSigTimeoutTime" BU_SG_REL_ EPS_HS SG_ 201 EngSpdStat 250;
BA_REL_ "GenSigTimeoutMsg" BU_SG_REL_ EPS_HS SG_ 201 EngSpdStat 201;
BA_REL_ "GenSigSuprvResp" BU_SG_REL_ EPS_HS SG_ 201 EngSpdStat 1;
BA_REL_ "GenSigTimeoutTime" BU_SG_REL_ EBCM_HS SG_ 201 EngSpdStat 250;
BA_REL_ "GenSigTimeoutMsg" BU_SG_REL_ EBCM_HS SG_ 201 EngSpdStat 201;
BA_REL_ "GenSigSuprvResp" BU_SG_REL_ EBCM_HS SG_ 201 EngSpdStat 1;
BA_REL_ "GenSigTimeoutTime" BU_SG_REL_ CGM_HS SG_ 201 EngSpd 250;
BA_REL_ "GenSigTimeoutMsg" BU_SG_REL_ CGM_HS SG_ 201 EngSpd 201;
BA_REL_ "GenSigSuprvResp" BU_SG_REL_ CGM_HS SG_ 201 EngSpd 1;
BA_REL_ "GenSigTimeoutTime" BU_SG_REL_ TCM_HS SG_ 201 EngSpd 31;
BA_REL_ "GenSigTimeoutMsg" BU_SG_REL_ TCM_HS SG_ 201 EngSpd 201;
BA_REL_ "GenSigSuprvResp" BU_SG_REL_ TCM_HS SG_ 201 EngSpd 1;
BA_REL_ "GenSigTimeoutTime" BU_SG_REL_ RDCM_HS SG_ 201 EngSpd 250;
BA_REL_ "GenSigTimeoutMsg" BU_SG_REL_ RDCM_HS SG_ 201 EngSpd 201;
BA_REL_ "GenSigSuprvResp" BU_SG_REL_ RDCM_HS SG_ 201 EngSpd 1;
BA_REL_ "GenSigTimeoutTime" BU_SG_REL_ EPS_HS SG_ 201 EngSpd 250;
BA_REL_ "GenSigTimeoutMsg" BU_SG_REL_ EPS_HS SG_ 201 EngSpd 201;
BA_REL_ "GenSigSuprvResp" BU_SG_REL_ EPS_HS SG_ 201 EngSpd 1;
BA_REL_ "GenSigTimeoutTime" BU_SG_REL_ EBCM_HS SG_ 201 EngSpd 250;
BA_REL_ "GenSigTimeoutMsg" BU_SG_REL_ EBCM_HS SG_ 201 EngSpd 201;
BA_REL_ "GenSigSuprvResp" BU_SG_REL_ EBCM_HS SG_ 201 EngSpd 1;
BA_REL_ "GenSigTimeoutTime" BU_SG_REL_ BSM_HS SG_ 201 EngSpd 500;
BA_REL_ "GenSigTimeoutMsg" BU_SG_REL_ BSM_HS SG_ 201 EngSpd 201;
BA_REL_ "GenSigSuprvResp" BU_SG_REL_ BSM_HS SG_ 201 EngSpd 1;
BA_REL_ "GenSigTimeoutTime" BU_SG_REL_ BCM_HS SG_ 201 EngSpd 50;
BA_REL_ "GenSigTimeoutMsg" BU_SG_REL_ BCM_HS SG_ 201 EngSpd 201;
BA_REL_ "GenSigSuprvResp" BU_SG_REL_ BCM_HS SG_ 201 EngSpd 1;
BA_REL_ "GenSigTimeoutTime" BU_SG_REL_ CGM_HS SG_ 201 EngRunAtv 250;
BA_REL_ "GenSigTimeoutMsg" BU_SG_REL_ CGM_HS SG_ 201 EngRunAtv 201;
BA_REL_ "GenSigSuprvResp" BU_SG_REL_ CGM_HS SG_ 201 EngRunAtv 1;
BA_REL_ "GenSigTimeoutTime" BU_SG_REL_ EPS_HS SG_ 201 EngRunAtv 250;
BA_REL_ "GenSigTimeoutMsg" BU_SG_REL_ EPS_HS SG_ 201 EngRunAtv 201;
BA_REL_ "GenSigSuprvResp" BU_SG_REL_ EPS_HS SG_ 201 EngRunAtv 1;
BA_REL_ "GenSigTimeoutTime" BU_SG_REL_ EBCM_HS SG_ 201 EngRunAtv 250;
BA_REL_ "GenSigTimeoutMsg" BU_SG_REL_ EBCM_HS SG_ 201 EngRunAtv 201;
BA_REL_ "GenSigSuprvResp" BU_SG_REL_ EBCM_HS SG_ 201 EngRunAtv 1;
BA_REL_ "GenSigTimeoutTime" BU_SG_REL_ BSM_HS SG_ 201 EngRunAtv 500;
BA_REL_ "GenSigTimeoutMsg" BU_SG_REL_ BSM_HS SG_ 201 EngRunAtv 201;
BA_REL_ "GenSigSuprvResp" BU_SG_REL_ BSM_HS SG_ 201 EngRunAtv 1;
BA_REL_ "GenSigTimeoutTime" BU_SG_REL_ BCM_HS SG_ 201 EngRunAtv 50;
BA_REL_ "GenSigTimeoutMsg" BU_SG_REL_ BCM_HS SG_ 201 EngRunAtv 201;
BA_REL_ "GenSigSuprvResp" BU_SG_REL_ BCM_HS SG_ 201 EngRunAtv 1;
BA_REL_ "GenSigTimeoutTime" BU_SG_REL_ CGM_HS SG_ 201 EngIdlAtv 250;
BA_REL_ "GenSigTimeoutMsg" BU_SG_REL_ CGM_HS SG_ 201 EngIdlAtv 201;
BA_REL_ "GenSigSuprvResp" BU_SG_REL_ CGM_HS SG_ 201 EngIdlAtv 1;
BA_REL_ "GenSigTimeoutTime" BU_SG_REL_ CGM_HS SG_ 501 TrnsPattSelEcnMdOCm 250;
BA_REL_ "GenSigTimeoutMsg" BU_SG_REL_ CGM_HS SG_ 501 TrnsPattSelEcnMdOCm 501;
BA_REL_ "GenSigSuprvResp" BU_SG_REL_ CGM_HS SG_ 501 TrnsPattSelEcnMdOCm 1;
BA_REL_ "GenSigTimeoutTime" BU_SG_REL_ CGM_HS SG_ 501 TrnsFldPrsPrsnt 250;
BA_REL_ "GenSigTimeoutMsg" BU_SG_REL_ CGM_HS SG_ 501 TrnsFldPrsPrsnt 501;
BA_REL_ "GenSigSuprvResp" BU_SG_REL_ CGM_HS SG_ 501 TrnsFldPrsPrsnt 1;
BA_REL_ "GenSigTimeoutTime" BU_SG_REL_ CGM_HS SG_ 501 TrnsTrqCnvCltCmndMd 250;
BA_REL_ "GenSigTimeoutMsg" BU_SG_REL_ CGM_HS SG_ 501 TrnsTrqCnvCltCmndMd 501;
BA_REL_ "GenSigSuprvResp" BU_SG_REL_ CGM_HS SG_ 501 TrnsTrqCnvCltCmndMd 1;
BA_REL_ "GenSigTimeoutTime" BU_SG_REL_ ECM_HS SG_ 501 TrnsTrqCnvCltCmndMd 62;
BA_REL_ "GenSigTimeoutMsg" BU_SG_REL_ ECM_HS SG_ 501 TrnsTrqCnvCltCmndMd 501;
BA_REL_ "GenSigSuprvResp" BU_SG_REL_ ECM_HS SG_ 501 TrnsTrqCnvCltCmndMd 1;
BA_REL_ "GenSigTimeoutTime" BU_SG_REL_ CGM_HS SG_ 501 CltchPdlActPos 250;
BA_REL_ "GenSigTimeoutMsg" BU_SG_REL_ CGM_HS SG_ 501 CltchPdlActPos 501;
BA_REL_ "GenSigSuprvResp" BU_SG_REL_ CGM_HS SG_ 501 CltchPdlActPos 1;
BA_REL_ "GenSigTimeoutTime" BU_SG_REL_ EBCM_HS SG_ 501 CltchPdlActPos 250;
BA_REL_ "GenSigTimeoutMsg" BU_SG_REL_ EBCM_HS SG_ 501 CltchPdlActPos 501;
BA_REL_ "GenSigSuprvResp" BU_SG_REL_ EBCM_HS SG_ 501 CltchPdlActPos 1;
BA_REL_ "GenSigTimeoutTime" BU_SG_REL_ CGM_HS SG_ 501 AutoTransGrSftDirect 250;
BA_REL_ "GenSigTimeoutMsg" BU_SG_REL_ CGM_HS SG_ 501 AutoTransGrSftDirect 501;
BA_REL_ "GenSigSuprvResp" BU_SG_REL_ CGM_HS SG_ 501 AutoTransGrSftDirect 1;
BA_REL_ "GenSigTimeoutTime" BU_SG_REL_ EBCM_HS SG_ 501 AutoTransGrSftDirect 250;
BA_REL_ "GenSigTimeoutMsg" BU_SG_REL_ EBCM_HS SG_ 501 AutoTransGrSftDirect 501;
BA_REL_ "GenSigSuprvResp" BU_SG_REL_ EBCM_HS SG_ 501 AutoTransGrSftDirect 1;
BA_REL_ "GenSigTimeoutTime" BU_SG_REL_ CGM_HS SG_ 501 TmpDrvrShftCtlAct 250;
BA_REL_ "GenSigTimeoutMsg" BU_SG_REL_ CGM_HS SG_ 501 TmpDrvrShftCtlAct 501;
BA_REL_ "GenSigSuprvResp" BU_SG_REL_ CGM_HS SG_ 501 TmpDrvrShftCtlAct 1;
BA_REL_ "GenSigTimeoutTime" BU_SG_REL_ BCM_HS SG_ 501 TmpDrvrShftCtlAct 250;
BA_REL_ "GenSigTimeoutMsg" BU_SG_REL_ BCM_HS SG_ 501 TmpDrvrShftCtlAct 501;
BA_REL_ "GenSigSuprvResp" BU_SG_REL_ BCM_HS SG_ 501 TmpDrvrShftCtlAct 1;
BA_REL_ "GenSigTimeoutTime" BU_SG_REL_ CGM_HS SG_ 501 EngRecDwnshftIO 250;
BA_REL_ "GenSigTimeoutMsg" BU_SG_REL_ CGM_HS SG_ 501 EngRecDwnshftIO 501;
BA_REL_ "GenSigSuprvResp" BU_SG_REL_ CGM_HS SG_ 501 EngRecDwnshftIO 1;
BA_REL_ "GenSigTimeoutTime" BU_SG_REL_ CGM_HS SG_ 501 CltStartSwAtv 250;
BA_REL_ "GenSigTimeoutMsg" BU_SG_REL_ CGM_HS SG_ 501 CltStartSwAtv 501;
BA_REL_ "GenSigSuprvResp" BU_SG_REL_ CGM_HS SG_ 501 CltStartSwAtv 1;
BA_REL_ "GenSigRxStartValue" BU_SG_REL_ RDCM_HS SG_ 501 CltStartSwAtv "True ($1)";
BA_REL_ "GenSigTimeoutTime" BU_SG_REL_ BCM_HS SG_ 501 CltStartSwAtv 250;
BA_REL_ "GenSigTimeoutMsg" BU_SG_REL_ BCM_HS SG_ 501 CltStartSwAtv 501;
BA_REL_ "GenSigVBitResp" BU_SG_REL_ BCM_HS SG_ 501 CltStartSwAtv 1;
BA_REL_ "GenSigSuprvResp" BU_SG_REL_ BCM_HS SG_ 501 CltStartSwAtv 1;
BA_REL_ "GenSigTimeoutTime" BU_SG_REL_ CGM_HS SG_ 501 TrnsEngdState 250;
BA_REL_ "GenSigTimeoutMsg" BU_SG_REL_ CGM_HS SG_ 501 TrnsEngdState 501;
BA_REL_ "GenSigSuprvResp" BU_SG_REL_ CGM_HS SG_ 501 TrnsEngdState 1;
BA_REL_ "GenSigTimeoutTime" BU_SG_REL_ EBCM_HS SG_ 501 TrnsEngdState 250;
BA_REL_ "GenSigTimeoutMsg" BU_SG_REL_ EBCM_HS SG_ 501 TrnsEngdState 501;
BA_REL_ "GenSigSuprvResp" BU_SG_REL_ EBCM_HS SG_ 501 TrnsEngdState 1;
BA_REL_ "GenSigTimeoutTime" BU_SG_REL_ BCM_HS SG_ 501 TrnsEngdState 250;
BA_REL_ "GenSigTimeoutMsg" BU_SG_REL_ BCM_HS SG_ 501 TrnsEngdState 501;
BA_REL_ "GenSigVBitResp" BU_SG_REL_ BCM_HS SG_ 501 TrnsEngdState 1;
BA_REL_ "GenSigSuprvResp" BU_SG_REL_ BCM_HS SG_ 501 TrnsEngdState 1;
BA_REL_ "GenSigTimeoutTime" BU_SG_REL_ CGM_HS SG_ 501 TrnsShftLvrLckRqd 250;
BA_REL_ "GenSigTimeoutMsg" BU_SG_REL_ CGM_HS SG_ 501 TrnsShftLvrLckRqd 501;
BA_REL_ "GenSigSuprvResp" BU_SG_REL_ CGM_HS SG_ 501 TrnsShftLvrLckRqd 1;
BA_REL_ "GenSigTimeoutTime" BU_SG_REL_ CGM_HS SG_ 501 TransTUDMdStat 250;
BA_REL_ "GenSigTimeoutMsg" BU_SG_REL_ CGM_HS SG_ 501 TransTUDMdStat 501;
BA_REL_ "GenSigSuprvResp" BU_SG_REL_ CGM_HS SG_ 501 TransTUDMdStat 1;
BA_REL_ "GenSigTimeoutTime" BU_SG_REL_ ECM_HS SG_ 501 TransTUDMdStat 62;
BA_REL_ "GenSigTimeoutMsg" BU_SG_REL_ ECM_HS SG_ 501 TransTUDMdStat 501;
BA_REL_ "GenSigSuprvResp" BU_SG_REL_ ECM_HS SG_ 501 TransTUDMdStat 1;
BA_REL_ "GenSigTimeoutTime" BU_SG_REL_ EBCM_HS SG_ 501 TransTUDMdStat 250;
BA_REL_ "GenSigTimeoutMsg" BU_SG_REL_ EBCM_HS SG_ 501 TransTUDMdStat 501;
BA_REL_ "GenSigSuprvResp" BU_SG_REL_ EBCM_HS SG_ 501 TransTUDMdStat 1;
BA_REL_ "GenSigTimeoutTime" BU_SG_REL_ BCM_HS SG_ 501 TransTUDMdStat 250;
BA_REL_ "GenSigTimeoutMsg" BU_SG_REL_ BCM_HS SG_ 501 TransTUDMdStat 501;
BA_REL_ "GenSigSuprvResp" BU_SG_REL_ BCM_HS SG_ 501 TransTUDMdStat 1;
BA_REL_ "GenSigTimeoutTime" BU_SG_REL_ CGM_HS SG_ 501 TrnCrpMdAtv 250;
BA_REL_ "GenSigTimeoutMsg" BU_SG_REL_ CGM_HS SG_ 501 TrnCrpMdAtv 501;
BA_REL_ "GenSigSuprvResp" BU_SG_REL_ CGM_HS SG_ 501 TrnCrpMdAtv 1;
BA_REL_ "GenSigTimeoutTime" BU_SG_REL_ CGM_HS SG_ 501 TrnsSkpShftIO 250;
BA_REL_ "GenSigTimeoutMsg" BU_SG_REL_ CGM_HS SG_ 501 TrnsSkpShftIO 501;
BA_REL_ "GenSigSuprvResp" BU_SG_REL_ CGM_HS SG_ 501 TrnsSkpShftIO 1;
BA_REL_ "GenSigTimeoutTime" BU_SG_REL_ CGM_HS SG_ 501 TrnsSftMdStat 250;
BA_REL_ "GenSigTimeoutMsg" BU_SG_REL_ CGM_HS SG_ 501 TrnsSftMdStat 501;
BA_REL_ "GenSigSuprvResp" BU_SG_REL_ CGM_HS SG_ 501 TrnsSftMdStat 1;
BA_REL_ "GenSigTimeoutTime" BU_SG_REL_ EBCM_HS SG_ 501 TrnsSftMdStat 250;
BA_REL_ "GenSigTimeoutMsg" BU_SG_REL_ EBCM_HS SG_ 501 TrnsSftMdStat 501;
BA_REL_ "GenSigSuprvResp" BU_SG_REL_ EBCM_HS SG_ 501 TrnsSftMdStat 1;
BA_REL_ "GenSigTimeoutTime" BU_SG_REL_ CGM_HS SG_ 501 TrnsRngInhbtStat 250;
BA_REL_ "GenSigTimeoutMsg" BU_SG_REL_ CGM_HS SG_ 501 TrnsRngInhbtStat 501;
BA_REL_ "GenSigSuprvResp" BU_SG_REL_ CGM_HS SG_ 501 TrnsRngInhbtStat 1;
BA_REL_ "GenSigTimeoutTime" BU_SG_REL_ CGM_HS SG_ 501 TopTrvlCltchSwAct 250;
BA_REL_ "GenSigTimeoutMsg" BU_SG_REL_ CGM_HS SG_ 501 TopTrvlCltchSwAct 501;
BA_REL_ "GenSigSuprvResp" BU_SG_REL_ CGM_HS SG_ 501 TopTrvlCltchSwAct 1;
BA_REL_ "GenSigTimeoutTime" BU_SG_REL_ EBCM_HS SG_ 501 TopTrvlCltchSwAct 250;
BA_REL_ "GenSigTimeoutMsg" BU_SG_REL_ EBCM_HS SG_ 501 TopTrvlCltchSwAct 501;
BA_REL_ "GenSigSuprvResp" BU_SG_REL_ EBCM_HS SG_ 501 TopTrvlCltchSwAct 1;
BA_REL_ "GenSigTimeoutTime" BU_SG_REL_ BCM_HS SG_ 501 TopTrvlCltchSwAct 250;
BA_REL_ "GenSigTimeoutMsg" BU_SG_REL_ BCM_HS SG_ 501 TopTrvlCltchSwAct 501;
BA_REL_ "GenSigVBitResp" BU_SG_REL_ BCM_HS SG_ 501 TopTrvlCltchSwAct 1;
BA_REL_ "GenSigSuprvResp" BU_SG_REL_ BCM_HS SG_ 501 TopTrvlCltchSwAct 1;
BA_REL_ "GenSigTimeoutTime" BU_SG_REL_ CGM_HS SG_ 501 EngRecmndUpshftIO 250;
BA_REL_ "GenSigTimeoutMsg" BU_SG_REL_ CGM_HS SG_ 501 EngRecmndUpshftIO 501;
BA_REL_ "GenSigSuprvResp" BU_SG_REL_ CGM_HS SG_ 501 EngRecmndUpshftIO 1;
BA_REL_ "GenSigTimeoutTime" BU_SG_REL_ CGM_HS SG_ 501 DrvtShftCntrlTrgtGear 250;
BA_REL_ "GenSigTimeoutMsg" BU_SG_REL_ CGM_HS SG_ 501 DrvtShftCntrlTrgtGear 501;
BA_REL_ "GenSigSuprvResp" BU_SG_REL_ CGM_HS SG_ 501 DrvtShftCntrlTrgtGear 1;
BA_REL_ "GenSigTimeoutTime" BU_SG_REL_ CGM_HS SG_ 501 DrShftCntrlReqDndIO 250;
BA_REL_ "GenSigTimeoutMsg" BU_SG_REL_ CGM_HS SG_ 501 DrShftCntrlReqDndIO 501;
BA_REL_ "GenSigSuprvResp" BU_SG_REL_ CGM_HS SG_ 501 DrShftCntrlReqDndIO 1;
BA_REL_ "GenSigTimeoutTime" BU_SG_REL_ CGM_HS SG_ 501 TrnShftPtrnActStat 250;
BA_REL_ "GenSigTimeoutMsg" BU_SG_REL_ CGM_HS SG_ 501 TrnShftPtrnActStat 501;
BA_REL_ "GenSigSuprvResp" BU_SG_REL_ CGM_HS SG_ 501 TrnShftPtrnActStat 1;
BA_REL_ "GenSigTimeoutTime" BU_SG_REL_ EBCM_HS SG_ 501 TrnShftPtrnActStat 250;
BA_REL_ "GenSigTimeoutMsg" BU_SG_REL_ EBCM_HS SG_ 501 TrnShftPtrnActStat 501;
BA_REL_ "GenSigSuprvResp" BU_SG_REL_ EBCM_HS SG_ 501 TrnShftPtrnActStat 1;
BA_REL_ "GenSigTimeoutTime" BU_SG_REL_ CGM_HS SG_ 501 TrnsShftLvrPos 250;
BA_REL_ "GenSigTimeoutMsg" BU_SG_REL_ CGM_HS SG_ 501 TrnsShftLvrPos 501;
BA_REL_ "GenSigSuprvResp" BU_SG_REL_ CGM_HS SG_ 501 TrnsShftLvrPos 1;
BA_REL_ "GenSigTimeoutTime" BU_SG_REL_ RDCM_HS SG_ 501 TrnsShftLvrPos 250;
BA_REL_ "GenSigTimeoutMsg" BU_SG_REL_ RDCM_HS SG_ 501 TrnsShftLvrPos 501;
BA_REL_ "GenSigSuprvResp" BU_SG_REL_ RDCM_HS SG_ 501 TrnsShftLvrPos 1;
BA_REL_ "GenSigTimeoutTime" BU_SG_REL_ EPS_HS SG_ 501 TrnsShftLvrPos 250;
BA_REL_ "GenSigTimeoutMsg" BU_SG_REL_ EPS_HS SG_ 501 TrnsShftLvrPos 501;
BA_REL_ "GenSigSuprvResp" BU_SG_REL_ EPS_HS SG_ 501 TrnsShftLvrPos 1;
BA_REL_ "GenSigTimeoutTime" BU_SG_REL_ EBCM_HS SG_ 501 TrnsShftLvrPos 250;
BA_REL_ "GenSigTimeoutMsg" BU_SG_REL_ EBCM_HS SG_ 501 TrnsShftLvrPos 501;
BA_REL_ "GenSigSuprvResp" BU_SG_REL_ EBCM_HS SG_ 501 TrnsShftLvrPos 1;
BA_REL_ "GenSigTimeoutTime" BU_SG_REL_ BSM_HS SG_ 501 TrnsShftLvrPos 500;
BA_REL_ "GenSigTimeoutMsg" BU_SG_REL_ BSM_HS SG_ 501 TrnsShftLvrPos 501;
BA_REL_ "GenSigSuprvResp" BU_SG_REL_ BSM_HS SG_ 501 TrnsShftLvrPos 1;
BA_REL_ "GenSigTimeoutTime" BU_SG_REL_ BCM_HS SG_ 501 TrnsShftLvrPos 250;
BA_REL_ "GenSigTimeoutMsg" BU_SG_REL_ BCM_HS SG_ 501 TrnsShftLvrPos 501;
BA_REL_ "GenSigVBitResp" BU_SG_REL_ BCM_HS SG_ 501 TrnsShftLvrPos 1;
BA_REL_ "GenSigSuprvResp" BU_SG_REL_ BCM_HS SG_ 501 TrnsShftLvrPos 1;
BA_REL_ "GenSigTimeoutTime" BU_SG_REL_ CGM_HS SG_ 501 AutoTransComndGear 250;
BA_REL_ "GenSigTimeoutMsg" BU_SG_REL_ CGM_HS SG_ 501 AutoTransComndGear 501;
BA_REL_ "GenSigSuprvResp" BU_SG_REL_ CGM_HS SG_ 501 AutoTransComndGear 1;
BA_REL_ "GenSigRxStartValue" BU_SG_REL_ RDCM_HS SG_ 501 AutoTransComndGear "$F-Park Gear";
BA_REL_ "GenSigTimeoutTime" BU_SG_REL_ ECM_HS SG_ 501 AutoTransComndGear 62;
BA_REL_ "GenSigTimeoutMsg" BU_SG_REL_ ECM_HS SG_ 501 AutoTransComndGear 501;
BA_REL_ "GenSigSuprvResp" BU_SG_REL_ ECM_HS SG_ 501 AutoTransComndGear 1;
BA_REL_ "GenSigTimeoutTime" BU_SG_REL_ EBCM_HS SG_ 501 AutoTransComndGear 250;
BA_REL_ "GenSigTimeoutMsg" BU_SG_REL_ EBCM_HS SG_ 501 AutoTransComndGear 501;
BA_REL_ "GenSigSuprvResp" BU_SG_REL_ EBCM_HS SG_ 501 AutoTransComndGear 1;
BA_REL_ "GenSigTimeoutTime" BU_SG_REL_ BCM_HS SG_ 501 AutoTransComndGear 250;
BA_REL_ "GenSigTimeoutMsg" BU_SG_REL_ BCM_HS SG_ 501 AutoTransComndGear 501;
BA_REL_ "GenSigSuprvResp" BU_SG_REL_ BCM_HS SG_ 501 AutoTransComndGear 1;
BA_REL_ "GenSigTimeoutTime" BU_SG_REL_ CGM_HS SG_ 501 TransEstGear 250;
BA_REL_ "GenSigTimeoutMsg" BU_SG_REL_ CGM_HS SG_ 501 TransEstGear 501;
BA_REL_ "GenSigSuprvResp" BU_SG_REL_ CGM_HS SG_ 501 TransEstGear 1;
BA_REL_ "GenSigTimeoutTime" BU_SG_REL_ RDCM_HS SG_ 501 TransEstGear 250;
BA_REL_ "GenSigTimeoutMsg" BU_SG_REL_ RDCM_HS SG_ 501 TransEstGear 501;
BA_REL_ "GenSigRxStartValue" BU_SG_REL_ RDCM_HS SG_ 501 TransEstGear "$F-Park Gear";
BA_REL_ "GenSigSuprvResp" BU_SG_REL_ RDCM_HS SG_ 501 TransEstGear 1;
BA_REL_ "GenSigTimeoutTime" BU_SG_REL_ EBCM_HS SG_ 501 TransEstGear 250;
BA_REL_ "GenSigTimeoutMsg" BU_SG_REL_ EBCM_HS SG_ 501 TransEstGear 501;
BA_REL_ "GenSigRxStartValue" BU_SG_REL_ EBCM_HS SG_ 501 TransEstGear "1";
BA_REL_ "GenSigSuprvResp" BU_SG_REL_ EBCM_HS SG_ 501 TransEstGear 1;
BA_REL_ "GenSigTimeoutTime" BU_SG_REL_ BCM_HS SG_ 501 TransEstGear 250;
BA_REL_ "GenSigTimeoutMsg" BU_SG_REL_ BCM_HS SG_ 501 TransEstGear 501;
BA_REL_ "GenSigVBitResp" BU_SG_REL_ BCM_HS SG_ 501 TransEstGear 1;
BA_REL_ "GenSigSuprvResp" BU_SG_REL_ BCM_HS SG_ 501 TransEstGear 1;
BA_REL_ "GenSigTimeoutTime" BU_SG_REL_ ECM_HS SG_ 1225 TrnsEmisRlFrzFrmStrSt 1250;
BA_REL_ "GenSigTimeoutMsg" BU_SG_REL_ ECM_HS SG_ 1225 TrnsEmisRlFrzFrmStrSt 1225;
BA_REL_ "GenSigSuprvResp" BU_SG_REL_ ECM_HS SG_ 1225 TrnsEmisRlFrzFrmStrSt 1;
BA_REL_ "GenSigTimeoutTime" BU_SG_REL_ BCM_HS SG_ 1225 TCTPIR_TnsEsClCDwT 1250;
BA_REL_ "GenSigTimeoutMsg" BU_SG_REL_ BCM_HS SG_ 1225 TCTPIR_TnsEsClCDwT 1225;
BA_REL_ "GenSigSuprvResp" BU_SG_REL_ BCM_HS SG_ 1225 TCTPIR_TnsEsClCDwT 1;
BA_REL_ "GenSigTimeoutTime" BU_SG_REL_ BCM_HS SG_ 1225 TCTPIR_TnsEsClTmpD 1250;
BA_REL_ "GenSigTimeoutMsg" BU_SG_REL_ BCM_HS SG_ 1225 TCTPIR_TnsEsClTmpD 1225;
BA_REL_ "GenSigSuprvResp" BU_SG_REL_ BCM_HS SG_ 1225 TCTPIR_TnsEsClTmpD 1;
BA_REL_ "GenSigTimeoutTime" BU_SG_REL_ BCM_HS SG_ 1225 TCTPIR_DrvNotfn 1250;
BA_REL_ "GenSigTimeoutMsg" BU_SG_REL_ BCM_HS SG_ 1225 TCTPIR_DrvNotfn 1225;
BA_REL_ "GenSigSuprvResp" BU_SG_REL_ BCM_HS SG_ 1225 TCTPIR_DrvNotfn 1;
BA_REL_ "GenSigTimeoutTime" BU_SG_REL_ BCM_HS SG_ 1225 GrdBrkgAct 1250;
BA_REL_ "GenSigTimeoutMsg" BU_SG_REL_ BCM_HS SG_ 1225 GrdBrkgAct 1225;
BA_REL_ "GenSigSuprvResp" BU_SG_REL_ BCM_HS SG_ 1225 GrdBrkgAct 1;
BA_REL_ "GenSigTimeoutTime" BU_SG_REL_ BSM_HS SG_ 1225 TrnOilTmp 1250;
BA_REL_ "GenSigTimeoutMsg" BU_SG_REL_ BSM_HS SG_ 1225 TrnOilTmp 1225;
BA_REL_ "GenSigSuprvResp" BU_SG_REL_ BSM_HS SG_ 1225 TrnOilTmp 1;
BA_REL_ "GenSigTimeoutTime" BU_SG_REL_ BCM_HS SG_ 1225 TrnOilTmp 1250;
BA_REL_ "GenSigTimeoutMsg" BU_SG_REL_ BCM_HS SG_ 1225 TrnOilTmp 1225;
BA_REL_ "GenSigVBitResp" BU_SG_REL_ BCM_HS SG_ 1225 TrnOilTmp 1;
BA_REL_ "GenSigSuprvResp" BU_SG_REL_ BCM_HS SG_ 1225 TrnOilTmp 1;
BA_REL_ "GenSigTimeoutTime" BU_SG_REL_ ECM_HS SG_ 413 TrnsRtoCntlSysFlt 62;
BA_REL_ "GenSigTimeoutMsg" BU_SG_REL_ ECM_HS SG_ 413 TrnsRtoCntlSysFlt 413;
BA_REL_ "GenSigSuprvResp" BU_SG_REL_ ECM_HS SG_ 413 TrnsRtoCntlSysFlt 1;
BA_REL_ "GenSigTimeoutTime" BU_SG_REL_ CGM_HS SG_ 413 TrnGrRat 250;
BA_REL_ "GenSigTimeoutMsg" BU_SG_REL_ CGM_HS SG_ 413 TrnGrRat 413;
BA_REL_ "GenSigSuprvResp" BU_SG_REL_ CGM_HS SG_ 413 TrnGrRat 1;
BA_REL_ "GenSigTimeoutTime" BU_SG_REL_ ECM_HS SG_ 413 TESR_EngSpdCntlRsp 62;
BA_REL_ "GenSigTimeoutMsg" BU_SG_REL_ ECM_HS SG_ 413 TESR_EngSpdCntlRsp 413;
BA_REL_ "GenSigSuprvResp" BU_SG_REL_ ECM_HS SG_ 413 TESR_EngSpdCntlRsp 1;
BA_REL_ "GenSigTimeoutTime" BU_SG_REL_ ECM_HS SG_ 413 TESR_EngSpdRqVal 62;
BA_REL_ "GenSigTimeoutMsg" BU_SG_REL_ ECM_HS SG_ 413 TESR_EngSpdRqVal 413;
BA_REL_ "GenSigSuprvResp" BU_SG_REL_ ECM_HS SG_ 413 TESR_EngSpdRqVal 1;
BA_REL_ "GenSigTimeoutTime" BU_SG_REL_ ECM_HS SG_ 413 TESR_EngSpdIntTyp 62;
BA_REL_ "GenSigTimeoutMsg" BU_SG_REL_ ECM_HS SG_ 413 TESR_EngSpdIntTyp 413;
BA_REL_ "GenSigSuprvResp" BU_SG_REL_ ECM_HS SG_ 413 TESR_EngSpdIntTyp 1;
BA_REL_ "GenSigTimeoutTime" BU_SG_REL_ ECM_HS SG_ 413 TrnsGrgShftAct 62;
BA_REL_ "GenSigTimeoutMsg" BU_SG_REL_ ECM_HS SG_ 413 TrnsGrgShftAct 413;
BA_REL_ "GenSigSuprvResp" BU_SG_REL_ ECM_HS SG_ 413 TrnsGrgShftAct 1;
BA_REL_ "GenSigTimeoutTime" BU_SG_REL_ EBCM_HS SG_ 413 TransNtrlCntrlMdStat 250;
BA_REL_ "GenSigTimeoutMsg" BU_SG_REL_ EBCM_HS SG_ 413 TransNtrlCntrlMdStat 413;
BA_REL_ "GenSigSuprvResp" BU_SG_REL_ EBCM_HS SG_ 413 TransNtrlCntrlMdStat 1;
BA_REL_ "GenSigTimeoutTime" BU_SG_REL_ CGM_HS SG_ 197 WRSLNDWhlDisTpRC 250;
BA_REL_ "GenSigTimeoutMsg" BU_SG_REL_ CGM_HS SG_ 197 WRSLNDWhlDisTpRC 197;
BA_REL_ "GenSigSuprvResp" BU_SG_REL_ CGM_HS SG_ 197 WRSLNDWhlDisTpRC 1;
BA_REL_ "GenSigTimeoutTime" BU_SG_REL_ RDCM_HS SG_ 197 WRSLNDWhlDisTpRC 250;
BA_REL_ "GenSigTimeoutMsg" BU_SG_REL_ RDCM_HS SG_ 197 WRSLNDWhlDisTpRC 197;
BA_REL_ "GenSigSuprvResp" BU_SG_REL_ RDCM_HS SG_ 197 WRSLNDWhlDisTpRC 1;
BA_REL_ "GenSigTimeoutTime" BU_SG_REL_ BCM_HS SG_ 197 WRSLNDWhlDisTpRC 250;
BA_REL_ "GenSigTimeoutMsg" BU_SG_REL_ BCM_HS SG_ 197 WRSLNDWhlDisTpRC 197;
BA_REL_ "GenSigSuprvResp" BU_SG_REL_ BCM_HS SG_ 197 WRSLNDWhlDisTpRC 1;
BA_REL_ "GenSigTimeoutTime" BU_SG_REL_ CGM_HS SG_ 197 WRSLNDWhlRotStRst 250;
BA_REL_ "GenSigTimeoutMsg" BU_SG_REL_ CGM_HS SG_ 197 WRSLNDWhlRotStRst 197;
BA_REL_ "GenSigSuprvResp" BU_SG_REL_ CGM_HS SG_ 197 WRSLNDWhlRotStRst 1;
BA_REL_ "GenSigTimeoutTime" BU_SG_REL_ RDCM_HS SG_ 197 WRSLNDWhlRotStRst 250;
BA_REL_ "GenSigTimeoutMsg" BU_SG_REL_ RDCM_HS SG_ 197 WRSLNDWhlRotStRst 197;
BA_REL_ "GenSigSuprvResp" BU_SG_REL_ RDCM_HS SG_ 197 WRSLNDWhlRotStRst 1;
BA_REL_ "GenSigTimeoutTime" BU_SG_REL_ BCM_HS SG_ 197 WRSLNDWhlRotStRst 250;
BA_REL_ "GenSigTimeoutMsg" BU_SG_REL_ BCM_HS SG_ 197 WRSLNDWhlRotStRst 197;
BA_REL_ "GenSigSuprvResp" BU_SG_REL_ BCM_HS SG_ 197 WRSLNDWhlRotStRst 1;
BA_REL_ "GenSigTimeoutTime" BU_SG_REL_ CGM_HS SG_ 197 WRSLNDWhlDistVal 250;
BA_REL_ "GenSigTimeoutMsg" BU_SG_REL_ CGM_HS SG_ 197 WRSLNDWhlDistVal 197;
BA_REL_ "GenSigSuprvResp" BU_SG_REL_ CGM_HS SG_ 197 WRSLNDWhlDistVal 1;
BA_REL_ "GenSigTimeoutTime" BU_SG_REL_ RDCM_HS SG_ 197 WRSLNDWhlDistVal 250;
BA_REL_ "GenSigTimeoutMsg" BU_SG_REL_ RDCM_HS SG_ 197 WRSLNDWhlDistVal 197;
BA_REL_ "GenSigSuprvResp" BU_SG_REL_ RDCM_HS SG_ 197 WRSLNDWhlDistVal 1;
BA_REL_ "GenSigTimeoutTime" BU_SG_REL_ BCM_HS SG_ 197 WRSLNDWhlDistVal 250;
BA_REL_ "GenSigTimeoutMsg" BU_SG_REL_ BCM_HS SG_ 197 WRSLNDWhlDistVal 197;
BA_REL_ "GenSigSuprvResp" BU_SG_REL_ BCM_HS SG_ 197 WRSLNDWhlDistVal 1;
BA_REL_ "GenSigTimeoutTime" BU_SG_REL_ CGM_HS SG_ 197 WRSLNDWhlDistTstm 250;
BA_REL_ "GenSigTimeoutMsg" BU_SG_REL_ CGM_HS SG_ 197 WRSLNDWhlDistTstm 197;
BA_REL_ "GenSigSuprvResp" BU_SG_REL_ CGM_HS SG_ 197 WRSLNDWhlDistTstm 1;
BA_REL_ "GenSigTimeoutTime" BU_SG_REL_ RDCM_HS SG_ 197 WRSLNDWhlDistTstm 250;
BA_REL_ "GenSigTimeoutMsg" BU_SG_REL_ RDCM_HS SG_ 197 WRSLNDWhlDistTstm 197;
BA_REL_ "GenSigSuprvResp" BU_SG_REL_ RDCM_HS SG_ 197 WRSLNDWhlDistTstm 1;
BA_REL_ "GenSigTimeoutTime" BU_SG_REL_ BCM_HS SG_ 197 WRSLNDWhlDistTstm 250;
BA_REL_ "GenSigTimeoutMsg" BU_SG_REL_ BCM_HS SG_ 197 WRSLNDWhlDistTstm 197;
BA_REL_ "GenSigSuprvResp" BU_SG_REL_ BCM_HS SG_ 197 WRSLNDWhlDistTstm 1;
BA_REL_ "GenSigTimeoutTime" BU_SG_REL_ CGM_HS SG_ 197 WRSLNDWhlDistPCntr 250;
BA_REL_ "GenSigTimeoutMsg" BU_SG_REL_ CGM_HS SG_ 197 WRSLNDWhlDistPCntr 197;
BA_REL_ "GenSigSuprvResp" BU_SG_REL_ CGM_HS SG_ 197 WRSLNDWhlDistPCntr 1;
BA_REL_ "GenSigTimeoutTime" BU_SG_REL_ RDCM_HS SG_ 197 WRSLNDWhlDistPCntr 250;
BA_REL_ "GenSigTimeoutMsg" BU_SG_REL_ RDCM_HS SG_ 197 WRSLNDWhlDistPCntr 197;
BA_REL_ "GenSigSuprvResp" BU_SG_REL_ RDCM_HS SG_ 197 WRSLNDWhlDistPCntr 1;
BA_REL_ "GenSigTimeoutTime" BU_SG_REL_ BCM_HS SG_ 197 WRSLNDWhlDistPCntr 250;
BA_REL_ "GenSigTimeoutMsg" BU_SG_REL_ BCM_HS SG_ 197 WRSLNDWhlDistPCntr 197;
BA_REL_ "GenSigSuprvResp" BU_SG_REL_ BCM_HS SG_ 197 WRSLNDWhlDistPCntr 1;
BA_REL_ "GenSigTimeoutTime" BU_SG_REL_ CGM_HS SG_ 197 WRSLNDSeqNum 250;
BA_REL_ "GenSigTimeoutMsg" BU_SG_REL_ CGM_HS SG_ 197 WRSLNDSeqNum 197;
BA_REL_ "GenSigSuprvResp" BU_SG_REL_ CGM_HS SG_ 197 WRSLNDSeqNum 1;
BA_REL_ "GenSigTimeoutTime" BU_SG_REL_ RDCM_HS SG_ 197 WRSLNDSeqNum 250;
BA_REL_ "GenSigTimeoutMsg" BU_SG_REL_ RDCM_HS SG_ 197 WRSLNDSeqNum 197;
BA_REL_ "GenSigSuprvResp" BU_SG_REL_ RDCM_HS SG_ 197 WRSLNDSeqNum 1;
BA_REL_ "GenSigTimeoutTime" BU_SG_REL_ BCM_HS SG_ 197 WRSLNDSeqNum 250;
BA_REL_ "GenSigTimeoutMsg" BU_SG_REL_ BCM_HS SG_ 197 WRSLNDSeqNum 197;
BA_REL_ "GenSigSuprvResp" BU_SG_REL_ BCM_HS SG_ 197 WRSLNDSeqNum 1;
BA_REL_ "GenSigTimeoutTime" BU_SG_REL_ CGM_HS SG_ 197 WRSRNDWhlDisTpRC 250;
BA_REL_ "GenSigTimeoutMsg" BU_SG_REL_ CGM_HS SG_ 197 WRSRNDWhlDisTpRC 197;
BA_REL_ "GenSigSuprvResp" BU_SG_REL_ CGM_HS SG_ 197 WRSRNDWhlDisTpRC 1;
BA_REL_ "GenSigTimeoutTime" BU_SG_REL_ RDCM_HS SG_ 197 WRSRNDWhlDisTpRC 250;
BA_REL_ "GenSigTimeoutMsg" BU_SG_REL_ RDCM_HS SG_ 197 WRSRNDWhlDisTpRC 197;
BA_REL_ "GenSigSuprvResp" BU_SG_REL_ RDCM_HS SG_ 197 WRSRNDWhlDisTpRC 1;
BA_REL_ "GenSigTimeoutTime" BU_SG_REL_ BCM_HS SG_ 197 WRSRNDWhlDisTpRC 250;
BA_REL_ "GenSigTimeoutMsg" BU_SG_REL_ BCM_HS SG_ 197 WRSRNDWhlDisTpRC 197;
BA_REL_ "GenSigSuprvResp" BU_SG_REL_ BCM_HS SG_ 197 WRSRNDWhlDisTpRC 1;
BA_REL_ "GenSigTimeoutTime" BU_SG_REL_ CGM_HS SG_ 197 WRSRNDWhlRotStRst 250;
BA_REL_ "GenSigTimeoutMsg" BU_SG_REL_ CGM_HS SG_ 197 WRSRNDWhlRotStRst 197;
BA_REL_ "GenSigSuprvResp" BU_SG_REL_ CGM_HS SG_ 197 WRSRNDWhlRotStRst 1;
BA_REL_ "GenSigTimeoutTime" BU_SG_REL_ RDCM_HS SG_ 197 WRSRNDWhlRotStRst 250;
BA_REL_ "GenSigTimeoutMsg" BU_SG_REL_ RDCM_HS SG_ 197 WRSRNDWhlRotStRst 197;
BA_REL_ "GenSigSuprvResp" BU_SG_REL_ RDCM_HS SG_ 197 WRSRNDWhlRotStRst 1;
BA_REL_ "GenSigTimeoutTime" BU_SG_REL_ BCM_HS SG_ 197 WRSRNDWhlRotStRst 250;
BA_REL_ "GenSigTimeoutMsg" BU_SG_REL_ BCM_HS SG_ 197 WRSRNDWhlRotStRst 197;
BA_REL_ "GenSigSuprvResp" BU_SG_REL_ BCM_HS SG_ 197 WRSRNDWhlRotStRst 1;
BA_REL_ "GenSigTimeoutTime" BU_SG_REL_ CGM_HS SG_ 197 WRSRNDWhlDistVal 250;
BA_REL_ "GenSigTimeoutMsg" BU_SG_REL_ CGM_HS SG_ 197 WRSRNDWhlDistVal 197;
BA_REL_ "GenSigSuprvResp" BU_SG_REL_ CGM_HS SG_ 197 WRSRNDWhlDistVal 1;
BA_REL_ "GenSigTimeoutTime" BU_SG_REL_ RDCM_HS SG_ 197 WRSRNDWhlDistVal 250;
BA_REL_ "GenSigTimeoutMsg" BU_SG_REL_ RDCM_HS SG_ 197 WRSRNDWhlDistVal 197;
BA_REL_ "GenSigSuprvResp" BU_SG_REL_ RDCM_HS SG_ 197 WRSRNDWhlDistVal 1;
BA_REL_ "GenSigTimeoutTime" BU_SG_REL_ BCM_HS SG_ 197 WRSRNDWhlDistVal 250;
BA_REL_ "GenSigTimeoutMsg" BU_SG_REL_ BCM_HS SG_ 197 WRSRNDWhlDistVal 197;
BA_REL_ "GenSigSuprvResp" BU_SG_REL_ BCM_HS SG_ 197 WRSRNDWhlDistVal 1;
BA_REL_ "GenSigTimeoutTime" BU_SG_REL_ CGM_HS SG_ 197 WRSRNDWhlDistTstm 250;
BA_REL_ "GenSigTimeoutMsg" BU_SG_REL_ CGM_HS SG_ 197 WRSRNDWhlDistTstm 197;
BA_REL_ "GenSigSuprvResp" BU_SG_REL_ CGM_HS SG_ 197 WRSRNDWhlDistTstm 1;
BA_REL_ "GenSigTimeoutTime" BU_SG_REL_ RDCM_HS SG_ 197 WRSRNDWhlDistTstm 250;
BA_REL_ "GenSigTimeoutMsg" BU_SG_REL_ RDCM_HS SG_ 197 WRSRNDWhlDistTstm 197;
BA_REL_ "GenSigSuprvResp" BU_SG_REL_ RDCM_HS SG_ 197 WRSRNDWhlDistTstm 1;
BA_REL_ "GenSigTimeoutTime" BU_SG_REL_ BCM_HS SG_ 197 WRSRNDWhlDistTstm 250;
BA_REL_ "GenSigTimeoutMsg" BU_SG_REL_ BCM_HS SG_ 197 WRSRNDWhlDistTstm 197;
BA_REL_ "GenSigSuprvResp" BU_SG_REL_ BCM_HS SG_ 197 WRSRNDWhlDistTstm 1;
BA_REL_ "GenSigTimeoutTime" BU_SG_REL_ CGM_HS SG_ 197 WRSRNDWhlDistPCntr 250;
BA_REL_ "GenSigTimeoutMsg" BU_SG_REL_ CGM_HS SG_ 197 WRSRNDWhlDistPCntr 197;
BA_REL_ "GenSigSuprvResp" BU_SG_REL_ CGM_HS SG_ 197 WRSRNDWhlDistPCntr 1;
BA_REL_ "GenSigTimeoutTime" BU_SG_REL_ RDCM_HS SG_ 197 WRSRNDWhlDistPCntr 250;
BA_REL_ "GenSigTimeoutMsg" BU_SG_REL_ RDCM_HS SG_ 197 WRSRNDWhlDistPCntr 197;
BA_REL_ "GenSigSuprvResp" BU_SG_REL_ RDCM_HS SG_ 197 WRSRNDWhlDistPCntr 1;
BA_REL_ "GenSigTimeoutTime" BU_SG_REL_ BCM_HS SG_ 197 WRSRNDWhlDistPCntr 250;
BA_REL_ "GenSigTimeoutMsg" BU_SG_REL_ BCM_HS SG_ 197 WRSRNDWhlDistPCntr 197;
BA_REL_ "GenSigSuprvResp" BU_SG_REL_ BCM_HS SG_ 197 WRSRNDWhlDistPCntr 1;
BA_REL_ "GenSigTimeoutTime" BU_SG_REL_ CGM_HS SG_ 197 WRSRNDSeqNum 250;
BA_REL_ "GenSigTimeoutMsg" BU_SG_REL_ CGM_HS SG_ 197 WRSRNDSeqNum 197;
BA_REL_ "GenSigSuprvResp" BU_SG_REL_ CGM_HS SG_ 197 WRSRNDSeqNum 1;
BA_REL_ "GenSigTimeoutTime" BU_SG_REL_ RDCM_HS SG_ 197 WRSRNDSeqNum 250;
BA_REL_ "GenSigTimeoutMsg" BU_SG_REL_ RDCM_HS SG_ 197 WRSRNDSeqNum 197;
BA_REL_ "GenSigSuprvResp" BU_SG_REL_ RDCM_HS SG_ 197 WRSRNDSeqNum 1;
BA_REL_ "GenSigTimeoutTime" BU_SG_REL_ BCM_HS SG_ 197 WRSRNDSeqNum 250;
BA_REL_ "GenSigTimeoutMsg" BU_SG_REL_ BCM_HS SG_ 197 WRSRNDSeqNum 197;
BA_REL_ "GenSigSuprvResp" BU_SG_REL_ BCM_HS SG_ 197 WRSRNDSeqNum 1;
BA_REL_ "GenSigTimeoutTime" BU_SG_REL_ CGM_HS SG_ 840 WhlRotDrctnlStLftDrvn 250;
BA_REL_ "GenSigTimeoutMsg" BU_SG_REL_ CGM_HS SG_ 840 WhlRotDrctnlStLftDrvn 840;
BA_REL_ "GenSigSuprvResp" BU_SG_REL_ CGM_HS SG_ 840 WhlRotDrctnlStLftDrvn 1;
BA_REL_ "GenSigTimeoutTime" BU_SG_REL_ EPS_HS SG_ 840 WhlRotDrctnlStLftDrvn 250;
BA_REL_ "GenSigTimeoutMsg" BU_SG_REL_ EPS_HS SG_ 840 WhlRotDrctnlStLftDrvn 840;
BA_REL_ "GenSigSuprvResp" BU_SG_REL_ EPS_HS SG_ 840 WhlRotDrctnlStLftDrvn 1;
BA_REL_ "GenSigTimeoutTime" BU_SG_REL_ CGM_HS SG_ 840 WhlRotDrctnlStRtDrvn 250;
BA_REL_ "GenSigTimeoutMsg" BU_SG_REL_ CGM_HS SG_ 840 WhlRotDrctnlStRtDrvn 840;
BA_REL_ "GenSigSuprvResp" BU_SG_REL_ CGM_HS SG_ 840 WhlRotDrctnlStRtDrvn 1;
BA_REL_ "GenSigTimeoutTime" BU_SG_REL_ EPS_HS SG_ 840 WhlRotDrctnlStRtDrvn 250;
BA_REL_ "GenSigTimeoutMsg" BU_SG_REL_ EPS_HS SG_ 840 WhlRotDrctnlStRtDrvn 840;
BA_REL_ "GenSigSuprvResp" BU_SG_REL_ EPS_HS SG_ 840 WhlRotDrctnlStRtDrvn 1;
BA_REL_ "GenSigTimeoutTime" BU_SG_REL_ CGM_HS SG_ 840 WhlGrndVlctyRtDrvn 250;
BA_REL_ "GenSigTimeoutMsg" BU_SG_REL_ CGM_HS SG_ 840 WhlGrndVlctyRtDrvn 840;
BA_REL_ "GenSigSuprvResp" BU_SG_REL_ CGM_HS SG_ 840 WhlGrndVlctyRtDrvn 1;
BA_REL_ "GenSigTimeoutTime" BU_SG_REL_ EPS_HS SG_ 840 WhlGrndVlctyRtDrvn 250;
BA_REL_ "GenSigTimeoutMsg" BU_SG_REL_ EPS_HS SG_ 840 WhlGrndVlctyRtDrvn 840;
BA_REL_ "GenSigSuprvResp" BU_SG_REL_ EPS_HS SG_ 840 WhlGrndVlctyRtDrvn 1;
BA_REL_ "GenSigTimeoutTime" BU_SG_REL_ BCM_HS SG_ 840 WhlGrndVlctyRtDrvn 250;
BA_REL_ "GenSigTimeoutMsg" BU_SG_REL_ BCM_HS SG_ 840 WhlGrndVlctyRtDrvn 840;
BA_REL_ "GenSigVBitResp" BU_SG_REL_ BCM_HS SG_ 840 WhlGrndVlctyRtDrvn 1;
BA_REL_ "GenSigSuprvResp" BU_SG_REL_ BCM_HS SG_ 840 WhlGrndVlctyRtDrvn 1;
BA_REL_ "GenSigTimeoutTime" BU_SG_REL_ CGM_HS SG_ 840 WhlGrndVlctyLftDrvn 250;
BA_REL_ "GenSigTimeoutMsg" BU_SG_REL_ CGM_HS SG_ 840 WhlGrndVlctyLftDrvn 840;
BA_REL_ "GenSigSuprvResp" BU_SG_REL_ CGM_HS SG_ 840 WhlGrndVlctyLftDrvn 1;
BA_REL_ "GenSigTimeoutTime" BU_SG_REL_ RDCM_HS SG_ 840 WhlGrndVlctyLftDrvn 250;
BA_REL_ "GenSigTimeoutMsg" BU_SG_REL_ RDCM_HS SG_ 840 WhlGrndVlctyLftDrvn 840;
BA_REL_ "GenSigVBitResp" BU_SG_REL_ RDCM_HS SG_ 840 WhlGrndVlctyLftDrvn 1;
BA_REL_ "GenSigSuprvResp" BU_SG_REL_ RDCM_HS SG_ 840 WhlGrndVlctyLftDrvn 1;
BA_REL_ "GenSigTimeoutTime" BU_SG_REL_ BCM_HS SG_ 840 WhlGrndVlctyLftDrvn 250;
BA_REL_ "GenSigTimeoutMsg" BU_SG_REL_ BCM_HS SG_ 840 WhlGrndVlctyLftDrvn 840;
BA_REL_ "GenSigVBitResp" BU_SG_REL_ BCM_HS SG_ 840 WhlGrndVlctyLftDrvn 1;
BA_REL_ "GenSigSuprvResp" BU_SG_REL_ BCM_HS SG_ 840 WhlGrndVlctyLftDrvn 1;
BA_REL_ "GenSigTimeoutTime" BU_SG_REL_ CGM_HS SG_ 193 WRSLDWhlDisTpRC 250;
BA_REL_ "GenSigTimeoutMsg" BU_SG_REL_ CGM_HS SG_ 193 WRSLDWhlDisTpRC 193;
BA_REL_ "GenSigSuprvResp" BU_SG_REL_ CGM_HS SG_ 193 WRSLDWhlDisTpRC 1;
BA_REL_ "GenSigTimeoutTime" BU_SG_REL_ RDCM_HS SG_ 193 WRSLDWhlDisTpRC 250;
BA_REL_ "GenSigTimeoutMsg" BU_SG_REL_ RDCM_HS SG_ 193 WRSLDWhlDisTpRC 193;
BA_REL_ "GenSigSuprvResp" BU_SG_REL_ RDCM_HS SG_ 193 WRSLDWhlDisTpRC 1;
BA_REL_ "GenSigTimeoutTime" BU_SG_REL_ BCM_HS SG_ 193 WRSLDWhlDisTpRC 250;
BA_REL_ "GenSigTimeoutMsg" BU_SG_REL_ BCM_HS SG_ 193 WRSLDWhlDisTpRC 193;
BA_REL_ "GenSigSuprvResp" BU_SG_REL_ BCM_HS SG_ 193 WRSLDWhlDisTpRC 1;
BA_REL_ "GenSigTimeoutTime" BU_SG_REL_ CGM_HS SG_ 193 WRSLDSeqNum 250;
BA_REL_ "GenSigTimeoutMsg" BU_SG_REL_ CGM_HS SG_ 193 WRSLDSeqNum 193;
BA_REL_ "GenSigSuprvResp" BU_SG_REL_ CGM_HS SG_ 193 WRSLDSeqNum 1;
BA_REL_ "GenSigTimeoutTime" BU_SG_REL_ RDCM_HS SG_ 193 WRSLDSeqNum 250;
BA_REL_ "GenSigTimeoutMsg" BU_SG_REL_ RDCM_HS SG_ 193 WRSLDSeqNum 193;
BA_REL_ "GenSigSuprvResp" BU_SG_REL_ RDCM_HS SG_ 193 WRSLDSeqNum 1;
BA_REL_ "GenSigTimeoutTime" BU_SG_REL_ BCM_HS SG_ 193 WRSLDSeqNum 250;
BA_REL_ "GenSigTimeoutMsg" BU_SG_REL_ BCM_HS SG_ 193 WRSLDSeqNum 193;
BA_REL_ "GenSigSuprvResp" BU_SG_REL_ BCM_HS SG_ 193 WRSLDSeqNum 1;
BA_REL_ "GenSigTimeoutTime" BU_SG_REL_ CGM_HS SG_ 193 WRSLDWhlDistVal 250;
BA_REL_ "GenSigTimeoutMsg" BU_SG_REL_ CGM_HS SG_ 193 WRSLDWhlDistVal 193;
BA_REL_ "GenSigSuprvResp" BU_SG_REL_ CGM_HS SG_ 193 WRSLDWhlDistVal 1;
BA_REL_ "GenSigTimeoutTime" BU_SG_REL_ RDCM_HS SG_ 193 WRSLDWhlDistVal 250;
BA_REL_ "GenSigTimeoutMsg" BU_SG_REL_ RDCM_HS SG_ 193 WRSLDWhlDistVal 193;
BA_REL_ "GenSigSuprvResp" BU_SG_REL_ RDCM_HS SG_ 193 WRSLDWhlDistVal 1;
BA_REL_ "GenSigTimeoutTime" BU_SG_REL_ BCM_HS SG_ 193 WRSLDWhlDistVal 250;
BA_REL_ "GenSigTimeoutMsg" BU_SG_REL_ BCM_HS SG_ 193 WRSLDWhlDistVal 193;
BA_REL_ "GenSigSuprvResp" BU_SG_REL_ BCM_HS SG_ 193 WRSLDWhlDistVal 1;
BA_REL_ "GenSigTimeoutTime" BU_SG_REL_ CGM_HS SG_ 193 WRSLDWhlRotStatRst 250;
BA_REL_ "GenSigTimeoutMsg" BU_SG_REL_ CGM_HS SG_ 193 WRSLDWhlRotStatRst 193;
BA_REL_ "GenSigSuprvResp" BU_SG_REL_ CGM_HS SG_ 193 WRSLDWhlRotStatRst 1;
BA_REL_ "GenSigTimeoutTime" BU_SG_REL_ RDCM_HS SG_ 193 WRSLDWhlRotStatRst 250;
BA_REL_ "GenSigTimeoutMsg" BU_SG_REL_ RDCM_HS SG_ 193 WRSLDWhlRotStatRst 193;
BA_REL_ "GenSigSuprvResp" BU_SG_REL_ RDCM_HS SG_ 193 WRSLDWhlRotStatRst 1;
BA_REL_ "GenSigTimeoutTime" BU_SG_REL_ BCM_HS SG_ 193 WRSLDWhlRotStatRst 250;
BA_REL_ "GenSigTimeoutMsg" BU_SG_REL_ BCM_HS SG_ 193 WRSLDWhlRotStatRst 193;
BA_REL_ "GenSigSuprvResp" BU_SG_REL_ BCM_HS SG_ 193 WRSLDWhlRotStatRst 1;
BA_REL_ "GenSigTimeoutTime" BU_SG_REL_ CGM_HS SG_ 193 WRSLDWhlDistTmstm 250;
BA_REL_ "GenSigTimeoutMsg" BU_SG_REL_ CGM_HS SG_ 193 WRSLDWhlDistTmstm 193;
BA_REL_ "GenSigSuprvResp" BU_SG_REL_ CGM_HS SG_ 193 WRSLDWhlDistTmstm 1;
BA_REL_ "GenSigTimeoutTime" BU_SG_REL_ RDCM_HS SG_ 193 WRSLDWhlDistTmstm 250;
BA_REL_ "GenSigTimeoutMsg" BU_SG_REL_ RDCM_HS SG_ 193 WRSLDWhlDistTmstm 193;
BA_REL_ "GenSigSuprvResp" BU_SG_REL_ RDCM_HS SG_ 193 WRSLDWhlDistTmstm 1;
BA_REL_ "GenSigTimeoutTime" BU_SG_REL_ BCM_HS SG_ 193 WRSLDWhlDistTmstm 250;
BA_REL_ "GenSigTimeoutMsg" BU_SG_REL_ BCM_HS SG_ 193 WRSLDWhlDistTmstm 193;
BA_REL_ "GenSigSuprvResp" BU_SG_REL_ BCM_HS SG_ 193 WRSLDWhlDistTmstm 1;
BA_REL_ "GenSigTimeoutTime" BU_SG_REL_ CGM_HS SG_ 193 WRSLDWhlDistPlsCntr 250;
BA_REL_ "GenSigTimeoutMsg" BU_SG_REL_ CGM_HS SG_ 193 WRSLDWhlDistPlsCntr 193;
BA_REL_ "GenSigSuprvResp" BU_SG_REL_ CGM_HS SG_ 193 WRSLDWhlDistPlsCntr 1;
BA_REL_ "GenSigTimeoutTime" BU_SG_REL_ RDCM_HS SG_ 193 WRSLDWhlDistPlsCntr 250;
BA_REL_ "GenSigTimeoutMsg" BU_SG_REL_ RDCM_HS SG_ 193 WRSLDWhlDistPlsCntr 193;
BA_REL_ "GenSigSuprvResp" BU_SG_REL_ RDCM_HS SG_ 193 WRSLDWhlDistPlsCntr 1;
BA_REL_ "GenSigTimeoutTime" BU_SG_REL_ BCM_HS SG_ 193 WRSLDWhlDistPlsCntr 250;
BA_REL_ "GenSigTimeoutMsg" BU_SG_REL_ BCM_HS SG_ 193 WRSLDWhlDistPlsCntr 193;
BA_REL_ "GenSigSuprvResp" BU_SG_REL_ BCM_HS SG_ 193 WRSLDWhlDistPlsCntr 1;
BA_REL_ "GenSigTimeoutTime" BU_SG_REL_ CGM_HS SG_ 193 WRSRDWhlDisTpRC 250;
BA_REL_ "GenSigTimeoutMsg" BU_SG_REL_ CGM_HS SG_ 193 WRSRDWhlDisTpRC 193;
BA_REL_ "GenSigSuprvResp" BU_SG_REL_ CGM_HS SG_ 193 WRSRDWhlDisTpRC 1;
BA_REL_ "GenSigTimeoutTime" BU_SG_REL_ RDCM_HS SG_ 193 WRSRDWhlDisTpRC 250;
BA_REL_ "GenSigTimeoutMsg" BU_SG_REL_ RDCM_HS SG_ 193 WRSRDWhlDisTpRC 193;
BA_REL_ "GenSigSuprvResp" BU_SG_REL_ RDCM_HS SG_ 193 WRSRDWhlDisTpRC 1;
BA_REL_ "GenSigTimeoutTime" BU_SG_REL_ BCM_HS SG_ 193 WRSRDWhlDisTpRC 250;
BA_REL_ "GenSigTimeoutMsg" BU_SG_REL_ BCM_HS SG_ 193 WRSRDWhlDisTpRC 193;
BA_REL_ "GenSigSuprvResp" BU_SG_REL_ BCM_HS SG_ 193 WRSRDWhlDisTpRC 1;
BA_REL_ "GenSigTimeoutTime" BU_SG_REL_ CGM_HS SG_ 193 WRSRDSeqNum 250;
BA_REL_ "GenSigTimeoutMsg" BU_SG_REL_ CGM_HS SG_ 193 WRSRDSeqNum 193;
BA_REL_ "GenSigSuprvResp" BU_SG_REL_ CGM_HS SG_ 193 WRSRDSeqNum 1;
BA_REL_ "GenSigTimeoutTime" BU_SG_REL_ RDCM_HS SG_ 193 WRSRDSeqNum 250;
BA_REL_ "GenSigTimeoutMsg" BU_SG_REL_ RDCM_HS SG_ 193 WRSRDSeqNum 193;
BA_REL_ "GenSigSuprvResp" BU_SG_REL_ RDCM_HS SG_ 193 WRSRDSeqNum 1;
BA_REL_ "GenSigTimeoutTime" BU_SG_REL_ BCM_HS SG_ 193 WRSRDSeqNum 250;
BA_REL_ "GenSigTimeoutMsg" BU_SG_REL_ BCM_HS SG_ 193 WRSRDSeqNum 193;
BA_REL_ "GenSigSuprvResp" BU_SG_REL_ BCM_HS SG_ 193 WRSRDSeqNum 1;
BA_REL_ "GenSigTimeoutTime" BU_SG_REL_ CGM_HS SG_ 193 WRSRDWhlRotStatRst 250;
BA_REL_ "GenSigTimeoutMsg" BU_SG_REL_ CGM_HS SG_ 193 WRSRDWhlRotStatRst 193;
BA_REL_ "GenSigSuprvResp" BU_SG_REL_ CGM_HS SG_ 193 WRSRDWhlRotStatRst 1;
BA_REL_ "GenSigTimeoutTime" BU_SG_REL_ RDCM_HS SG_ 193 WRSRDWhlRotStatRst 250;
BA_REL_ "GenSigTimeoutMsg" BU_SG_REL_ RDCM_HS SG_ 193 WRSRDWhlRotStatRst 193;
BA_REL_ "GenSigSuprvResp" BU_SG_REL_ RDCM_HS SG_ 193 WRSRDWhlRotStatRst 1;
BA_REL_ "GenSigTimeoutTime" BU_SG_REL_ BCM_HS SG_ 193 WRSRDWhlRotStatRst 250;
BA_REL_ "GenSigTimeoutMsg" BU_SG_REL_ BCM_HS SG_ 193 WRSRDWhlRotStatRst 193;
BA_REL_ "GenSigSuprvResp" BU_SG_REL_ BCM_HS SG_ 193 WRSRDWhlRotStatRst 1;
BA_REL_ "GenSigTimeoutTime" BU_SG_REL_ CGM_HS SG_ 193 WRSRDWhlDistVal 250;
BA_REL_ "GenSigTimeoutMsg" BU_SG_REL_ CGM_HS SG_ 193 WRSRDWhlDistVal 193;
BA_REL_ "GenSigSuprvResp" BU_SG_REL_ CGM_HS SG_ 193 WRSRDWhlDistVal 1;
BA_REL_ "GenSigTimeoutTime" BU_SG_REL_ RDCM_HS SG_ 193 WRSRDWhlDistVal 250;
BA_REL_ "GenSigTimeoutMsg" BU_SG_REL_ RDCM_HS SG_ 193 WRSRDWhlDistVal 193;
BA_REL_ "GenSigSuprvResp" BU_SG_REL_ RDCM_HS SG_ 193 WRSRDWhlDistVal 1;
BA_REL_ "GenSigTimeoutTime" BU_SG_REL_ BCM_HS SG_ 193 WRSRDWhlDistVal 250;
BA_REL_ "GenSigTimeoutMsg" BU_SG_REL_ BCM_HS SG_ 193 WRSRDWhlDistVal 193;
BA_REL_ "GenSigSuprvResp" BU_SG_REL_ BCM_HS SG_ 193 WRSRDWhlDistVal 1;
BA_REL_ "GenSigTimeoutTime" BU_SG_REL_ CGM_HS SG_ 193 WRSRDWhlDistTmstm 250;
BA_REL_ "GenSigTimeoutMsg" BU_SG_REL_ CGM_HS SG_ 193 WRSRDWhlDistTmstm 193;
BA_REL_ "GenSigSuprvResp" BU_SG_REL_ CGM_HS SG_ 193 WRSRDWhlDistTmstm 1;
BA_REL_ "GenSigTimeoutTime" BU_SG_REL_ RDCM_HS SG_ 193 WRSRDWhlDistTmstm 250;
BA_REL_ "GenSigTimeoutMsg" BU_SG_REL_ RDCM_HS SG_ 193 WRSRDWhlDistTmstm 193;
BA_REL_ "GenSigSuprvResp" BU_SG_REL_ RDCM_HS SG_ 193 WRSRDWhlDistTmstm 1;
BA_REL_ "GenSigTimeoutTime" BU_SG_REL_ BCM_HS SG_ 193 WRSRDWhlDistTmstm 250;
BA_REL_ "GenSigTimeoutMsg" BU_SG_REL_ BCM_HS SG_ 193 WRSRDWhlDistTmstm 193;
BA_REL_ "GenSigSuprvResp" BU_SG_REL_ BCM_HS SG_ 193 WRSRDWhlDistTmstm 1;
BA_REL_ "GenSigTimeoutTime" BU_SG_REL_ CGM_HS SG_ 193 WRSRDWhlDistPlsCntr 250;
BA_REL_ "GenSigTimeoutMsg" BU_SG_REL_ CGM_HS SG_ 193 WRSRDWhlDistPlsCntr 193;
BA_REL_ "GenSigSuprvResp" BU_SG_REL_ CGM_HS SG_ 193 WRSRDWhlDistPlsCntr 1;
BA_REL_ "GenSigTimeoutTime" BU_SG_REL_ RDCM_HS SG_ 193 WRSRDWhlDistPlsCntr 250;
BA_REL_ "GenSigTimeoutMsg" BU_SG_REL_ RDCM_HS SG_ 193 WRSRDWhlDistPlsCntr 193;
BA_REL_ "GenSigSuprvResp" BU_SG_REL_ RDCM_HS SG_ 193 WRSRDWhlDistPlsCntr 1;
BA_REL_ "GenSigTimeoutTime" BU_SG_REL_ BCM_HS SG_ 193 WRSRDWhlDistPlsCntr 250;
BA_REL_ "GenSigTimeoutMsg" BU_SG_REL_ BCM_HS SG_ 193 WRSRDWhlDistPlsCntr 193;
BA_REL_ "GenSigSuprvResp" BU_SG_REL_ BCM_HS SG_ 193 WRSRDWhlDistPlsCntr 1;
BA_REL_ "GenSigTimeoutTime" BU_SG_REL_ CGM_HS SG_ 761 BrkSysHRBkCtrlAvail 250;
BA_REL_ "GenSigTimeoutMsg" BU_SG_REL_ CGM_HS SG_ 761 BrkSysHRBkCtrlAvail 761;
BA_REL_ "GenSigSuprvResp" BU_SG_REL_ CGM_HS SG_ 761 BrkSysHRBkCtrlAvail 1;
BA_REL_ "GenSigTimeoutTime" BU_SG_REL_ TCM_HS SG_ 761 BrkSysHRBkCtrlAvail 250;
BA_REL_ "GenSigTimeoutMsg" BU_SG_REL_ TCM_HS SG_ 761 BrkSysHRBkCtrlAvail 761;
BA_REL_ "GenSigSuprvResp" BU_SG_REL_ TCM_HS SG_ 761 BrkSysHRBkCtrlAvail 1;
BA_REL_ "GenSigTimeoutTime" BU_SG_REL_ CGM_HS SG_ 761 BrkSysHRBkCtrlStat 250;
BA_REL_ "GenSigTimeoutMsg" BU_SG_REL_ CGM_HS SG_ 761 BrkSysHRBkCtrlStat 761;
BA_REL_ "GenSigSuprvResp" BU_SG_REL_ CGM_HS SG_ 761 BrkSysHRBkCtrlStat 1;
BA_REL_ "GenSigTimeoutTime" BU_SG_REL_ TCM_HS SG_ 761 BrkSysHRBkCtrlStat 250;
BA_REL_ "GenSigTimeoutMsg" BU_SG_REL_ TCM_HS SG_ 761 BrkSysHRBkCtrlStat 761;
BA_REL_ "GenSigSuprvResp" BU_SG_REL_ TCM_HS SG_ 761 BrkSysHRBkCtrlStat 1;
BA_REL_ "GenSigTimeoutTime" BU_SG_REL_ CGM_HS SG_ 761 BrkSysHSAAval 250;
BA_REL_ "GenSigTimeoutMsg" BU_SG_REL_ CGM_HS SG_ 761 BrkSysHSAAval 761;
BA_REL_ "GenSigSuprvResp" BU_SG_REL_ CGM_HS SG_ 761 BrkSysHSAAval 1;
BA_REL_ "GenSigTimeoutTime" BU_SG_REL_ TCM_HS SG_ 761 BrkSysHSAAval 250;
BA_REL_ "GenSigTimeoutMsg" BU_SG_REL_ TCM_HS SG_ 761 BrkSysHSAAval 761;
BA_REL_ "GenSigSuprvResp" BU_SG_REL_ TCM_HS SG_ 761 BrkSysHSAAval 1;
BA_REL_ "GenSigTimeoutTime" BU_SG_REL_ CGM_HS SG_ 761 BrkSysHSAStat 250;
BA_REL_ "GenSigTimeoutMsg" BU_SG_REL_ CGM_HS SG_ 761 BrkSysHSAStat 761;
BA_REL_ "GenSigSuprvResp" BU_SG_REL_ CGM_HS SG_ 761 BrkSysHSAStat 1;
BA_REL_ "GenSigTimeoutTime" BU_SG_REL_ TCM_HS SG_ 761 BrkSysHSAStat 250;
BA_REL_ "GenSigTimeoutMsg" BU_SG_REL_ TCM_HS SG_ 761 BrkSysHSAStat 761;
BA_REL_ "GenSigSuprvResp" BU_SG_REL_ TCM_HS SG_ 761 BrkSysHSAStat 1;
BA_REL_ "GenSigTimeoutTime" BU_SG_REL_ ECM_HS SG_ 761 HillDscntCtrlStatPVal 250;
BA_REL_ "GenSigTimeoutMsg" BU_SG_REL_ ECM_HS SG_ 761 HillDscntCtrlStatPVal 761;
BA_REL_ "GenSigSuprvResp" BU_SG_REL_ ECM_HS SG_ 761 HillDscntCtrlStatPVal 1;
BA_REL_ "GenSigTimeoutTime" BU_SG_REL_ ECM_HS SG_ 761 HillDscntCtrlStatARC 250;
BA_REL_ "GenSigTimeoutMsg" BU_SG_REL_ ECM_HS SG_ 761 HillDscntCtrlStatARC 761;
BA_REL_ "GenSigSuprvResp" BU_SG_REL_ ECM_HS SG_ 761 HillDscntCtrlStatARC 1;
BA_REL_ "GenSigTimeoutTime" BU_SG_REL_ CGM_HS SG_ 761 HillDscntCtrlStat 250;
BA_REL_ "GenSigTimeoutMsg" BU_SG_REL_ CGM_HS SG_ 761 HillDscntCtrlStat 761;
BA_REL_ "GenSigSuprvResp" BU_SG_REL_ CGM_HS SG_ 761 HillDscntCtrlStat 1;
BA_REL_ "GenSigTimeoutTime" BU_SG_REL_ ECM_HS SG_ 761 HillDscntCtrlStat 250;
BA_REL_ "GenSigTimeoutMsg" BU_SG_REL_ ECM_HS SG_ 761 HillDscntCtrlStat 761;
BA_REL_ "GenSigSuprvResp" BU_SG_REL_ ECM_HS SG_ 761 HillDscntCtrlStat 1;
BA_REL_ "GenSigTimeoutTime" BU_SG_REL_ CGM_HS SG_ 761 ABFI_CollPrepSysInhbt 250;
BA_REL_ "GenSigTimeoutMsg" BU_SG_REL_ CGM_HS SG_ 761 ABFI_CollPrepSysInhbt 761;
BA_REL_ "GenSigSuprvResp" BU_SG_REL_ CGM_HS SG_ 761 ABFI_CollPrepSysInhbt 1;
BA_REL_ "GenSigTimeoutTime" BU_SG_REL_ TCM_HS SG_ 761 ABFI_CollPrepSysInhbt 250;
BA_REL_ "GenSigTimeoutMsg" BU_SG_REL_ TCM_HS SG_ 761 ABFI_CollPrepSysInhbt 761;
BA_REL_ "GenSigSuprvResp" BU_SG_REL_ TCM_HS SG_ 761 ABFI_CollPrepSysInhbt 1;
BA_REL_ "GenSigTimeoutTime" BU_SG_REL_ CGM_HS SG_ 761 ABFI_RrVirtlBmprInh 250;
BA_REL_ "GenSigTimeoutMsg" BU_SG_REL_ CGM_HS SG_ 761 ABFI_RrVirtlBmprInh 761;
BA_REL_ "GenSigSuprvResp" BU_SG_REL_ CGM_HS SG_ 761 ABFI_RrVirtlBmprInh 1;
BA_REL_ "GenSigTimeoutTime" BU_SG_REL_ TCM_HS SG_ 761 ABFI_RrVirtlBmprInh 250;
BA_REL_ "GenSigTimeoutMsg" BU_SG_REL_ TCM_HS SG_ 761 ABFI_RrVirtlBmprInh 761;
BA_REL_ "GenSigSuprvResp" BU_SG_REL_ TCM_HS SG_ 761 ABFI_RrVirtlBmprInh 1;
BA_REL_ "GenSigTimeoutTime" BU_SG_REL_ ECM_HS SG_ 761 CAVHS_ACHActv 250;
BA_REL_ "GenSigTimeoutMsg" BU_SG_REL_ ECM_HS SG_ 761 CAVHS_ACHActv 761;
BA_REL_ "GenSigSuprvResp" BU_SG_REL_ ECM_HS SG_ 761 CAVHS_ACHActv 1;
BA_REL_ "GenSigTimeoutTime" BU_SG_REL_ ECM_HS SG_ 761 CAVHS_DSHEnbld 250;
BA_REL_ "GenSigTimeoutMsg" BU_SG_REL_ ECM_HS SG_ 761 CAVHS_DSHEnbld 761;
BA_REL_ "GenSigSuprvResp" BU_SG_REL_ ECM_HS SG_ 761 CAVHS_DSHEnbld 1;
BA_REL_ "GenSigTimeoutTime" BU_SG_REL_ ECM_HS SG_ 761 CAVHS_DSHActv 250;
BA_REL_ "GenSigTimeoutMsg" BU_SG_REL_ ECM_HS SG_ 761 CAVHS_DSHActv 761;
BA_REL_ "GenSigSuprvResp" BU_SG_REL_ ECM_HS SG_ 761 CAVHS_DSHActv 1;
BA_REL_ "GenSigTimeoutTime" BU_SG_REL_ CGM_HS SG_ 761 BrkPdlDrvApplPres 250;
BA_REL_ "GenSigTimeoutMsg" BU_SG_REL_ CGM_HS SG_ 761 BrkPdlDrvApplPres 761;
BA_REL_ "GenSigSuprvResp" BU_SG_REL_ CGM_HS SG_ 761 BrkPdlDrvApplPres 1;
BA_REL_ "GenSigTimeoutTime" BU_SG_REL_ EPS_HS SG_ 761 BrkPdlDrvApplPres 250;
BA_REL_ "GenSigTimeoutMsg" BU_SG_REL_ EPS_HS SG_ 761 BrkPdlDrvApplPres 761;
BA_REL_ "GenSigSuprvResp" BU_SG_REL_ EPS_HS SG_ 761 BrkPdlDrvApplPres 1;
BA_REL_ "GenSigTimeoutTime" BU_SG_REL_ CGM_HS SG_ 761 AutoBrkPTReqStat 250;
BA_REL_ "GenSigTimeoutMsg" BU_SG_REL_ CGM_HS SG_ 761 AutoBrkPTReqStat 761;
BA_REL_ "GenSigSuprvResp" BU_SG_REL_ CGM_HS SG_ 761 AutoBrkPTReqStat 1;
BA_REL_ "GenSigTimeoutTime" BU_SG_REL_ CGM_HS SG_ 761 WhlSpdSnsgDTCIndex 250;
BA_REL_ "GenSigTimeoutMsg" BU_SG_REL_ CGM_HS SG_ 761 WhlSpdSnsgDTCIndex 761;
BA_REL_ "GenSigSuprvResp" BU_SG_REL_ CGM_HS SG_ 761 WhlSpdSnsgDTCIndex 1;
BA_REL_ "GenSigTimeoutTime" BU_SG_REL_ CGM_HS SG_ 761 WhlSpdSnsgDTCStat 250;
BA_REL_ "GenSigTimeoutMsg" BU_SG_REL_ CGM_HS SG_ 761 WhlSpdSnsgDTCStat 761;
BA_REL_ "GenSigSuprvResp" BU_SG_REL_ CGM_HS SG_ 761 WhlSpdSnsgDTCStat 1;
BA_REL_ "GenSigTimeoutTime" BU_SG_REL_ CGM_HS SG_ 761 SprTireSt 250;
BA_REL_ "GenSigTimeoutMsg" BU_SG_REL_ CGM_HS SG_ 761 SprTireSt 761;
BA_REL_ "GenSigSuprvResp" BU_SG_REL_ CGM_HS SG_ 761 SprTireSt 1;
BA_REL_ "GenSigTimeoutTime" BU_SG_REL_ RDCM_HS SG_ 761 SprTireSt 250;
BA_REL_ "GenSigTimeoutMsg" BU_SG_REL_ RDCM_HS SG_ 761 SprTireSt 761;
BA_REL_ "GenSigSuprvResp" BU_SG_REL_ RDCM_HS SG_ 761 SprTireSt 1;
BA_REL_ "GenSigTimeoutTime" BU_SG_REL_ EPS_HS SG_ 761 SprTireSt 250;
BA_REL_ "GenSigTimeoutMsg" BU_SG_REL_ EPS_HS SG_ 761 SprTireSt 761;
BA_REL_ "GenSigSuprvResp" BU_SG_REL_ EPS_HS SG_ 761 SprTireSt 1;
BA_REL_ "GenSigTimeoutTime" BU_SG_REL_ CGM_HS SG_ 489 EnhDrvMdSwChUseRq 250;
BA_REL_ "GenSigTimeoutMsg" BU_SG_REL_ CGM_HS SG_ 489 EnhDrvMdSwChUseRq 489;
BA_REL_ "GenSigSuprvResp" BU_SG_REL_ CGM_HS SG_ 489 EnhDrvMdSwChUseRq 1;
BA_REL_ "GenSigTimeoutTime" BU_SG_REL_ ECM_HS SG_ 489 EnhDrvMdSwChUseRq 50;
BA_REL_ "GenSigTimeoutMsg" BU_SG_REL_ ECM_HS SG_ 489 EnhDrvMdSwChUseRq 489;
BA_REL_ "GenSigSuprvResp" BU_SG_REL_ ECM_HS SG_ 489 EnhDrvMdSwChUseRq 1;
BA_REL_ "GenSigTimeoutTime" BU_SG_REL_ CGM_HS SG_ 489 DrvIndpntBrkAppAct 250;
BA_REL_ "GenSigTimeoutMsg" BU_SG_REL_ CGM_HS SG_ 489 DrvIndpntBrkAppAct 489;
BA_REL_ "GenSigSuprvResp" BU_SG_REL_ CGM_HS SG_ 489 DrvIndpntBrkAppAct 1;
BA_REL_ "GenSigTimeoutTime" BU_SG_REL_ TCM_HS SG_ 489 DrvIndpntBrkAppAct 50;
BA_REL_ "GenSigTimeoutMsg" BU_SG_REL_ TCM_HS SG_ 489 DrvIndpntBrkAppAct 489;
BA_REL_ "GenSigSuprvResp" BU_SG_REL_ TCM_HS SG_ 489 DrvIndpntBrkAppAct 1;
BA_REL_ "GenSigTimeoutTime" BU_SG_REL_ ECM_HS SG_ 489 DrvIndpntBrkAppAct 50;
BA_REL_ "GenSigTimeoutMsg" BU_SG_REL_ ECM_HS SG_ 489 DrvIndpntBrkAppAct 489;
BA_REL_ "GenSigSuprvResp" BU_SG_REL_ ECM_HS SG_ 489 DrvIndpntBrkAppAct 1;
BA_REL_ "GenSigTimeoutTime" BU_SG_REL_ CGM_HS SG_ 489 WhlSlpSt 250;
BA_REL_ "GenSigTimeoutMsg" BU_SG_REL_ CGM_HS SG_ 489 WhlSlpSt 489;
BA_REL_ "GenSigSuprvResp" BU_SG_REL_ CGM_HS SG_ 489 WhlSlpSt 1;
BA_REL_ "GenSigTimeoutTime" BU_SG_REL_ ECM_HS SG_ 489 WhlSlpSt 50;
BA_REL_ "GenSigTimeoutMsg" BU_SG_REL_ ECM_HS SG_ 489 WhlSlpSt 489;
BA_REL_ "GenSigSuprvResp" BU_SG_REL_ ECM_HS SG_ 489 WhlSlpSt 1;
BA_REL_ "GenSigTimeoutTime" BU_SG_REL_ CGM_HS SG_ 489 BSTGRReqdGear 250;
BA_REL_ "GenSigTimeoutMsg" BU_SG_REL_ CGM_HS SG_ 489 BSTGRReqdGear 489;
BA_REL_ "GenSigSuprvResp" BU_SG_REL_ CGM_HS SG_ 489 BSTGRReqdGear 1;
BA_REL_ "GenSigRxStartValue" BU_SG_REL_ TCM_HS SG_ 489 BSTGRReqdGear "$0 - No Action";
BA_REL_ "GenSigTimeoutTime" BU_SG_REL_ CGM_HS SG_ 489 BSTGRReqType 250;
BA_REL_ "GenSigTimeoutMsg" BU_SG_REL_ CGM_HS SG_ 489 BSTGRReqType 489;
BA_REL_ "GenSigSuprvResp" BU_SG_REL_ CGM_HS SG_ 489 BSTGRReqType 1;
BA_REL_ "GenSigRxStartValue" BU_SG_REL_ TCM_HS SG_ 489 BSTGRReqType "$0 - No Action";
BA_REL_ "GenSigTimeoutTime" BU_SG_REL_ CGM_HS SG_ 489 VehDynOvrUndrStr 250;
BA_REL_ "GenSigTimeoutMsg" BU_SG_REL_ CGM_HS SG_ 489 VehDynOvrUndrStr 489;
BA_REL_ "GenSigSuprvResp" BU_SG_REL_ CGM_HS SG_ 489 VehDynOvrUndrStr 1;
BA_REL_ "GenSigTimeoutTime" BU_SG_REL_ EPS_HS SG_ 489 VehDynOvrUndrStr 250;
BA_REL_ "GenSigTimeoutMsg" BU_SG_REL_ EPS_HS SG_ 489 VehDynOvrUndrStr 489;
BA_REL_ "GenSigSuprvResp" BU_SG_REL_ EPS_HS SG_ 489 VehDynOvrUndrStr 1;
BA_REL_ "GenSigTimeoutTime" BU_SG_REL_ CGM_HS SG_ 489 VhDynCntlSysSt 250;
BA_REL_ "GenSigTimeoutMsg" BU_SG_REL_ CGM_HS SG_ 489 VhDynCntlSysSt 489;
BA_REL_ "GenSigSuprvResp" BU_SG_REL_ CGM_HS SG_ 489 VhDynCntlSysSt 1;
BA_REL_ "GenSigTimeoutTime" BU_SG_REL_ RDCM_HS SG_ 489 VhDynCntlSysSt 250;
BA_REL_ "GenSigTimeoutMsg" BU_SG_REL_ RDCM_HS SG_ 489 VhDynCntlSysSt 489;
BA_REL_ "GenSigSuprvResp" BU_SG_REL_ RDCM_HS SG_ 489 VhDynCntlSysSt 1;
BA_REL_ "GenSigTimeoutTime" BU_SG_REL_ CGM_HS SG_ 489 TrnsBrkSysCltchRelRqd 250;
BA_REL_ "GenSigTimeoutMsg" BU_SG_REL_ CGM_HS SG_ 489 TrnsBrkSysCltchRelRqd 489;
BA_REL_ "GenSigSuprvResp" BU_SG_REL_ CGM_HS SG_ 489 TrnsBrkSysCltchRelRqd 1;
BA_REL_ "GenSigTimeoutTime" BU_SG_REL_ TCM_HS SG_ 489 TrnsBrkSysCltchRelRqd 50;
BA_REL_ "GenSigTimeoutMsg" BU_SG_REL_ TCM_HS SG_ 489 TrnsBrkSysCltchRelRqd 489;
BA_REL_ "GenSigRxStartValue" BU_SG_REL_ TCM_HS SG_ 489 TrnsBrkSysCltchRelRqd "False";
BA_REL_ "GenSigSuprvResp" BU_SG_REL_ TCM_HS SG_ 489 TrnsBrkSysCltchRelRqd 1;
BA_REL_ "GenSigTimeoutTime" BU_SG_REL_ CGM_HS SG_ 489 TracCntrlSysDrIntnt 250;
BA_REL_ "GenSigTimeoutMsg" BU_SG_REL_ CGM_HS SG_ 489 TracCntrlSysDrIntnt 489;
BA_REL_ "GenSigSuprvResp" BU_SG_REL_ CGM_HS SG_ 489 TracCntrlSysDrIntnt 1;
BA_REL_ "GenSigTimeoutTime" BU_SG_REL_ RDCM_HS SG_ 489 TracCntrlSysDrIntnt 250;
BA_REL_ "GenSigTimeoutMsg" BU_SG_REL_ RDCM_HS SG_ 489 TracCntrlSysDrIntnt 489;
BA_REL_ "GenSigSuprvResp" BU_SG_REL_ RDCM_HS SG_ 489 TracCntrlSysDrIntnt 1;
BA_REL_ "GenSigTimeoutTime" BU_SG_REL_ EPS_HS SG_ 489 TracCntrlSysDrIntnt 250;
BA_REL_ "GenSigTimeoutMsg" BU_SG_REL_ EPS_HS SG_ 489 TracCntrlSysDrIntnt 489;
BA_REL_ "GenSigSuprvResp" BU_SG_REL_ EPS_HS SG_ 489 TracCntrlSysDrIntnt 1;
BA_REL_ "GenSigTimeoutTime" BU_SG_REL_ CGM_HS SG_ 489 TCSysEnbld 250;
BA_REL_ "GenSigTimeoutMsg" BU_SG_REL_ CGM_HS SG_ 489 TCSysEnbld 489;
BA_REL_ "GenSigSuprvResp" BU_SG_REL_ CGM_HS SG_ 489 TCSysEnbld 1;
BA_REL_ "GenSigTimeoutTime" BU_SG_REL_ RDCM_HS SG_ 489 TCSysEnbld 250;
BA_REL_ "GenSigTimeoutMsg" BU_SG_REL_ RDCM_HS SG_ 489 TCSysEnbld 489;
BA_REL_ "GenSigSuprvResp" BU_SG_REL_ RDCM_HS SG_ 489 TCSysEnbld 1;
BA_REL_ "GenSigTimeoutTime" BU_SG_REL_ CGM_HS SG_ 489 BrkPdlDrvAppPrsDetcd 250;
BA_REL_ "GenSigTimeoutMsg" BU_SG_REL_ CGM_HS SG_ 489 BrkPdlDrvAppPrsDetcd 489;
BA_REL_ "GenSigSuprvResp" BU_SG_REL_ CGM_HS SG_ 489 BrkPdlDrvAppPrsDetcd 1;
BA_REL_ "GenSigVBitResp" BU_SG_REL_ ECM_HS SG_ 489 BrkPdlDrvAppPrsDetcd 1;
BA_REL_ "GenSigTimeoutTime" BU_SG_REL_ EPS_HS SG_ 489 BrkPdlDrvAppPrsDetcd 250;
BA_REL_ "GenSigTimeoutMsg" BU_SG_REL_ EPS_HS SG_ 489 BrkPdlDrvAppPrsDetcd 489;
BA_REL_ "GenSigSuprvResp" BU_SG_REL_ EPS_HS SG_ 489 BrkPdlDrvAppPrsDetcd 1;
BA_REL_ "GenSigTimeoutTime" BU_SG_REL_ CGM_HS SG_ 489 ACCBrkngAct 250;
BA_REL_ "GenSigTimeoutMsg" BU_SG_REL_ CGM_HS SG_ 489 ACCBrkngAct 489;
BA_REL_ "GenSigSuprvResp" BU_SG_REL_ CGM_HS SG_ 489 ACCBrkngAct 1;
BA_REL_ "GenSigTimeoutTime" BU_SG_REL_ CGM_HS SG_ 489 ABSFld 250;
BA_REL_ "GenSigTimeoutMsg" BU_SG_REL_ CGM_HS SG_ 489 ABSFld 489;
BA_REL_ "GenSigSuprvResp" BU_SG_REL_ CGM_HS SG_ 489 ABSFld 1;
BA_REL_ "GenSigTimeoutTime" BU_SG_REL_ CGM_HS SG_ 489 VSELatAcc 250;
BA_REL_ "GenSigTimeoutMsg" BU_SG_REL_ CGM_HS SG_ 489 VSELatAcc 489;
BA_REL_ "GenSigSuprvResp" BU_SG_REL_ CGM_HS SG_ 489 VSELatAcc 1;
BA_REL_ "GenSigTimeoutTime" BU_SG_REL_ EPS_HS SG_ 489 VSELatAcc 250;
BA_REL_ "GenSigTimeoutMsg" BU_SG_REL_ EPS_HS SG_ 489 VSELatAcc 489;
BA_REL_ "GenSigSuprvResp" BU_SG_REL_ EPS_HS SG_ 489 VSELatAcc 1;
BA_REL_ "GenSigTimeoutTime" BU_SG_REL_ CGM_HS SG_ 489 VSEAct 250;
BA_REL_ "GenSigTimeoutMsg" BU_SG_REL_ CGM_HS SG_ 489 VSEAct 489;
BA_REL_ "GenSigSuprvResp" BU_SG_REL_ CGM_HS SG_ 489 VSEAct 1;
BA_REL_ "GenSigTimeoutTime" BU_SG_REL_ TCM_HS SG_ 489 VSEAct 50;
BA_REL_ "GenSigTimeoutMsg" BU_SG_REL_ TCM_HS SG_ 489 VSEAct 489;
BA_REL_ "GenSigSuprvResp" BU_SG_REL_ TCM_HS SG_ 489 VSEAct 1;
BA_REL_ "GenSigTimeoutTime" BU_SG_REL_ BCM_HS SG_ 489 VehDynYawRateV 250;
BA_REL_ "GenSigTimeoutMsg" BU_SG_REL_ BCM_HS SG_ 489 VehDynYawRateV 489;
BA_REL_ "GenSigSuprvRespSubValue" BU_SG_REL_ BCM_HS SG_ 489 VehDynYawRateV 1;
BA_REL_ "GenSigSuprvResp" BU_SG_REL_ BCM_HS SG_ 489 VehDynYawRateV 2;
BA_REL_ "GenSigTimeoutTime" BU_SG_REL_ CGM_HS SG_ 489 VehDynYawRate 250;
BA_REL_ "GenSigTimeoutMsg" BU_SG_REL_ CGM_HS SG_ 489 VehDynYawRate 489;
BA_REL_ "GenSigSuprvResp" BU_SG_REL_ CGM_HS SG_ 489 VehDynYawRate 1;
BA_REL_ "GenSigTimeoutTime" BU_SG_REL_ BCM_HS SG_ 489 VehDynYawRate 250;
BA_REL_ "GenSigTimeoutMsg" BU_SG_REL_ BCM_HS SG_ 489 VehDynYawRate 489;
BA_REL_ "GenSigVBitResp" BU_SG_REL_ BCM_HS SG_ 489 VehDynYawRate 1;
BA_REL_ "GenSigSuprvResp" BU_SG_REL_ BCM_HS SG_ 489 VehDynYawRate 1;
BA_REL_ "GenSigTimeoutTime" BU_SG_REL_ CGM_HS SG_ 489 TCSysAtv 250;
BA_REL_ "GenSigTimeoutMsg" BU_SG_REL_ CGM_HS SG_ 489 TCSysAtv 489;
BA_REL_ "GenSigSuprvResp" BU_SG_REL_ CGM_HS SG_ 489 TCSysAtv 1;
BA_REL_ "GenSigTimeoutTime" BU_SG_REL_ CGM_HS SG_ 489 ABSAtv 250;
BA_REL_ "GenSigTimeoutMsg" BU_SG_REL_ CGM_HS SG_ 489 ABSAtv 489;
BA_REL_ "GenSigSuprvResp" BU_SG_REL_ CGM_HS SG_ 489 ABSAtv 1;
BA_REL_ "GenSigTimeoutTime" BU_SG_REL_ RDCM_HS SG_ 489 ABSAtv 250;
BA_REL_ "GenSigTimeoutMsg" BU_SG_REL_ RDCM_HS SG_ 489 ABSAtv 489;
BA_REL_ "GenSigSuprvResp" BU_SG_REL_ RDCM_HS SG_ 489 ABSAtv 1;
BA_REL_ "GenSigTimeoutTime" BU_SG_REL_ BCM_HS SG_ 489 ABSAtv 250;
BA_REL_ "GenSigTimeoutMsg" BU_SG_REL_ BCM_HS SG_ 489 ABSAtv 489;
BA_REL_ "GenSigSuprvResp" BU_SG_REL_ BCM_HS SG_ 489 ABSAtv 1;
BA_REL_ "GenSigTimeoutTime" BU_SG_REL_ ECM_HS SG_ 381 BrkSysStCrwlModeOvrrd 250;
BA_REL_ "GenSigTimeoutMsg" BU_SG_REL_ ECM_HS SG_ 381 BrkSysStCrwlModeOvrrd 381;
BA_REL_ "GenSigSuprvResp" BU_SG_REL_ ECM_HS SG_ 381 BrkSysStCrwlModeOvrrd 1;
BA_REL_ "GenSigTimeoutTime" BU_SG_REL_ BCM_HS SG_ 381 VehStbCmptvMdCstAvl 250;
BA_REL_ "GenSigTimeoutMsg" BU_SG_REL_ BCM_HS SG_ 381 VehStbCmptvMdCstAvl 381;
BA_REL_ "GenSigSuprvResp" BU_SG_REL_ BCM_HS SG_ 381 VehStbCmptvMdCstAvl 1;
BA_REL_ "GenSigTimeoutTime" BU_SG_REL_ BCM_HS SG_ 381 VehStbEnmntCstAvl 250;
BA_REL_ "GenSigTimeoutMsg" BU_SG_REL_ BCM_HS SG_ 381 VehStbEnmntCstAvl 381;
BA_REL_ "GenSigSuprvResp" BU_SG_REL_ BCM_HS SG_ 381 VehStbEnmntCstAvl 1;
BA_REL_ "GenSigTimeoutTime" BU_SG_REL_ BCM_HS SG_ 381 VehStbCmptvMdCurSt 250;
BA_REL_ "GenSigTimeoutMsg" BU_SG_REL_ BCM_HS SG_ 381 VehStbCmptvMdCurSt 381;
BA_REL_ "GenSigSuprvResp" BU_SG_REL_ BCM_HS SG_ 381 VehStbCmptvMdCurSt 1;
BA_REL_ "GenSigTimeoutTime" BU_SG_REL_ BCM_HS SG_ 381 VehStbEnhmntCurSt 250;
BA_REL_ "GenSigTimeoutMsg" BU_SG_REL_ BCM_HS SG_ 381 VehStbEnhmntCurSt 381;
BA_REL_ "GenSigSuprvResp" BU_SG_REL_ BCM_HS SG_ 381 VehStbEnhmntCurSt 1;
BA_REL_ "GenSigTimeoutTime" BU_SG_REL_ BCM_HS SG_ 381 TCSTempDsblReqIO 250;
BA_REL_ "GenSigTimeoutMsg" BU_SG_REL_ BCM_HS SG_ 381 TCSTempDsblReqIO 381;
BA_REL_ "GenSigSuprvResp" BU_SG_REL_ BCM_HS SG_ 381 TCSTempDsblReqIO 1;
BA_REL_ "GenSigTimeoutTime" BU_SG_REL_ BCM_HS SG_ 381 TCSysCstAvl 250;
BA_REL_ "GenSigTimeoutMsg" BU_SG_REL_ BCM_HS SG_ 381 TCSysCstAvl 381;
BA_REL_ "GenSigSuprvResp" BU_SG_REL_ BCM_HS SG_ 381 TCSysCstAvl 1;
BA_REL_ "GenSigTimeoutTime" BU_SG_REL_ BCM_HS SG_ 381 TCSysCurSt 250;
BA_REL_ "GenSigTimeoutMsg" BU_SG_REL_ BCM_HS SG_ 381 TCSysCurSt 381;
BA_REL_ "GenSigSuprvResp" BU_SG_REL_ BCM_HS SG_ 381 TCSysCurSt 1;
BA_REL_ "GenSigTimeoutTime" BU_SG_REL_ BCM_HS SG_ 381 TracAndStbScrnCnfg 250;
BA_REL_ "GenSigTimeoutMsg" BU_SG_REL_ BCM_HS SG_ 381 TracAndStbScrnCnfg 381;
BA_REL_ "GenSigSuprvResp" BU_SG_REL_ BCM_HS SG_ 381 TracAndStbScrnCnfg 1;
BA_REL_ "GenSigTimeoutTime" BU_SG_REL_ CGM_HS SG_ 381 HillDesCtrlRedVehSpIO 250;
BA_REL_ "GenSigTimeoutMsg" BU_SG_REL_ CGM_HS SG_ 381 HillDesCtrlRedVehSpIO 381;
BA_REL_ "GenSigSuprvResp" BU_SG_REL_ CGM_HS SG_ 381 HillDesCtrlRedVehSpIO 1;
BA_REL_ "GenSigTimeoutTime" BU_SG_REL_ BCM_HS SG_ 381 HillDesCtrlRedVehSpIO 250;
BA_REL_ "GenSigTimeoutMsg" BU_SG_REL_ BCM_HS SG_ 381 HillDesCtrlRedVehSpIO 381;
BA_REL_ "GenSigSuprvResp" BU_SG_REL_ BCM_HS SG_ 381 HillDesCtrlRedVehSpIO 1;
BA_REL_ "GenSigTimeoutTime" BU_SG_REL_ CGM_HS SG_ 381 EBDFailed 250;
BA_REL_ "GenSigTimeoutMsg" BU_SG_REL_ CGM_HS SG_ 381 EBDFailed 381;
BA_REL_ "GenSigSuprvResp" BU_SG_REL_ CGM_HS SG_ 381 EBDFailed 1;
BA_REL_ "GenSigSuprvResp" BU_SG_REL_ RDCM_HS SG_ 381 StWhAnVDA 1;
BA_REL_ "GenSigTimeoutTime" BU_SG_REL_ BCM_HS SG_ 381 StWhAnVDA 250;
BA_REL_ "GenSigTimeoutMsg" BU_SG_REL_ BCM_HS SG_ 381 StWhAnVDA 381;
BA_REL_ "GenSigSuprvResp" BU_SG_REL_ BCM_HS SG_ 381 StWhAnVDA 2;
BA_REL_ "GenSigTimeoutTime" BU_SG_REL_ CGM_HS SG_ 381 TirePrsLowIO 250;
BA_REL_ "GenSigTimeoutMsg" BU_SG_REL_ CGM_HS SG_ 381 TirePrsLowIO 381;
BA_REL_ "GenSigSuprvResp" BU_SG_REL_ CGM_HS SG_ 381 TirePrsLowIO 1;
BA_REL_ "GenSigTimeoutTime" BU_SG_REL_ BCM_HS SG_ 381 TirePrsLowIO 250;
BA_REL_ "GenSigTimeoutMsg" BU_SG_REL_ BCM_HS SG_ 381 TirePrsLowIO 381;
BA_REL_ "GenSigSuprvResp" BU_SG_REL_ BCM_HS SG_ 381 TirePrsLowIO 1;
BA_REL_ "GenSigTimeoutTime" BU_SG_REL_ CGM_HS SG_ 381 VaccBoostFailure 250;
BA_REL_ "GenSigTimeoutMsg" BU_SG_REL_ CGM_HS SG_ 381 VaccBoostFailure 381;
BA_REL_ "GenSigSuprvResp" BU_SG_REL_ CGM_HS SG_ 381 VaccBoostFailure 1;
BA_REL_ "GenSigTimeoutTime" BU_SG_REL_ CGM_HS SG_ 381 VSESysPrs 250;
BA_REL_ "GenSigTimeoutMsg" BU_SG_REL_ CGM_HS SG_ 381 VSESysPrs 381;
BA_REL_ "GenSigSuprvResp" BU_SG_REL_ CGM_HS SG_ 381 VSESysPrs 1;
BA_REL_ "GenSigTimeoutTime" BU_SG_REL_ CGM_HS SG_ 381 HalfSysFail 250;
BA_REL_ "GenSigTimeoutMsg" BU_SG_REL_ CGM_HS SG_ 381 HalfSysFail 381;
BA_REL_ "GenSigSuprvResp" BU_SG_REL_ CGM_HS SG_ 381 HalfSysFail 1;
BA_REL_ "GenSigTimeoutTime" BU_SG_REL_ CGM_HS SG_ 381 ActVehAccel 250;
BA_REL_ "GenSigTimeoutMsg" BU_SG_REL_ CGM_HS SG_ 381 ActVehAccel 381;
BA_REL_ "GenSigSuprvResp" BU_SG_REL_ CGM_HS SG_ 381 ActVehAccel 1;
BA_REL_ "GenSigTimeoutTime" BU_SG_REL_ BSM_HS SG_ 381 ActVehAccel 500;
BA_REL_ "GenSigTimeoutMsg" BU_SG_REL_ BSM_HS SG_ 381 ActVehAccel 381;
BA_REL_ "GenSigSuprvResp" BU_SG_REL_ BSM_HS SG_ 381 ActVehAccel 1;
BA_REL_ "GenSigTimeoutTime" BU_SG_REL_ CGM_HS SG_ 381 BksOvht 250;
BA_REL_ "GenSigTimeoutMsg" BU_SG_REL_ CGM_HS SG_ 381 BksOvht 381;
BA_REL_ "GenSigSuprvResp" BU_SG_REL_ CGM_HS SG_ 381 BksOvht 1;
BA_REL_ "GenSigTimeoutTime" BU_SG_REL_ CGM_HS SG_ 381 TCSysPr 250;
BA_REL_ "GenSigTimeoutMsg" BU_SG_REL_ CGM_HS SG_ 381 TCSysPr 381;
BA_REL_ "GenSigSuprvResp" BU_SG_REL_ CGM_HS SG_ 381 TCSysPr 1;
BA_REL_ "GenSigTimeoutTime" BU_SG_REL_ CGM_HS SG_ 381 ABSPr 250;
BA_REL_ "GenSigTimeoutMsg" BU_SG_REL_ CGM_HS SG_ 381 ABSPr 381;
BA_REL_ "GenSigSuprvResp" BU_SG_REL_ CGM_HS SG_ 381 ABSPr 1;
BA_REL_ "GenSigTimeoutTime" BU_SG_REL_ CGM_HS SG_ 381 TreInfMonSysRstPrfmd 250;
BA_REL_ "GenSigTimeoutMsg" BU_SG_REL_ CGM_HS SG_ 381 TreInfMonSysRstPrfmd 381;
BA_REL_ "GenSigSuprvResp" BU_SG_REL_ CGM_HS SG_ 381 TreInfMonSysRstPrfmd 1;
BA_REL_ "GenSigTimeoutTime" BU_SG_REL_ BCM_HS SG_ 381 TreInfMonSysRstPrfmd 250;
BA_REL_ "GenSigTimeoutMsg" BU_SG_REL_ BCM_HS SG_ 381 TreInfMonSysRstPrfmd 381;
BA_REL_ "GenSigSuprvResp" BU_SG_REL_ BCM_HS SG_ 381 TreInfMonSysRstPrfmd 1;
BA_REL_ "GenSigTimeoutTime" BU_SG_REL_ CGM_HS SG_ 381 ABSIO 250;
BA_REL_ "GenSigTimeoutMsg" BU_SG_REL_ CGM_HS SG_ 381 ABSIO 381;
BA_REL_ "GenSigSuprvResp" BU_SG_REL_ CGM_HS SG_ 381 ABSIO 1;
BA_REL_ "GenSigTimeoutTime" BU_SG_REL_ BCM_HS SG_ 381 ABSIO 250;
BA_REL_ "GenSigTimeoutMsg" BU_SG_REL_ BCM_HS SG_ 381 ABSIO 381;
BA_REL_ "GenSigSuprvResp" BU_SG_REL_ BCM_HS SG_ 381 ABSIO 1;
BA_REL_ "GenSigTimeoutTime" BU_SG_REL_ CGM_HS SG_ 381 BrkPadWrnIO 250;
BA_REL_ "GenSigTimeoutMsg" BU_SG_REL_ CGM_HS SG_ 381 BrkPadWrnIO 381;
BA_REL_ "GenSigSuprvResp" BU_SG_REL_ CGM_HS SG_ 381 BrkPadWrnIO 1;
BA_REL_ "GenSigTimeoutTime" BU_SG_REL_ BCM_HS SG_ 381 BrkPadWrnIO 250;
BA_REL_ "GenSigTimeoutMsg" BU_SG_REL_ BCM_HS SG_ 381 BrkPadWrnIO 381;
BA_REL_ "GenSigSuprvResp" BU_SG_REL_ BCM_HS SG_ 381 BrkPadWrnIO 1;
BA_REL_ "GenSigTimeoutTime" BU_SG_REL_ CGM_HS SG_ 381 VehStabEnhmntMd 250;
BA_REL_ "GenSigTimeoutMsg" BU_SG_REL_ CGM_HS SG_ 381 VehStabEnhmntMd 381;
BA_REL_ "GenSigSuprvResp" BU_SG_REL_ CGM_HS SG_ 381 VehStabEnhmntMd 1;
BA_REL_ "GenSigTimeoutTime" BU_SG_REL_ RDCM_HS SG_ 381 VehStabEnhmntMd 250;
BA_REL_ "GenSigTimeoutMsg" BU_SG_REL_ RDCM_HS SG_ 381 VehStabEnhmntMd 381;
BA_REL_ "GenSigRxStartValue" BU_SG_REL_ RDCM_HS SG_ 381 VehStabEnhmntMd "$1 - Normal";
BA_REL_ "GenSigSuprvResp" BU_SG_REL_ RDCM_HS SG_ 381 VehStabEnhmntMd 1;
BA_REL_ "GenSigTimeoutTime" BU_SG_REL_ ECM_HS SG_ 381 VehStabEnhmntMd 250;
BA_REL_ "GenSigTimeoutMsg" BU_SG_REL_ ECM_HS SG_ 381 VehStabEnhmntMd 381;
BA_REL_ "GenSigSuprvResp" BU_SG_REL_ ECM_HS SG_ 381 VehStabEnhmntMd 1;
BA_REL_ "GenSigTimeoutTime" BU_SG_REL_ BCM_HS SG_ 381 VehStabEnhmntMd 250;
BA_REL_ "GenSigTimeoutMsg" BU_SG_REL_ BCM_HS SG_ 381 VehStabEnhmntMd 381;
BA_REL_ "GenSigRxStartValue" BU_SG_REL_ BCM_HS SG_ 381 VehStabEnhmntMd "$1 - Normal";
BA_REL_ "GenSigSuprvResp" BU_SG_REL_ BCM_HS SG_ 381 VehStabEnhmntMd 1;
BA_REL_ "GenSigTimeoutTime" BU_SG_REL_ CGM_HS SG_ 381 VehStabEnhmntStat 250;
BA_REL_ "GenSigTimeoutMsg" BU_SG_REL_ CGM_HS SG_ 381 VehStabEnhmntStat 381;
BA_REL_ "GenSigSuprvResp" BU_SG_REL_ CGM_HS SG_ 381 VehStabEnhmntStat 1;
BA_REL_ "GenSigTimeoutTime" BU_SG_REL_ ECM_HS SG_ 381 VehStabEnhmntStat 250;
BA_REL_ "GenSigTimeoutMsg" BU_SG_REL_ ECM_HS SG_ 381 VehStabEnhmntStat 381;
BA_REL_ "GenSigSuprvResp" BU_SG_REL_ ECM_HS SG_ 381 VehStabEnhmntStat 1;
BA_REL_ "GenSigTimeoutTime" BU_SG_REL_ EPS_HS SG_ 381 VehStabEnhmntStat 250;
BA_REL_ "GenSigTimeoutMsg" BU_SG_REL_ EPS_HS SG_ 381 VehStabEnhmntStat 381;
BA_REL_ "GenSigSuprvResp" BU_SG_REL_ EPS_HS SG_ 381 VehStabEnhmntStat 1;
BA_REL_ "GenSigTimeoutTime" BU_SG_REL_ BCM_HS SG_ 381 VehStabEnhmntStat 250;
BA_REL_ "GenSigTimeoutMsg" BU_SG_REL_ BCM_HS SG_ 381 VehStabEnhmntStat 381;
BA_REL_ "GenSigSuprvResp" BU_SG_REL_ BCM_HS SG_ 381 VehStabEnhmntStat 1;
BA_REL_ "GenSigRxStartValue" BU_SG_REL_ RDCM_HS SG_ 381 TCSysOpMd "$1 - Normal";
BA_REL_ "GenSigTimeoutTime" BU_SG_REL_ ECM_HS SG_ 381 TCSysOpMd 250;
BA_REL_ "GenSigTimeoutMsg" BU_SG_REL_ ECM_HS SG_ 381 TCSysOpMd 381;
BA_REL_ "GenSigSuprvResp" BU_SG_REL_ ECM_HS SG_ 381 TCSysOpMd 1;
BA_REL_ "GenSigTimeoutTime" BU_SG_REL_ EPS_HS SG_ 381 TCSysOpMd 250;
BA_REL_ "GenSigTimeoutMsg" BU_SG_REL_ EPS_HS SG_ 381 TCSysOpMd 381;
BA_REL_ "GenSigSuprvResp" BU_SG_REL_ EPS_HS SG_ 381 TCSysOpMd 1;
BA_REL_ "GenSigTimeoutTime" BU_SG_REL_ CGM_HS SG_ 381 TCSysOpMd 250;
BA_REL_ "GenSigTimeoutMsg" BU_SG_REL_ CGM_HS SG_ 381 TCSysOpMd 381;
BA_REL_ "GenSigSuprvResp" BU_SG_REL_ CGM_HS SG_ 381 TCSysOpMd 1;
BA_REL_ "GenSigTimeoutTime" BU_SG_REL_ BCM_HS SG_ 381 TCSysOpMd 250;
BA_REL_ "GenSigTimeoutMsg" BU_SG_REL_ BCM_HS SG_ 381 TCSysOpMd 381;
BA_REL_ "GenSigRxStartValue" BU_SG_REL_ BCM_HS SG_ 381 TCSysOpMd "$1 - Normal";
BA_REL_ "GenSigSuprvResp" BU_SG_REL_ BCM_HS SG_ 381 TCSysOpMd 1;
BA_REL_ "GenSigTimeoutTime" BU_SG_REL_ ECM_HS SG_ 381 TCSysOpStat 250;
BA_REL_ "GenSigTimeoutMsg" BU_SG_REL_ ECM_HS SG_ 381 TCSysOpStat 381;
BA_REL_ "GenSigSuprvResp" BU_SG_REL_ ECM_HS SG_ 381 TCSysOpStat 1;
BA_REL_ "GenSigTimeoutTime" BU_SG_REL_ CGM_HS SG_ 381 TCSysOpStat 250;
BA_REL_ "GenSigTimeoutMsg" BU_SG_REL_ CGM_HS SG_ 381 TCSysOpStat 381;
BA_REL_ "GenSigSuprvResp" BU_SG_REL_ CGM_HS SG_ 381 TCSysOpStat 1;
BA_REL_ "GenSigTimeoutTime" BU_SG_REL_ BCM_HS SG_ 381 TCSysOpStat 250;
BA_REL_ "GenSigTimeoutMsg" BU_SG_REL_ BCM_HS SG_ 381 TCSysOpStat 381;
BA_REL_ "GenSigSuprvResp" BU_SG_REL_ BCM_HS SG_ 381 TCSysOpStat 1;
BA_REL_ "GenSigTimeoutTime" BU_SG_REL_ CGM_HS SG_ 381 BrkSysVTopSpdLimVal 250;
BA_REL_ "GenSigTimeoutMsg" BU_SG_REL_ CGM_HS SG_ 381 BrkSysVTopSpdLimVal 381;
BA_REL_ "GenSigSuprvResp" BU_SG_REL_ CGM_HS SG_ 381 BrkSysVTopSpdLimVal 1;
BA_REL_ "GenSigTimeoutTime" BU_SG_REL_ BCM_HS SG_ 381 BrkSysVTopSpdLimVal 250;
BA_REL_ "GenSigTimeoutMsg" BU_SG_REL_ BCM_HS SG_ 381 BrkSysVTopSpdLimVal 381;
BA_REL_ "GenSigSuprvRespSubValue" BU_SG_REL_ BCM_HS SG_ 381 BrkSysVTopSpdLimVal 255;
BA_REL_ "GenSigSuprvResp" BU_SG_REL_ BCM_HS SG_ 381 BrkSysVTopSpdLimVal 2;
BA_REL_ "GenSigTimeoutTime" BU_SG_REL_ CGM_HS SG_ 381 BrkSysRedBrkTlltlReq 250;
BA_REL_ "GenSigTimeoutMsg" BU_SG_REL_ CGM_HS SG_ 381 BrkSysRedBrkTlltlReq 381;
BA_REL_ "GenSigSuprvResp" BU_SG_REL_ CGM_HS SG_ 381 BrkSysRedBrkTlltlReq 1;
BA_REL_ "GenSigTimeoutTime" BU_SG_REL_ CGM_HS SG_ 381 BrkSysBrkLtsReqd 250;
BA_REL_ "GenSigTimeoutMsg" BU_SG_REL_ CGM_HS SG_ 381 BrkSysBrkLtsReqd 381;
BA_REL_ "GenSigSuprvResp" BU_SG_REL_ CGM_HS SG_ 381 BrkSysBrkLtsReqd 1;
BA_REL_ "GenSigTimeoutTime" BU_SG_REL_ BCM_HS SG_ 381 BrkSysBrkLtsReqd 250;
BA_REL_ "GenSigTimeoutMsg" BU_SG_REL_ BCM_HS SG_ 381 BrkSysBrkLtsReqd 381;
BA_REL_ "GenSigSuprvResp" BU_SG_REL_ BCM_HS SG_ 381 BrkSysBrkLtsReqd 2;
BA_REL_ "GenSigTimeoutTime" BU_SG_REL_ ECM_HS SG_ 1279 ClmCntHtrMinFlwRtRqVDA 2500;
BA_REL_ "GenSigTimeoutMsg" BU_SG_REL_ ECM_HS SG_ 1279 ClmCntHtrMinFlwRtRqVDA 1279;
BA_REL_ "GenSigSuprvResp" BU_SG_REL_ ECM_HS SG_ 1279 ClmCntHtrMinFlwRtRqVDA 1;
BA_REL_ "GenSigTimeoutTime" BU_SG_REL_ ECM_HS SG_ 1279 ClmCntPrtyHtRq 2500;
BA_REL_ "GenSigTimeoutMsg" BU_SG_REL_ ECM_HS SG_ 1279 ClmCntPrtyHtRq 1279;
BA_REL_ "GenSigSuprvResp" BU_SG_REL_ ECM_HS SG_ 1279 ClmCntPrtyHtRq 1;
BA_REL_ "GenSigTimeoutTime" BU_SG_REL_ ECM_HS SG_ 1279 ClmCntCalcTrgtCbnHtLd 2500;
BA_REL_ "GenSigTimeoutMsg" BU_SG_REL_ ECM_HS SG_ 1279 ClmCntCalcTrgtCbnHtLd 1279;
BA_REL_ "GenSigSuprvResp" BU_SG_REL_ ECM_HS SG_ 1279 ClmCntCalcTrgtCbnHtLd 1;
BA_REL_ "GenSigTimeoutTime" BU_SG_REL_ ECM_HS SG_ 1279 ClmCntMinTrgtClntTmp 2500;
BA_REL_ "GenSigTimeoutMsg" BU_SG_REL_ ECM_HS SG_ 1279 ClmCntMinTrgtClntTmp 1279;
BA_REL_ "GenSigSuprvResp" BU_SG_REL_ ECM_HS SG_ 1279 ClmCntMinTrgtClntTmp 1;
BA_REL_ "GenSigTimeoutTime" BU_SG_REL_ ECM_HS SG_ 1279 ClmCntHtrMinFlwRtRq 2500;
BA_REL_ "GenSigTimeoutMsg" BU_SG_REL_ ECM_HS SG_ 1279 ClmCntHtrMinFlwRtRq 1279;
BA_REL_ "GenSigVDAFailComment" BU_SG_REL_ ECM_HS SG_ 1279 ClmCntHtrMinFlwRtRq "ClmCntHtrMinFlwRtRqVDA";
BA_REL_ "GenSigVDAFailResp" BU_SG_REL_ ECM_HS SG_ 1279 ClmCntHtrMinFlwRtRq 1;
BA_REL_ "GenSigSuprvRespSubValue" BU_SG_REL_ ECM_HS SG_ 1279 ClmCntHtrMinFlwRtRq 47;
BA_REL_ "GenSigSuprvResp" BU_SG_REL_ ECM_HS SG_ 1279 ClmCntHtrMinFlwRtRq 2;
BA_REL_ "GenSigTimeoutTime" BU_SG_REL_ ECM_HS SG_ 1277 PrkHtrCoolntTemp 2500;
BA_REL_ "GenSigTimeoutMsg" BU_SG_REL_ ECM_HS SG_ 1277 PrkHtrCoolntTemp 1277;
BA_REL_ "GenSigSuprvResp" BU_SG_REL_ ECM_HS SG_ 1277 PrkHtrCoolntTemp 1;
BA_REL_ "GenSigTimeoutTime" BU_SG_REL_ ECM_HS SG_ 1277 PrkHtrAtv 2500;
BA_REL_ "GenSigTimeoutMsg" BU_SG_REL_ ECM_HS SG_ 1277 PrkHtrAtv 1277;
BA_REL_ "GenSigSuprvResp" BU_SG_REL_ ECM_HS SG_ 1277 PrkHtrAtv 1;
BA_REL_ "GenSigTimeoutTime" BU_SG_REL_ ECM_HS SG_ 1277 PrkHtrActvTm 2500;
BA_REL_ "GenSigTimeoutMsg" BU_SG_REL_ ECM_HS SG_ 1277 PrkHtrActvTm 1277;
BA_REL_ "GenSigSuprvResp" BU_SG_REL_ ECM_HS SG_ 1277 PrkHtrActvTm 1;
BA_REL_ "GenSigTimeoutTime" BU_SG_REL_ ECM_HS SG_ 1277 PrkHtrOffTm 2500;
BA_REL_ "GenSigTimeoutMsg" BU_SG_REL_ ECM_HS SG_ 1277 PrkHtrOffTm 1277;
BA_REL_ "GenSigSuprvResp" BU_SG_REL_ ECM_HS SG_ 1277 PrkHtrOffTm 1;
BA_REL_ "GenSigTimeoutTime" BU_SG_REL_ ECM_HS SG_ 1277 CCFrBlwFnSpdFbkORLFS 2500;
BA_REL_ "GenSigTimeoutMsg" BU_SG_REL_ ECM_HS SG_ 1277 CCFrBlwFnSpdFbkORLFS 1277;
BA_REL_ "GenSigSuprvResp" BU_SG_REL_ ECM_HS SG_ 1277 CCFrBlwFnSpdFbkORLFS 1;
BA_REL_ "GenSigTimeoutTime" BU_SG_REL_ ECM_HS SG_ 1277 CCFrBlwFnSpdFbkORHFS 2500;
BA_REL_ "GenSigTimeoutMsg" BU_SG_REL_ ECM_HS SG_ 1277 CCFrBlwFnSpdFbkORHFS 1277;
BA_REL_ "GenSigSuprvResp" BU_SG_REL_ ECM_HS SG_ 1277 CCFrBlwFnSpdFbkORHFS 1;
BA_REL_ "GenSigTimeoutTime" BU_SG_REL_ ECM_HS SG_ 1277 CCFrBlwFnSpdFbkDyCy 2500;
BA_REL_ "GenSigTimeoutMsg" BU_SG_REL_ ECM_HS SG_ 1277 CCFrBlwFnSpdFbkDyCy 1277;
BA_REL_ "GenSigSuprvResp" BU_SG_REL_ ECM_HS SG_ 1277 CCFrBlwFnSpdFbkDyCy 1;
BA_REL_ "GenSigTimeoutTime" BU_SG_REL_ ECM_HS SG_ 1277 CCFrBlwFnSpdFbkFrq 2500;
BA_REL_ "GenSigTimeoutMsg" BU_SG_REL_ ECM_HS SG_ 1277 CCFrBlwFnSpdFbkFrq 1277;
BA_REL_ "GenSigSuprvResp" BU_SG_REL_ ECM_HS SG_ 1277 CCFrBlwFnSpdFbkFrq 1;
BA_REL_ "GenSigTimeoutTime" BU_SG_REL_ EBCM_HS SG_ 1323 TireLRTmp 2500;
BA_REL_ "GenSigTimeoutMsg" BU_SG_REL_ EBCM_HS SG_ 1323 TireLRTmp 1323;
BA_REL_ "GenSigSuprvResp" BU_SG_REL_ EBCM_HS SG_ 1323 TireLRTmp 1;
BA_REL_ "GenSigTimeoutTime" BU_SG_REL_ RDCM_HS SG_ 1323 TireLRTmp 2500;
BA_REL_ "GenSigTimeoutMsg" BU_SG_REL_ RDCM_HS SG_ 1323 TireLRTmp 1323;
BA_REL_ "GenSigSuprvResp" BU_SG_REL_ RDCM_HS SG_ 1323 TireLRTmp 1;
BA_REL_ "GenSigTimeoutTime" BU_SG_REL_ EBCM_HS SG_ 1323 TireLFTmp 2500;
BA_REL_ "GenSigTimeoutMsg" BU_SG_REL_ EBCM_HS SG_ 1323 TireLFTmp 1323;
BA_REL_ "GenSigSuprvResp" BU_SG_REL_ EBCM_HS SG_ 1323 TireLFTmp 1;
BA_REL_ "GenSigTimeoutTime" BU_SG_REL_ RDCM_HS SG_ 1323 TireLFTmp 2500;
BA_REL_ "GenSigTimeoutMsg" BU_SG_REL_ RDCM_HS SG_ 1323 TireLFTmp 1323;
BA_REL_ "GenSigSuprvResp" BU_SG_REL_ RDCM_HS SG_ 1323 TireLFTmp 1;
BA_REL_ "GenSigTimeoutTime" BU_SG_REL_ EBCM_HS SG_ 1323 TireRRTmp 2500;
BA_REL_ "GenSigTimeoutMsg" BU_SG_REL_ EBCM_HS SG_ 1323 TireRRTmp 1323;
BA_REL_ "GenSigSuprvResp" BU_SG_REL_ EBCM_HS SG_ 1323 TireRRTmp 1;
BA_REL_ "GenSigTimeoutTime" BU_SG_REL_ RDCM_HS SG_ 1323 TireRRTmp 2500;
BA_REL_ "GenSigTimeoutMsg" BU_SG_REL_ RDCM_HS SG_ 1323 TireRRTmp 1323;
BA_REL_ "GenSigSuprvResp" BU_SG_REL_ RDCM_HS SG_ 1323 TireRRTmp 1;
BA_REL_ "GenSigTimeoutTime" BU_SG_REL_ EBCM_HS SG_ 1323 TireRFTmp 2500;
BA_REL_ "GenSigTimeoutMsg" BU_SG_REL_ EBCM_HS SG_ 1323 TireRFTmp 1323;
BA_REL_ "GenSigSuprvResp" BU_SG_REL_ EBCM_HS SG_ 1323 TireRFTmp 1;
BA_REL_ "GenSigTimeoutTime" BU_SG_REL_ RDCM_HS SG_ 1323 TireRFTmp 2500;
BA_REL_ "GenSigTimeoutMsg" BU_SG_REL_ RDCM_HS SG_ 1323 TireRFTmp 1323;
BA_REL_ "GenSigSuprvResp" BU_SG_REL_ RDCM_HS SG_ 1323 TireRFTmp 1;
BA_REL_ "GenSigTimeoutTime" BU_SG_REL_ ECM_HS SG_ 1221 CCClntCrcFlwRtReqVDA 1250;
BA_REL_ "GenSigTimeoutMsg" BU_SG_REL_ ECM_HS SG_ 1221 CCClntCrcFlwRtReqVDA 1221;
BA_REL_ "GenSigSuprvResp" BU_SG_REL_ ECM_HS SG_ 1221 CCClntCrcFlwRtReqVDA 1;
BA_REL_ "GenSigTimeoutTime" BU_SG_REL_ ECM_HS SG_ 1221 PTExPrtclFltManRgnRqd 1250;
BA_REL_ "GenSigTimeoutMsg" BU_SG_REL_ ECM_HS SG_ 1221 PTExPrtclFltManRgnRqd 1221;
BA_REL_ "GenSigSuprvResp" BU_SG_REL_ ECM_HS SG_ 1221 PTExPrtclFltManRgnRqd 1;
BA_REL_ "GenSigTimeoutTime" BU_SG_REL_ ECM_HS SG_ 1221 SpdLmtVsnFsdSpdUnt 1250;
BA_REL_ "GenSigTimeoutMsg" BU_SG_REL_ ECM_HS SG_ 1221 SpdLmtVsnFsdSpdUnt 1221;
BA_REL_ "GenSigSuprvResp" BU_SG_REL_ ECM_HS SG_ 1221 SpdLmtVsnFsdSpdUnt 1;
BA_REL_ "GenSigTimeoutTime" BU_SG_REL_ ECM_HS SG_ 1221 SpdLmtVnFsSpdNwDet 1250;
BA_REL_ "GenSigTimeoutMsg" BU_SG_REL_ ECM_HS SG_ 1221 SpdLmtVnFsSpdNwDet 1221;
BA_REL_ "GenSigSuprvResp" BU_SG_REL_ ECM_HS SG_ 1221 SpdLmtVnFsSpdNwDet 1;
BA_REL_ "GenSigTimeoutTime" BU_SG_REL_ ECM_HS SG_ 1221 SpdLmtVsnFsdSpd 1250;
BA_REL_ "GenSigTimeoutMsg" BU_SG_REL_ ECM_HS SG_ 1221 SpdLmtVsnFsdSpd 1221;
BA_REL_ "GenSigSuprvResp" BU_SG_REL_ ECM_HS SG_ 1221 SpdLmtVsnFsdSpd 1;
BA_REL_ "GenSigTimeoutTime" BU_SG_REL_ ECM_HS SG_ 1221 CCClntCrcFlwRtReq 1250;
BA_REL_ "GenSigTimeoutMsg" BU_SG_REL_ ECM_HS SG_ 1221 CCClntCrcFlwRtReq 1221;
BA_REL_ "GenSigVDAFailComment" BU_SG_REL_ ECM_HS SG_ 1221 CCClntCrcFlwRtReq "CCClntCrcFlwRtReqVDA";
BA_REL_ "GenSigVDAFailResp" BU_SG_REL_ ECM_HS SG_ 1221 CCClntCrcFlwRtReq 1;
BA_REL_ "GenSigSuprvRespSubValue" BU_SG_REL_ ECM_HS SG_ 1221 CCClntCrcFlwRtReq 254;
BA_REL_ "GenSigSuprvResp" BU_SG_REL_ ECM_HS SG_ 1221 CCClntCrcFlwRtReq 2;
VAL_ 985 ManTransIndReq 3 "Indication 3" 2 "Indication 2" 1 "Indication 1" 0 "No Indication" ;
VAL_ 985 EngIntkArBstPrExtRngV 1 "Invalid" 0 "Valid" ;
VAL_ 985 EDADS_RcmndtFwdGr 15 "Unused and Reserved 7" 14 "Unused and Reserved 6" 13 "Unused and Reserved 5" 12 "Unused and Reserved 4" 11 "Unused and Reserved 3" 10 "Tenth Gear" 9 "Ninth Gear" 8 "Eighth Gear" 7 "Seventh Gear" 6 "Sixth Gear" 5 "Fifth Gear" 4 "Fourth Gear" 3 "Third Gear" 2 "Second Gear" 1 "First Gear" 0 "None" ;
VAL_ 985 EDADS_CrntFwdMsdG 15 "Unused and Reserved 7" 14 "Unused and Reserved 6" 13 "Unused and Reserved 5" 12 "Unused and Reserved 4" 11 "Unused and Reserved 3" 10 "Tenth Gear" 9 "Ninth Gear" 8 "Eighth Gear" 7 "Seventh Gear" 6 "Sixth Gear" 5 "Fifth Gear" 4 "Fourth Gear" 3 "Third Gear" 2 "Second Gear" 1 "First Gear" 0 "None" ;
VAL_ 985 EDADS_ShftIndStat 2 "No Shift" 1 "Shift Up" 0 "Shift Down" ;
VAL_ 985 EDADS_EcoDrvShftIO 1 "true" 0 "false" ;
VAL_ 1017 ACRfHiSdFldPrsV 1 "Invalid" 0 "Valid" ;
VAL_ 1017 GenStptDtCycPtOvrAct 1 "true" 0 "false" ;
VAL_ 1017 VehTopSpdLmtMdAct 1 "true" 0 "false" ;
VAL_ 1017 GenFldDutCycV 1 "Invalid" 0 "Valid" ;
VAL_ 1017 GenFld 1 "true" 0 "false" ;
VAL_ 1017 FlInjRlCtRstOcc 1 "true" 0 "false" ;
VAL_ 1017 EngSpdLmtnMdAct 1 "true" 0 "false" ;
VAL_ 977 AutoMdSpdLmtStat 0 "No Speed Limit Change" 1 "Proposed Speed Limit Change" 2 "Accepted Speed Limit Change" 3 "Declined Speed Limit Change" ;
VAL_ 977 FuelFltLifRstPerf 1 "true" 0 "false" ;
VAL_ 977 SpdLmtrSpdWrngAct 1 "true" 0 "false" ;
VAL_ 977 CrsCntlDrSelSpdAct 1 "true" 0 "false" ;
VAL_ 977 ACCompCmnd 1 "On" 0 "Off" ;
VAL_ 977 EngBstPrsIndV 1 "Invalid" 0 "Valid" ;
VAL_ 977 ThrPosV 1 "Invalid" 0 "Valid" ;
VAL_ 977 EngOilStrvtnIO 1 "true" 0 "false" ;
VAL_ 977 EngNEmsnsRelMalfAct 1 "true" 0 "false" ;
VAL_ 977 EngEmsRelMalfIndReq 4 "Flashing 0.5 Hertz Indication" 3 "Flashing 2 Hertz Indication" 2 "Flashing 1 Hertz Indication" 1 "No Indication" 0 "Continuous Indication" ;
VAL_ 977 EngCstFlCutAct 1 "true" 0 "false" ;
VAL_ 201 EngCylDactEvntPndg 1 "true" 0 "false" ;
VAL_ 201 PT_BrkPedDscrtInpStatV 1 "Invalid" 0 "Valid" ;
VAL_ 201 PT_BrkPedDscrtInpStat 1 "Brake Applied" 0 "Brake Not Applied" ;
VAL_ 201 PT_CrnkAct 1 "true" 0 "false" ;
VAL_ 201 Eng12vStrtrMtrCmmdOn 1 "true" 0 "false" ;
VAL_ 201 EngCntrlRunCrnkTrmSt 1 "Active" 0 "Inactive" ;
VAL_ 201 EngAirIntBstPrV 1 "Invalid" 0 "Valid" ;
VAL_ 201 SpdLmtrSpdWrngEnbld 1 "true" 0 "false" ;
VAL_ 201 EngCylDeactMd 3 "Reactivation In Progress" 2 "Half of Total Cylinders Active" 1 "Deactivation In Progress" 0 "All Cylinders Active" ;
VAL_ 201 RmVhStrtEngRng 1 "true" 0 "false" ;
VAL_ 201 PFEngSpdCmndSpcd 1 "true" 0 "false" ;
VAL_ 201 PltfrmEngSpdCmdInhtRq 1 "Inhibit Platform Eng. Speed Control" 0 "Allow Platform Engine Speed Control" ;
VAL_ 201 CrsCntEnbld 1 "true" 0 "false" ;
VAL_ 201 CrsCntAtv 1 "true" 0 "false" ;
VAL_ 201 DrvThrottlOvrrdDet 1 "true" 0 "false" ;
VAL_ 201 PTRunAbrt 1 "true" 0 "false" ;
VAL_ 201 PTO_PT_RunAbrtd 0 "false" 1 "true" ;
VAL_ 201 PTCrnkAbrted 1 "true" 0 "false" ;
VAL_ 201 EngSpdStat 3 "Invalid" 1 "Degraded Operation" 0 "Normal Operation" ;
VAL_ 201 EngRunAtv 1 "true" 0 "false" ;
VAL_ 201 EngIdlAtv 1 "true" 0 "false" ;
VAL_ 201 AccActPosV 1 "Invalid" 0 "Valid" ;
VAL_ 501 TrnsPattSelEcnMdOCm 1 "true" 0 "false" ;
VAL_ 501 TrnsFldPrsPrsnt 1 "true" 0 "false" ;
VAL_ 501 TrnsTrqCnvCltCmndMd 7 "Not Supported" 3 "Locked" 2 "Controlled Slip" 1 "Transitioning" 0 "Unlocked" ;
VAL_ 501 CltchPdlActPosV 1 "Invalid" 0 "Valid" ;
VAL_ 501 AutoTransGrSftDirect 2 "Downshift in Progress" 1 "Upshift in Progress" 0 "No Shift in Progress" ;
VAL_ 501 ElcRngSelDrvAct 1 "true" 0 "false" ;
VAL_ 501 TmpDrvrShftCtlAct 1 "true" 0 "false" ;
VAL_ 501 EngRecDwnshftIO 1 "true" 0 "false" ;
VAL_ 501 CltStartSwAtvV 1 "Invalid" 0 "Valid" ;
VAL_ 501 CltStartSwAtv 1 "true" 0 "false" ;
VAL_ 501 PropSysBrkLitsReqd 1 "true" 0 "false" ;
VAL_ 501 TrnsEngdStateV 1 "Invalid" 0 "Valid" ;
VAL_ 501 TrnsEngdState 3 "Operating State Not Reached" 2 "Transmission Engaged in Reverse" 1 "Transmission Engaged in Forward" 0 "Transmission Not Engaged" ;
VAL_ 501 TrnsShftLvrLckRqd 1 "true" 0 "false" ;
VAL_ 501 TransTUDMdStat 2 "Electronic Range Select Active" 1 "Driver Shift Control Active" 0 "No Activation" ;
VAL_ 501 TrnCrpMdAtv 1 "true" 0 "false" ;
VAL_ 501 TrnsSkpShftIO 1 "true" 0 "false" ;
VAL_ 501 TrnsSftMdStat 3 "Automatic Grade Braking Mode" 2 "Lift-Foot Cornering Mode" 1 "Performance Mode" 0 "No Override Mode" ;
VAL_ 501 TrnsRngInhbtStat 4 "Diagnostic Inhibit Active" 3 "Driveline Not Engaged" 2 "Transmission Range Re-Selection Req" 1 "Transmission Inhibit Active" 0 "No Range Inhibit Active" ;
VAL_ 501 TopTrvlCltchSwActV 1 "Invalid" 0 "Valid" ;
VAL_ 501 TopTrvlCltchSwAct 1 "true" 0 "false" ;
VAL_ 501 EngRecmndUpshftIO 1 "true" 0 "false" ;
VAL_ 501 DrvtShftCntrlTrgtGear 10 "Tenth Gear" 9 "Ninth Gear" 8 "Eighth Gear" 7 "Seventh Gear" 6 "Sixth Gear" 5 "Fifth Gear" 4 "Fourth Gear" 3 "Third Gear" 2 "Second Gear" 1 "First Gear" 0 "Not Supported" ;
VAL_ 501 DrShftCntrlReqDndIO 1 "true" 0 "false" ;
VAL_ 501 TrnShftPtrnActStat 6 "PT Protection Pattern Active" 5 "PT Non-Protection Pattern Active" 4 "Shift Pattern 4 Active" 3 "Shift Pattern 3 Active" 2 "Shift Pattern 2 Active" 1 "Shift Pattern 1 Active" 0 "Default Shift Pattern Active" ;
VAL_ 501 TrnsShftLvrPos 13 "Forward Range J" 12 "Froward Range I" 15 "Lever Position Unknown" 11 "Forward Range H" 10 "Forward Range G" 9 "Forward Range F" 8 "Forward Range E" 7 "Forward Range D" 6 "Forward Range C" 5 "Forward Range B" 4 "Forward Range A" 3 "Neutral Range" 2 "Reverse Range" 1 "Park Range" 0 "Between Ranges" ;
VAL_ 501 TrnsShftLvrPosV 1 "Invalid" 0 "Valid" ;
VAL_ 501 AutoTransComndGear 9 "Ninth Gear" 15 "Park Gear" 14 "Reverse Gear" 13 "Neutral Gear" 12 "CVT Forward Gear" 11 "Unused and Reserved" 10 "Tenth Gear" 8 "Eighth Gear" 7 "Seventh Gear" 6 "Sixth Gear" 5 "Fifth Gear" 4 "Fourth Gear" 3 "Third Gear" 2 "Second Gear" 1 "First Gear" 0 "Not Supported" ;
VAL_ 501 TransEstGear 9 "Ninth Gear" 15 "Park Gear" 14 "Reverse Gear" 13 "Neutral Gear" 12 "CVT Forward Gear" 11 "Unused and Reserved" 10 "Tenth Gear" 8 "Eighth Gear" 7 "Seventh Gear" 6 "Sixth Gear" 5 "Fifth Gear" 4 "Fourth Gear" 3 "Third Gear" 2 "Second Gear" 1 "First Gear" 0 "Not Supported" ;
VAL_ 501 TransEstGearV 1 "Invalid" 0 "Valid" ;
VAL_ 1225 TrnsEmisRlFrzFrmStrSt 3 "Reserved" 2 "Full" 1 "Pending" 0 "Empty" ;
VAL_ 1225 RrPTCoolFanRatFltStat 0 "Indeterminate" 1 "Pass" 2 "Fail" 3 "Reserved and Unused" ;
VAL_ 1225 TERDTC_SysDes 15 "U3-Network Codes Reserved" 14 "U2-Network Codes Reserved" 13 "U1-Network Codes MFG Controlled" 12 "U0-Network Codes SAE Controlled" 11 "B3-Body Codes Reserved" 10 "B2-Body Codes Reserved" 9 "B1-Body Codes MFG Controlled" 8 "B0-Body Codes SAE Controlled" 7 "C3-Chassis Codes Reserved" 6 "C2-Chassis Codes Reserved" 5 "C1-Chassis Codes MFG Controlled" 4 "C0-Chassis Codes SAE Controlled" 3 "P3-Powertrain Codes Reserved" 2 "P2-Powertrain Codes Reserved" 1 "P1-Powertrain Codes MFG Controlled" 0 "P0-Powertrain Codes SAE Controlled" ;
VAL_ 1225 TCTPIR_DrvNotfn 15 "Indication 15" 14 "Indication 14" 13 "Indication 13" 12 "Indication 12" 11 "Indication 11" 10 "Indication 10" 9 "Indication 9" 8 "Indication 8" 7 "Indication 7" 6 "Indication 6" 5 "Indication 5" 4 "Indication 4" 3 "Indication 3" 2 "Indication 2" 1 "Indication 1" 0 "No Indication" ;
VAL_ 1225 GrdBrkgAct 1 "true" 0 "false" ;
VAL_ 1225 TrnsThrmlMngmntStat 2 "Driver Intervention Requested" 1 "Countermeasures Active" 0 "Normal" ;
VAL_ 1225 TrnsNEmsRltMalfActv 1 "true" 0 "false" ;
VAL_ 1225 TransOilTempSensPres 1 "true" 0 "false" ;
VAL_ 1225 TrnEmsMlfAtv 1 "true" 0 "false" ;
VAL_ 1225 TrnOilTmpV 1 "Invalid" 0 "Valid" ;
VAL_ 413 TrnsCyDactTransStat 2 "Ready for Half of TotalCylinders" 1 "Ready for All Cylinders" 0 "Not Ready" ;
VAL_ 413 EngBrkDsblReqd 1 "true" 0 "false" ;
VAL_ 413 TrnsRtoCntlSysFlt 1 "true" 0 "false" ;
VAL_ 413 TrnTrbAngVlV 1 "Invalid" 0 "Valid" ;
VAL_ 413 TrnGrRatV 1 "Invalid" 0 "Valid" ;
VAL_ 413 TrnPrfAlgShfAtv 1 "true" 0 "false" ;
VAL_ 413 TESR_EngSpdCntlRsp 3 "Stability Optimized Condition 2" 2 "Stability Optimized Condition 1" 1 "Transient Optimized" 0 "No Suggestion" ;
VAL_ 413 TESR_EngSpdIntTyp 3 "Engine Speed Max and Min Limit" 2 "Engine Speed Min Limit" 1 "Engine Speed Max Limit" 0 "No Intervention" ;
VAL_ 413 TrnsGrgShftAct 1 "true" 0 "false" ;
VAL_ 413 TransNtrlCntrlMdStat 3 "Exiting Neutral Control" 2 "Neutral Control Active" 1 "Entering Neutral Control" 0 "Neutral Control Not Active" ;
VAL_ 197 WRSLNDWhlRotStRst 1 "true" 0 "false" ;
VAL_ 197 WRSLNDWhlDistVal 1 "Invalid" 0 "Valid" ;
VAL_ 197 WRSRNDWhlRotStRst 1 "true" 0 "false" ;
VAL_ 197 WRSRNDWhlDistVal 1 "Invalid" 0 "Valid" ;
VAL_ 840 WhlRotDrctnlStLftDrvn 0 "Unknown" 1 "Forward" 2 "Reverse" 3 "Not Supported" 4 "Failed" 5 "Reserved 1" 6 "Reserved 2" 7 "Reserved 3" ;
VAL_ 840 WhlRotDrctnlStRtDrvn 0 "Unknown" 1 "Forward" 2 "Reverse" 3 "Not Supported" 4 "Failed" 5 "Reserved 1" 6 "Reserved 2" 7 "Reserved 3" ;
VAL_ 840 WhlGrndVlctyRtDrvnV 1 "Invalid" 0 "Valid" ;
VAL_ 840 WhlGrndVlctyLftDrvnV 1 "Invalid" 0 "Valid" ;
VAL_ 193 WRSLDWhlDistVal 1 "Invalid" 0 "Valid" ;
VAL_ 193 WRSLDWhlRotStatRst 1 "true" 0 "false" ;
VAL_ 193 WRSRDWhlRotStatRst 1 "true" 0 "false" ;
VAL_ 193 WRSRDWhlDistVal 1 "Invalid" 0 "Valid" ;
VAL_ 761 BrkSysHRBkCtrlAvail 1 "true" 0 "false" ;
VAL_ 761 BrkSysHRBkCtrlStat 0 "Inactive" 1 "Control Target Vehicle Speed" 2 "Unused and Reserved 1" 3 "Unused and Reserved 2" ;
VAL_ 761 BrkSysHSAAval 1 "true" 0 "false" ;
VAL_ 761 BrkSysHSAStat 0 "Inactive" 1 "Brake Pressure Hold" 2 "Normal Pressure Decay" 3 "Drive-off Pressure Decay" ;
VAL_ 761 HillDscntCtrlStat 0 "Not Enabled" 1 "Enabled" 2 "Active" 3 "Unused" ;
VAL_ 761 ABFI_CollPrepSysInhbt 1 "true" 0 "false" ;
VAL_ 761 ABFI_RrVirtlBmprInh 1 "true" 0 "false" ;
VAL_ 761 CAVHS_ACHActv 1 "true" 0 "false" ;
VAL_ 761 CAVHS_DSHEnbld 1 "true" 0 "false" ;
VAL_ 761 CAVHS_DSHActv 1 "true" 0 "false" ;
VAL_ 761 BrkPdlDrvApplPresV 1 "Invalid" 0 "Valid" ;
VAL_ 761 AutoBrkPTReqStat 0 "Inactive" 1 "Active" 2 "Failed" 3 "Serial Communication Failure" 4 "Unused and Reserved 1" 5 "Unused and Reserved 2" 6 "Unused and Reserved 3" 7 "Unused and Reserved 4" ;
VAL_ 761 WhlSpdSnsgDTCStat 4 "Diagnostic Failed" 3 "Diagnostic Passed" 2 "No Status to Report" 1 "Critically Disabled" 0 "Not Supported" ;
VAL_ 761 SprTireSt 2 "Spare Detected" 1 "No Spare Detected" 0 "Undetermined" ;
VAL_ 489 EnhDrvMdSwChUseRq 1 "true" 0 "false" ;
VAL_ 489 IMUDataMsk 1 "true" 0 "false" ;
VAL_ 489 DrvIndpntBrkAppAct 1 "true" 0 "false" ;
VAL_ 489 WhlSlpSt 3 "Slip Detection Fault" 2 "Positive Slip Detected" 1 "Negative Slip Detected" 0 "No Slip Detected" ;
VAL_ 489 BSTGRReqdGear 10 "Tenth Gear" 9 "Ninth Gear" 8 "Eighth Gear" 7 "Seventh Gear" 6 "Sixth Gear" 5 "Fifth Gear" 4 "Fourth Gear" 3 "Third Gear" 2 "Second Gear" 1 "First Gear" 0 "No Action" ;
VAL_ 489 BSTGRReqType 3 "Hold Gear" 2 "Min Gear Request" 1 "Max Gear Request" 0 "No Action" ;
VAL_ 489 VhDynCntlSysSt 7 "Driver Disabled" 6 "Enhanced Operation" 5 "Calibrating" 4 "Warming Up" 3 "Permanently Failed" 2 "Temporarily Inhibited" 1 "Reduced Function" 0 "Normal Operation" ;
VAL_ 489 TrnsBrkSysCltchRelRqd 1 "true" 0 "false" ;
VAL_ 489 TracCntrlSysDrIntnt 1 "Enabled" 0 "Disabled" ;
VAL_ 489 VehDynOvrUndrStrV 1 "Invalid" 0 "Valid" ;
VAL_ 489 TCSysEnbld 1 "true" 0 "false" ;
VAL_ 489 BrkPdlDrvAppPrsDetcdV 1 "Invalid" 0 "Valid" ;
VAL_ 489 BrkPdlDrvAppPrsDetcd 1 "true" 0 "false" ;
VAL_ 489 ACCBrkngAct 1 "true" 0 "false" ;
VAL_ 489 ABSFld 1 "true" 0 "false" ;
VAL_ 489 VSELatAccV 1 "Invalid" 0 "Valid" ;
VAL_ 489 VSEAct 1 "true" 0 "false" ;
VAL_ 489 VehDynYawRateV 1 "Invalid" 0 "Valid" ;
VAL_ 489 TCSysAtv 1 "true" 0 "false" ;
VAL_ 489 ABSAtv 1 "true" 0 "false" ;
VAL_ 381 BrkSysStCrwlModeOvrrd 3 "Unused And Reserved" 2 "Override To Crawl" 1 "Override To Not Crawl" 0 "No Override" ;
VAL_ 381 BrkSysVTopSpdLimIO 1 "true" 0 "false" ;
VAL_ 381 ABSActIO 1 "true" 0 "false" ;
VAL_ 381 BrkPdLfStatIndRq 5 "Service" 4 "Disabled" 3 "Change Now" 2 "Change Soon" 1 "Ok" 0 "Not Present" ;
VAL_ 381 VehStbCmptvMdCstAvl 1 "true" 0 "false" ;
VAL_ 381 VehStbEnmntCstAvl 1 "true" 0 "false" ;
VAL_ 381 VehStbCmptvMdCurSt 1 "On" 0 "Off" ;
VAL_ 381 VehStbEnhmntCurSt 1 "On" 0 "Off" ;
VAL_ 381 TCSTempDsblReqIO 0 "false" 1 "true" ;
VAL_ 381 TCSysCstAvl 1 "true" 0 "false" ;
VAL_ 381 TCSysCurSt 1 "On" 0 "Off" ;
VAL_ 381 TracAndStbScrnCnfg 3 "TCS ESC and Comp" 2 "TCS and ESC" 1 "TCS Only" 0 "None" ;
VAL_ 381 HillDesCtrlRedVehSpIO 1 "true" 0 "false" ;
VAL_ 381 EBDFailed 1 "true" 0 "false" ;
VAL_ 381 StWhAnVDA 1 "VirtualDeviceAvailable" 0 "VirtualDeviceUnavailable" ;
VAL_ 381 TirePrsLowIO 1 "true" 0 "false" ;
VAL_ 381 VaccBoostFailure 1 "true" 0 "false" ;
VAL_ 381 VSESysPrs 1 "true" 0 "false" ;
VAL_ 381 HalfSysFail 1 "true" 0 "false" ;
VAL_ 381 ActVehAccelV 1 "Invalid" 0 "Valid" ;
VAL_ 381 BksOvht 1 "true" 0 "false" ;
VAL_ 381 TCSysPr 1 "true" 0 "false" ;
VAL_ 381 ABSPr 1 "true" 0 "false" ;
VAL_ 381 TreInfMonSysRstPrfmd 1 "true" 0 "false" ;
VAL_ 381 ABSIO 1 "true" 0 "false" ;
VAL_ 381 BrkPadWrnIO 1 "true" 0 "false" ;
VAL_ 381 VehStabEnhmntMd 2 "Competitive" 1 "Normal" 0 "Off" ;
VAL_ 381 VehStabEnhmntStat 4 "Not Ready" 3 "Warming Up" 2 "Fault" 1 "Active" 0 "Inactive" ;
VAL_ 381 TCSysOpMd 2 "Off Road" 1 "Normal" 0 "Off" ;
VAL_ 381 TCSysOpStat 2 "Fault" 1 "Active" 0 "Inactive" ;
VAL_ 381 BrkSysRedBrkTlltlReq 1 "true" 0 "false" ;
VAL_ 381 BrkSysBrkLtsReqd 1 "true" 0 "false" ;
VAL_ 1279 ClmCntHtrMinFlwRtRqVDA 1 "VirtualDeviceAvailable" 0 "VirtualDeviceUnavailable" ;
VAL_ 1279 ClmCntPrtyHtRqV 1 "Invalid" 0 "Valid" ;
VAL_ 1279 ClmCntPrtyHtRq 3 "HIGH" 2 "MEDIUM" 1 "LOW" 0 "NO ACTION" ;
VAL_ 1279 ClmCntCalcTrgtCbnHtLdV 1 "Invalid" 0 "Valid" ;
VAL_ 1279 ClmCntMinTrgtClntTmpV 1 "Invalid" 0 "Valid" ;
VAL_ 1279 ClmCntHtrMinFlwRtRqV 1 "Invalid" 0 "Valid" ;
VAL_ 1277 PrkHtrCoolntTempV 1 "Invalid" 0 "Valid" ;
VAL_ 1277 PrkHtrAtv 1 "true" 0 "false" ;
VAL_ 1277 PrkHtrCoolntTempM 1 "Use Data" 0 "Don't Use Data" ;
VAL_ 1277 PrkHtrActvTmM 1 "Use Data" 0 "Dont Use Data" ;
VAL_ 1277 PrkHtrOffTmM 1 "Use Data" 0 "Dont Use Data" ;
VAL_ 1277 CCFrBlwFnSpdFbkORLFS 2 "Fail" 1 "Pass" 0 "Indeterminate" ;
VAL_ 1277 CCFrBlwFnSpdFbkORHFS 2 "Fail" 1 "Pass" 0 "Indeterminate" ;
VAL_ 1323 TireLRTmpV 1 "Invalid" 0 "Valid" ;
VAL_ 1323 TireLFTmpV 1 "Invalid" 0 "Valid" ;
VAL_ 1323 TireRRTmpV 1 "Invalid" 0 "Valid" ;
VAL_ 1323 TireRFTmpV 1 "Invalid" 0 "Valid" ;
VAL_ 543 HdStV 1 "Invalid" 0 "Valid" ;
VAL_ 543 HdSt 2 "Open" 1 "Ajar" 0 "Closed" ;
VAL_ 543 PTOTpStpSpdCsStReq 0 "No Action" 1 "5 rpm" 2 "10 rpm" 3 "25 rpm" 4 "50 rpm" 5 "100 rpm" 6 "250 rpm" 7 "500 rpm" ;
VAL_ 543 PTOStdbySpdCsStReq 0 "No Action" 1 "900 rpm" 2 "1000 rpm" 3 "1100 rpm" 4 "1200 rpm" 5 "1300 rpm" 6 "1400 rpm" 7 "1500 rpm" ;
VAL_ 543 PTOEngRnTmrCsStRq 0 "No Action" 1 "10 min" 2 "30 min" 3 "90 min" 4 "120 min" 5 "150 min" 6 "180 min" 7 "210 min" 8 "240 min" 9 "270 min" 10 "300 min" 11 "330 min" 12 "360 min" 13 "390 min" 14 "420 min" 15 "450 min" ;
VAL_ 543 PTOSet2SpdCsStReq 0 "No Action" 1 "1900 rpm" 2 "2000 rpm" 3 "2100 rpm" 4 "2200 rpm" 5 "2300 rpm" 6 "2400 rpm" 7 "2500 rpm" 8 "2600 rpm" 9 "2700 rpm" 10 "2800 rpm" 11 "2900 rpm" 12 "3000 rpm" 13 "3100 rpm" 14 "3200 rpm" 15 "3300 rpm" ;
VAL_ 543 PTOSet1SpdCsStReq 0 "No Action" 1 "1100 rpm" 2 "1200 rpm" 3 "1300 rpm" 4 "1400 rpm" 5 "1500 rpm" 6 "1600 rpm" 7 "1700 rpm" 8 "1800 rpm" 9 "1900 rpm" 10 "2000 rpm" 11 "2100 rpm" 12 "2200 rpm" 13 "2300 rpm" 14 "2400 rpm" 15 "2500 rpm" ;
VAL_ 1221 CCClntCrcFlwRtReqVDA 1 "VirtualDeviceAvailable" 0 "VirtualDeviceUnavailable" ;
VAL_ 1221 PTExPrtclFltManRgnRqd 1 "true" 0 "false" ;
VAL_ 1221 SpdLmtVsnFsdSpdUnt 0 "km/h" 1 "mph" ;
VAL_ 1221 SpdLmtVnFsSpdNwDet 1 "true" 0 "false" ;
VAL_ 1221 SpdLmtVsnFsdSpdM 0 "Don't Use Data" 1 "Use Data" ;
VAL_ 1239 BattSOXStat 1 "Use SOC,SOH, & SOF" 0 "Don't Use SOC,SOH, & SOF" ;
VAL_ 1239 BattTempV 1 "Invalid" 0 "Valid" ;
VAL_ 971 BatVltHiResV 1 "Invalid" 0 "Valid" ;
VAL_ 971 BCHR_BattCrntRwVlMu 3 "Multiplier Factor 256" 2 "Multiplier Factor 64" 1 "Multiplier Factor 8" 0 "Multiplier Factor 1" ;
VAL_ 971 BCHR_BattCrntRwValV 1 "Invalid" 0 "Valid" ;
SIG_GROUP_ 985 ECODrvAsstDsplyStat 1 : EDADS_RcmndtFwdGr EDADS_CrntFwdMsdG EDADS_ShftIndStat EDADS_EcoDrvShftIO;
SIG_GROUP_ 1225 TrnsCltchThrmlProtIndR 1 : TCTPIR_TnsEsClCDwT TCTPIR_TnsEsClTmpD TCTPIR_DrvNotfn;
SIG_GROUP_ 1225 TransEmsnsRelDTC 1 : TERDTC_SysDes TERDTC_CdNum;
SIG_GROUP_ 413 TrnsEngSpdRq 1 : TESR_EngSpdCntlRsp TESR_EngSpdRqVal TESR_EngSpdIntTyp;
SIG_GROUP_ 197 WhlRotStatLftNDrvn 1 : WRSLNDWhlDisTpRC WRSLNDWhlRotStRst WRSLNDWhlDistVal WRSLNDWhlDistTstm WRSLNDWhlDistPCntr WRSLNDSeqNum;
SIG_GROUP_ 197 WhlRotStatRghtNDrvn 1 : WRSRNDWhlDisTpRC WRSRNDWhlRotStRst WRSRNDWhlDistVal WRSRNDWhlDistTstm WRSRNDWhlDistPCntr WRSRNDSeqNum;
SIG_GROUP_ 193 WhlRotatStatLftDrvn 1 : WRSLDWhlDisTpRC WRSLDSeqNum WRSLDWhlDistVal WRSLDWhlRotStatRst WRSLDWhlDistTmstm WRSLDWhlDistPlsCntr;
SIG_GROUP_ 193 WhlRotatStatRtDrvn 1 : WRSRDWhlDisTpRC WRSRDSeqNum WRSRDWhlRotStatRst WRSRDWhlDistVal WRSRDWhlDistTmstm WRSRDWhlDistPlsCntr;
SIG_GROUP_ 761 AutoBrkFeatInhbt 1 : ABFI_CollPrepSysInhbt ABFI_RrVirtlBmprInh;
SIG_GROUP_ 761 ChsAVHStat 1 : CAVHS_ACHActv CAVHS_DSHEnbld CAVHS_DSHActv;
SIG_GROUP_ 761 WhlSpdSnsLgsDiagStat 1 : WhlSpdSnsgDTCIndex WhlSpdSnsgDTCStat;
SIG_GROUP_ 489 BrkSysTransGearReq 1 : BSTGRReqdGear BSTGRReqType;
SIG_GROUP_ 971 BattCrntHiRes 1 : BCHR_BattCrntRwVal BCHR_BattCrntRwVlMu BCHR_BattCrntRwValV;
